VERSION ""

NS_ :

BS_:

BU_:

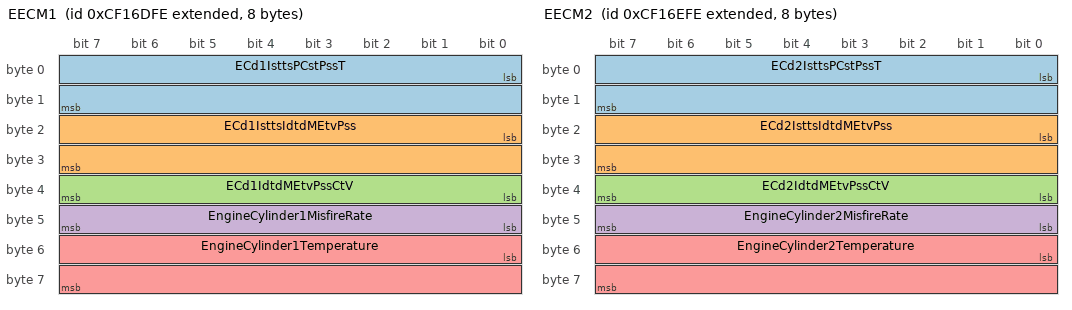
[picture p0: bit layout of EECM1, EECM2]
BO_ 2364632574 EECM1: 8 Vector__XXX
 SG_ ECd1IsttsPCstPssT : 0|16@1+ (0.00390625,-125) [-125|125] "deg" Vector__XXX
 SG_ ECd1IsttsIdtdMEtvPss : 16|16@1+ (0.0001220703125,-1) [-1|6.84362793] "MPa" Vector__XXX
 SG_ ECd1IdtdMEtvPssCtV : 32|8@1+ (0.04,0) [0|10] "%" Vector__XXX
 SG_ EngineCylinder1MisfireRate : 40|8@1+ (0.4,0) [0|100] "%" Vector__XXX
 SG_ EngineCylinder1Temperature : 48|16@1+ (0.03125,-273) [-273|1734.96875] "degC" Vector__XXX

BO_ 2364632830 EECM2: 8 Vector__XXX
 SG_ ECd2IsttsPCstPssT : 0|16@1+ (0.00390625,-125) [-125|125] "deg" Vector__XXX
 SG_ ECd2IsttsIdtdMEtvPss : 16|16@1+ (0.0001220703125,-1) [-1|6.84362793] "MPa" Vector__XXX
 SG_ ECd2IdtdMEtvPssCtV : 32|8@1+ (0.04,0) [0|10] "%" Vector__XXX
 SG_ EngineCylinder2MisfireRate : 40|8@1+ (0.4,0) [0|100] "%" Vector__XXX
 SG_ EngineCylinder2Temperature : 48|16@1+ (0.03125,-273) [-273|1734.96875] "degC" Vector__XXX

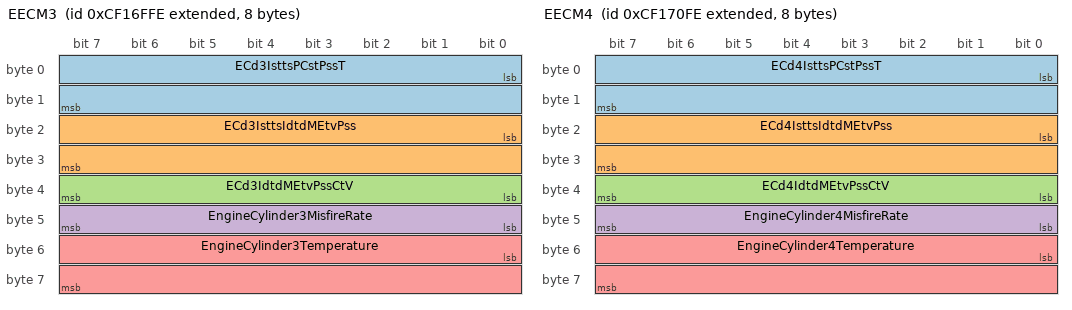
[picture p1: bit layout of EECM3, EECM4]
BO_ 2364633086 EECM3: 8 Vector__XXX
 SG_ ECd3IsttsPCstPssT : 0|16@1+ (0.00390625,-125) [-125|125] "deg" Vector__XXX
 SG_ ECd3IsttsIdtdMEtvPss : 16|16@1+ (0.0001220703125,-1) [-1|6.84362793] "MPa" Vector__XXX
 SG_ ECd3IdtdMEtvPssCtV : 32|8@1+ (0.04,0) [0|10] "%" Vector__XXX
 SG_ EngineCylinder3MisfireRate : 40|8@1+ (0.4,0) [0|100] "%" Vector__XXX
 SG_ EngineCylinder3Temperature : 48|16@1+ (0.03125,-273) [-273|1734.96875] "degC" Vector__XXX

BO_ 2364633342 EECM4: 8 Vector__XXX
 SG_ ECd4IsttsPCstPssT : 0|16@1+ (0.00390625,-125) [-125|125] "deg" Vector__XXX
 SG_ ECd4IsttsIdtdMEtvPss : 16|16@1+ (0.0001220703125,-1) [-1|6.84362793] "MPa" Vector__XXX
 SG_ ECd4IdtdMEtvPssCtV : 32|8@1+ (0.04,0) [0|10] "%" Vector__XXX
 SG_ EngineCylinder4MisfireRate : 40|8@1+ (0.4,0) [0|100] "%" Vector__XXX
 SG_ EngineCylinder4Temperature : 48|16@1+ (0.03125,-273) [-273|1734.96875] "degC" Vector__XXX

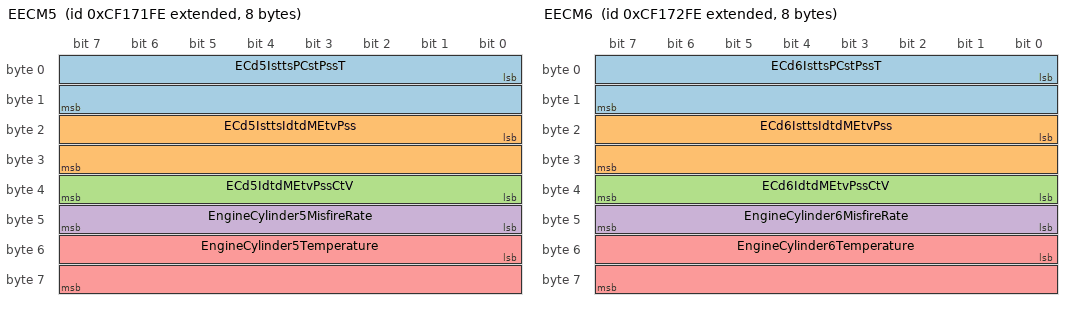
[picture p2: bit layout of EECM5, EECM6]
BO_ 2364633598 EECM5: 8 Vector__XXX
 SG_ ECd5IsttsPCstPssT : 0|16@1+ (0.00390625,-125) [-125|125] "deg" Vector__XXX
 SG_ ECd5IsttsIdtdMEtvPss : 16|16@1+ (0.0001220703125,-1) [-1|6.84362793] "MPa" Vector__XXX
 SG_ ECd5IdtdMEtvPssCtV : 32|8@1+ (0.04,0) [0|10] "%" Vector__XXX
 SG_ EngineCylinder5MisfireRate : 40|8@1+ (0.4,0) [0|100] "%" Vector__XXX
 SG_ EngineCylinder5Temperature : 48|16@1+ (0.03125,-273) [-273|1734.96875] "degC" Vector__XXX

BO_ 2364633854 EECM6: 8 Vector__XXX
 SG_ ECd6IsttsPCstPssT : 0|16@1+ (0.00390625,-125) [-125|125] "deg" Vector__XXX
 SG_ ECd6IsttsIdtdMEtvPss : 16|16@1+ (0.0001220703125,-1) [-1|6.84362793] "MPa" Vector__XXX
 SG_ ECd6IdtdMEtvPssCtV : 32|8@1+ (0.04,0) [0|10] "%" Vector__XXX
 SG_ EngineCylinder6MisfireRate : 40|8@1+ (0.4,0) [0|100] "%" Vector__XXX
 SG_ EngineCylinder6Temperature : 48|16@1+ (0.03125,-273) [-273|1734.96875] "degC" Vector__XXX

BO_ 2364634110 EECM7: 8 Vector__XXX
 SG_ ECd7IsttsPCstPssT : 0|16@1+ (0.00390625,-125) [-125|125] "deg" Vector__XXX
 SG_ ECd7IsttsIdtdMEtvPss : 16|16@1+ (0.0001220703125,-1) [-1|6.84362793] "MPa" Vector__XXX
 SG_ ECd7IdtdMEtvPssCtV : 32|8@1+ (0.04,0) [0|10] "%" Vector__XXX
 SG_ EngineCylinder7MisfireRate : 40|8@1+ (0.4,0) [0|100] "%" Vector__XXX
 SG_ EngineCylinder7Temperature : 48|16@1+ (0.03125,-273) [-273|1734.96875] "degC" Vector__XXX

BO_ 2364634366 EECM8: 8 Vector__XXX
 SG_ ECd8IsttsPCstPssT : 0|16@1+ (0.00390625,-125) [-125|125] "deg" Vector__XXX
 SG_ ECd8IsttsIdtdMEtvPss : 16|16@1+ (0.0001220703125,-1) [-1|6.84362793] "MPa" Vector__XXX
 SG_ ECd8IdtdMEtvPssCtV : 32|8@1+ (0.04,0) [0|10] "%" Vector__XXX
 SG_ EngineCylinder8MisfireRate : 40|8@1+ (0.4,0) [0|100] "%" Vector__XXX
 SG_ EngineCylinder8Temperature : 48|16@1+ (0.03125,-273) [-273|1734.96875] "degC" Vector__XXX

BO_ 2364634622 EECM9: 8 Vector__XXX
 SG_ ECd9IsttsPCstPssT : 0|16@1+ (0.00390625,-125) [-125|125] "deg" Vector__XXX
 SG_ ECd9IsttsIdtdMEtvPss : 16|16@1+ (0.0001220703125,-1) [-1|6.84362793] "MPa" Vector__XXX
 SG_ ECd9IdtdMEtvPssCtV : 32|8@1+ (0.04,0) [0|10] "%" Vector__XXX
 SG_ EngineCylinder9MisfireRate : 40|8@1+ (0.4,0) [0|100] "%" Vector__XXX
 SG_ EngineCylinder9Temperature : 48|16@1+ (0.03125,-273) [-273|1734.96875] "degC" Vector__XXX

BO_ 2364634878 EECM10: 8 Vector__XXX
 SG_ ECd10IsttsPCstPssT : 0|16@1+ (0.00390625,-125) [-125|125] "deg" Vector__XXX
 SG_ ECd10IsttsIdtdMEtvPss : 16|16@1+ (0.0001220703125,-1) [-1|6.84362793] "MPa" Vector__XXX
 SG_ ECd10IdtdMEtvPssCtV : 32|8@1+ (0.04,0) [0|10] "%" Vector__XXX
 SG_ EngineCylinder10MisfireRate : 40|8@1+ (0.4,0) [0|100] "%" Vector__XXX
 SG_ EngineCylinder10Temperature : 48|16@1+ (0.03125,-273) [-273|1734.96875] "degC" Vector__XXX

BO_ 2364635134 EECM11: 8 Vector__XXX
 SG_ ECd11IsttsPCstPssT : 0|16@1+ (0.00390625,-125) [-125|125] "deg" Vector__XXX
 SG_ ECd11IsttsIdtdMEtvPss : 16|16@1+ (0.0001220703125,-1) [-1|6.84362793] "MPa" Vector__XXX
 SG_ ECd11IdtdMEtvPssCtV : 32|8@1+ (0.04,0) [0|10] "%" Vector__XXX
 SG_ EngineCylinder11MisfireRate : 40|8@1+ (0.4,0) [0|100] "%" Vector__XXX
 SG_ EngineCylinder11Temperature : 48|16@1+ (0.03125,-273) [-273|1734.96875] "degC" Vector__XXX

BO_ 2364635390 EECM12: 8 Vector__XXX
 SG_ ECd12IsttsPCstPssT : 0|16@1+ (0.00390625,-125) [-125|125] "deg" Vector__XXX
 SG_ ECd12IsttsIdtdMEtvPss : 16|16@1+ (0.0001220703125,-1) [-1|6.84362793] "MPa" Vector__XXX
 SG_ ECd12IdtdMEtvPssCtV : 32|8@1+ (0.04,0) [0|10] "%" Vector__XXX
 SG_ EngineCylinder12MisfireRate : 40|8@1+ (0.4,0) [0|100] "%" Vector__XXX
 SG_ EngineCylinder12Temperature : 48|16@1+ (0.03125,-273) [-273|1734.96875] "degC" Vector__XXX

BO_ 2364635646 EECM13: 8 Vector__XXX
 SG_ ECd13IsttsPCstPssT : 0|16@1+ (0.00390625,-125) [-125|125] "deg" Vector__XXX
 SG_ ECd13IsttsIdtdMEtvPss : 16|16@1+ (0.0001220703125,-1) [-1|6.84362793] "MPa" Vector__XXX
 SG_ ECd13IdtdMEtvPssCtV : 32|8@1+ (0.04,0) [0|10] "%" Vector__XXX
 SG_ EngineCylinder13MisfireRate : 40|8@1+ (0.4,0) [0|100] "%" Vector__XXX
 SG_ EngineCylinder13Temperature : 48|16@1+ (0.03125,-273) [-273|1734.96875] "degC" Vector__XXX

BO_ 2364635902 EECM14: 8 Vector__XXX
 SG_ ECd14IsttsPCstPssT : 0|16@1+ (0.00390625,-125) [-125|125] "deg" Vector__XXX
 SG_ ECd14IsttsIdtdMEtvPss : 16|16@1+ (0.0001220703125,-1) [-1|6.84362793] "MPa" Vector__XXX
 SG_ ECd14IdtdMEtvPssCtV : 32|8@1+ (0.04,0) [0|10] "%" Vector__XXX
 SG_ EngineCylinder14MisfireRate : 40|8@1+ (0.4,0) [0|100] "%" Vector__XXX
 SG_ EngineCylinder14Temperature : 48|16@1+ (0.03125,-273) [-273|1734.96875] "degC" Vector__XXX

BO_ 2364636158 EECM15: 8 Vector__XXX
 SG_ ECd15IsttsPCstPssT : 0|16@1+ (0.00390625,-125) [-125|125] "deg" Vector__XXX
 SG_ ECd15IsttsIdtdMEtvPss : 16|16@1+ (0.0001220703125,-1) [-1|6.84362793] "MPa" Vector__XXX
 SG_ ECd15IdtdMEtvPssCtV : 32|8@1+ (0.04,0) [0|10] "%" Vector__XXX
 SG_ EngineCylinder15MisfireRate : 40|8@1+ (0.4,0) [0|100] "%" Vector__XXX
 SG_ EngineCylinder15Temperature : 48|16@1+ (0.03125,-273) [-273|1734.96875] "degC" Vector__XXX

BO_ 2364636414 EECM16: 8 Vector__XXX
 SG_ ECd16IsttsPCstPssT : 0|16@1+ (0.00390625,-125) [-125|125] "deg" Vector__XXX
 SG_ ECd16IsttsIdtdMEtvPss : 16|16@1+ (0.0001220703125,-1) [-1|6.84362793] "MPa" Vector__XXX
 SG_ ECd16IdtdMEtvPssCtV : 32|8@1+ (0.04,0) [0|10] "%" Vector__XXX
 SG_ EngineCylinder16MisfireRate : 40|8@1+ (0.4,0) [0|100] "%" Vector__XXX
 SG_ EngineCylinder16Temperature : 48|16@1+ (0.03125,-273) [-273|1734.96875] "degC" Vector__XXX

BO_ 2364636670 EECM17: 8 Vector__XXX
 SG_ ECd17IsttsPCstPssT : 0|16@1+ (0.00390625,-125) [-125|125] "deg" Vector__XXX
 SG_ ECd17IsttsIdtdMEtvPss : 16|16@1+ (0.0001220703125,-1) [-1|6.84362793] "MPa" Vector__XXX
 SG_ ECd17IdtdMEtvPssCtV : 32|8@1+ (0.04,0) [0|10] "%" Vector__XXX
 SG_ EngineCylinder17MisfireRate : 40|8@1+ (0.4,0) [0|100] "%" Vector__XXX
 SG_ EngineCylinder17Temperature : 48|16@1+ (0.03125,-273) [-273|1734.96875] "degC" Vector__XXX

BO_ 2364636926 EECM18: 8 Vector__XXX
 SG_ ECd18IsttsPCstPssT : 0|16@1+ (0.00390625,-125) [-125|125] "deg" Vector__XXX
 SG_ ECd18IsttsIdtdMEtvPss : 16|16@1+ (0.0001220703125,-1) [-1|6.84362793] "MPa" Vector__XXX
 SG_ ECd18IdtdMEtvPssCtV : 32|8@1+ (0.04,0) [0|10] "%" Vector__XXX
 SG_ EngineCylinder18MisfireRate : 40|8@1+ (0.4,0) [0|100] "%" Vector__XXX
 SG_ EngineCylinder18Temperature : 48|16@1+ (0.03125,-273) [-273|1734.96875] "degC" Vector__XXX

BO_ 2364637182 EECM19: 8 Vector__XXX
 SG_ ECd19IsttsPCstPssT : 0|16@1+ (0.00390625,-125) [-125|125] "deg" Vector__XXX
 SG_ ECd19IsttsIdtdMEtvPss : 16|16@1+ (0.0001220703125,-1) [-1|6.84362793] "MPa" Vector__XXX
 SG_ ECd19IdtdMEtvPssCtV : 32|8@1+ (0.04,0) [0|10] "%" Vector__XXX
 SG_ EngineCylinder19MisfireRate : 40|8@1+ (0.4,0) [0|100] "%" Vector__XXX
 SG_ EngineCylinder19Temperature : 48|16@1+ (0.03125,-273) [-273|1734.96875] "degC" Vector__XXX

BO_ 2364637438 EECM20: 8 Vector__XXX
 SG_ ECd20IsttsPCstPssT : 0|16@1+ (0.00390625,-125) [-125|125] "deg" Vector__XXX
 SG_ ECd20IsttsIdtdMEtvPss : 16|16@1+ (0.0001220703125,-1) [-1|6.84362793] "MPa" Vector__XXX
 SG_ ECd20IdtdMEtvPssCtV : 32|8@1+ (0.04,0) [0|10] "%" Vector__XXX
 SG_ EngineCylinder20MisfireRate : 40|8@1+ (0.4,0) [0|100] "%" Vector__XXX
 SG_ EngineCylinder20Temperature : 48|16@1+ (0.03125,-273) [-273|1734.96875] "degC" Vector__XXX

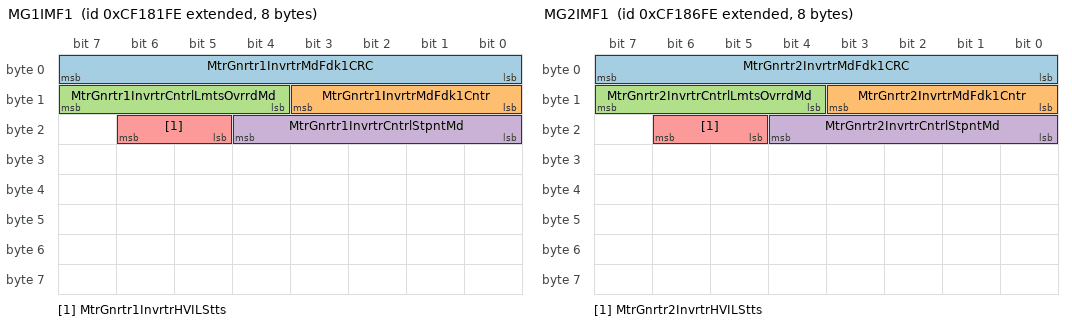
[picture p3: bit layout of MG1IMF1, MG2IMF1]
BO_ 2364637694 MG1IMF1: 8 Vector__XXX
 SG_ MtrGnrtr1InvrtrMdFdk1CRC : 0|8@1+ (1,0) [0|255] "count" Vector__XXX
 SG_ MtrGnrtr1InvrtrMdFdk1Cntr : 8|4@1+ (1,0) [0|15] "" Vector__XXX
 SG_ MtrGnrtr1InvrtrCntrlLmtsOvrrdMd : 12|4@1+ (1,0) [0|15] "" Vector__XXX
 SG_ MtrGnrtr1InvrtrCntrlStpntMd : 16|5@1+ (1,0) [0|31] "" Vector__XXX
 SG_ MtrGnrtr1InvrtrHVILStts : 21|2@1+ (1,0) [0|3] "" Vector__XXX

BO_ 2565964542 MG1ILAP: 8 Vector__XXX
 SG_ MtrGnrtr1InvrtrLmtsAtvPwrCRC : 0|8@1+ (1,0) [0|255] "count" Vector__XXX
 SG_ MtrGnrtr1InvrtrLmtsAtvPwrCntr : 8|4@1+ (1,0) [0|15] "" Vector__XXX

BO_ 2565964798 MG1ILAM: 8 Vector__XXX
 SG_ MtrGnrtr1InvrtrLmtsAtvMhnlCRC : 0|8@1+ (1,0) [0|255] "count" Vector__XXX
 SG_ MtrGnrtr1InvrtrLmtsAtvMhnlCntr : 8|4@1+ (1,0) [0|15] "" Vector__XXX

BO_ 2565965054 MG1ILADC: 8 Vector__XXX
 SG_ MtrGnrtr1InvrtrLmtsAtvDCSdCRC : 0|8@1+ (1,0) [0|255] "count" Vector__XXX
 SG_ MtrGnrtr1InvrtrLmtsAtvDCSdCntr : 8|4@1+ (1,0) [0|15] "" Vector__XXX

BO_ 2565965310 MG1ILV: 8 Vector__XXX
 SG_ MtrGnrtr1InvrtrSwthdIgntnVltg : 0|16@1+ (0.05,0) [0|3212.75] "V" Vector__XXX
 SG_ MtrGnrtr1InvrtrUnswthdSLIVltg : 16|16@1+ (0.05,0) [0|3212.75] "V" Vector__XXX

BO_ 2364638974 MG2IMF1: 8 Vector__XXX
 SG_ MtrGnrtr2InvrtrMdFdk1CRC : 0|8@1+ (1,0) [0|255] "count" Vector__XXX
 SG_ MtrGnrtr2InvrtrMdFdk1Cntr : 8|4@1+ (1,0) [0|15] "" Vector__XXX
 SG_ MtrGnrtr2InvrtrCntrlLmtsOvrrdMd : 12|4@1+ (1,0) [0|15] "" Vector__XXX
 SG_ MtrGnrtr2InvrtrCntrlStpntMd : 16|5@1+ (1,0) [0|31] "" Vector__XXX
 SG_ MtrGnrtr2InvrtrHVILStts : 21|2@1+ (1,0) [0|3] "" Vector__XXX

BO_ 2565965822 MG2ILAP: 8 Vector__XXX
 SG_ MtrGnrtr2InvrtrLmtsAtvPwrCRC : 0|8@1+ (1,0) [0|255] "count" Vector__XXX
 SG_ MtrGnrtr2InvrtrLmtsAtvPwrCntr : 8|4@1+ (1,0) [0|15] "" Vector__XXX

BO_ 2565966078 MG2ILAM: 8 Vector__XXX
 SG_ MtrGnrtr2InvrtrLmtsAtvMhnlCRC : 0|8@1+ (1,0) [0|255] "count" Vector__XXX
 SG_ MtrGnrtr2InvrtrLmtsAtvMhnlCntr : 8|4@1+ (1,0) [0|15] "" Vector__XXX

BO_ 2565966334 MG2ILADC: 8 Vector__XXX
 SG_ MtrGnrtr2InvrtrLmtsAtvDCSdCRC : 0|8@1+ (1,0) [0|255] "count" Vector__XXX
 SG_ MtrGnrtr2InvrtrLmtsAtvDCSdCntr : 8|4@1+ (1,0) [0|15] "" Vector__XXX

BO_ 2565966590 MG2ILV: 8 Vector__XXX
 SG_ MtrGnrtr2InvrtrSwthdIgntnVltg : 0|16@1+ (0.05,0) [0|3212.75] "V" Vector__XXX
 SG_ MtrGnrtr2InvrtrUnswthdSLIVltg : 16|16@1+ (0.05,0) [0|3212.75] "V" Vector__XXX

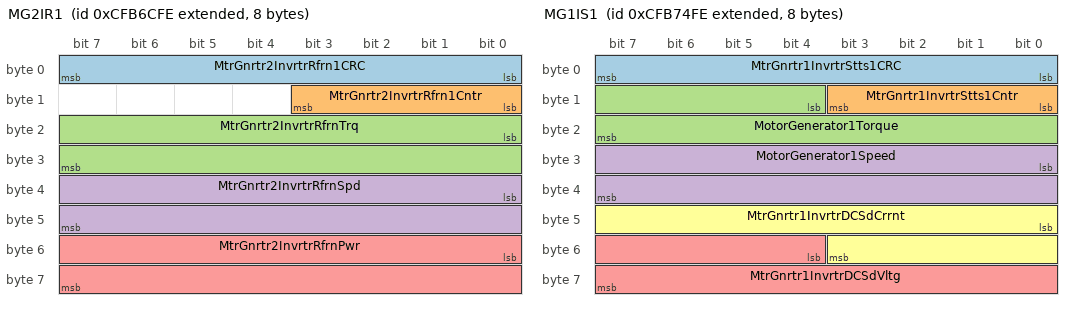
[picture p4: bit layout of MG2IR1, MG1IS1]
BO_ 2365287678 MG2IR1: 8 Vector__XXX
 SG_ MtrGnrtr2InvrtrRfrn1CRC : 0|8@1+ (1,0) [0|255] "count" Vector__XXX
 SG_ MtrGnrtr2InvrtrRfrn1Cntr : 8|4@1+ (1,0) [0|15] "" Vector__XXX
 SG_ MtrGnrtr2InvrtrRfrnTrq : 16|16@1+ (0.5,0) [0|32127.5] "Nm" Vector__XXX
 SG_ MtrGnrtr2InvrtrRfrnSpd : 32|16@1+ (4,0) [0|257020] "rpm" Vector__XXX
 SG_ MtrGnrtr2InvrtrRfrnPwr : 48|16@1+ (0.0625,0) [0|4015.9375] "kW" Vector__XXX

BO_ 2365287934 MG2IS1: 8 Vector__XXX
 SG_ MtrGnrtr2InvrtrStts1CRC : 0|8@1+ (1,0) [0|255] "count" Vector__XXX
 SG_ MtrGnrtr2InvrtrStts1Cntr : 8|4@1+ (1,0) [0|15] "" Vector__XXX
 SG_ MotorGenerator2Speed : 24|16@1+ (0.00390625,-125) [-125|125.99609375] "%" Vector__XXX

BO_ 2365288190 MG2IR2: 8 Vector__XXX
 SG_ MtrGnrtr2InvrtrRfrn2CRC : 0|8@1+ (1,0) [0|255] "count" Vector__XXX
 SG_ MtrGnrtr2InvrtrRfrn2Cntr : 8|4@1+ (1,0) [0|15] "" Vector__XXX
 SG_ MtrGnrtr2InvrtrRfrnCrrnt : 32|16@1+ (0.125,0) [0|8031.875] "A" Vector__XXX
 SG_ MtrGnrtr2InvrtrRfrnVltg : 48|16@1+ (0.125,0) [0|8031.875] "V" Vector__XXX

BO_ 2566615038 MG2IT: 8 Vector__XXX
 SG_ MtrGnrtr2InvrtrTmprtr1 : 0|8@1+ (1,-40) [-40|210] "degC" Vector__XXX
 SG_ MtrGnrtr2InvrtrTmprtr2 : 8|8@1+ (1,-40) [-40|210] "degC" Vector__XXX
 SG_ MtrGnrtr2InvrtrTmprtr3 : 16|8@1+ (1,-40) [-40|210] "degC" Vector__XXX
 SG_ MtrGnrtr2InvrtrTmprtr4 : 24|8@1+ (1,-40) [-40|210] "degC" Vector__XXX

BO_ 2566615294 MG2IMT: 8 Vector__XXX
 SG_ MotorGenerator2Temperature1 : 0|8@1+ (1,-40) [-40|210] "degC" Vector__XXX
 SG_ MotorGenerator2Temperature2 : 8|8@1+ (1,-40) [-40|210] "degC" Vector__XXX
 SG_ MotorGenerator2Temperature3 : 16|8@1+ (1,-40) [-40|210] "degC" Vector__XXX
 SG_ MotorGenerator2Temperature4 : 24|8@1+ (1,-40) [-40|210] "degC" Vector__XXX

BO_ 2566615550 MG1IMT: 8 Vector__XXX
 SG_ MotorGenerator1Temperature1 : 0|8@1+ (1,-40) [-40|210] "degC" Vector__XXX
 SG_ MotorGenerator1Temperature2 : 8|8@1+ (1,-40) [-40|210] "degC" Vector__XXX
 SG_ MotorGenerator1Temperature3 : 16|8@1+ (1,-40) [-40|210] "degC" Vector__XXX
 SG_ MotorGenerator1Temperature4 : 24|8@1+ (1,-40) [-40|210] "degC" Vector__XXX

BO_ 2566615806 MG1IT: 8 Vector__XXX
 SG_ MtrGnrtr1InvrtrTmprtr1 : 0|8@1+ (1,-40) [-40|210] "degC" Vector__XXX
 SG_ MtrGnrtr1InvrtrTmprtr2 : 8|8@1+ (1,-40) [-40|210] "degC" Vector__XXX
 SG_ MtrGnrtr1InvrtrTmprtr3 : 16|8@1+ (1,-40) [-40|210] "degC" Vector__XXX
 SG_ MtrGnrtr1InvrtrTmprtr4 : 24|8@1+ (1,-40) [-40|210] "degC" Vector__XXX

BO_ 2365289470 MG1IR2: 8 Vector__XXX
 SG_ MtrGnrtr1InvrtrRfrn2CRC : 0|8@1+ (1,0) [0|255] "count" Vector__XXX
 SG_ MtrGnrtr1InvrtrRfrn2Cntr : 8|4@1+ (1,0) [0|15] "" Vector__XXX
 SG_ MtrGnrtr1InvrtrRfrnCrrnt : 32|16@1+ (0.125,0) [0|8031.875] "A" Vector__XXX
 SG_ MtrGnrtr1InvrtrRfrnVltg : 48|16@1+ (0.125,0) [0|8031.875] "V" Vector__XXX

BO_ 2365289726 MG1IS1: 8 Vector__XXX
 SG_ MtrGnrtr1InvrtrStts1CRC : 0|8@1+ (1,0) [0|255] "count" Vector__XXX
 SG_ MtrGnrtr1InvrtrStts1Cntr : 8|4@1+ (1,0) [0|15] "" Vector__XXX
 SG_ MotorGenerator1Torque : 12|12@1+ (42370,-125) [-125|125.9375] "%" Vector__XXX
 SG_ MotorGenerator1Speed : 24|16@1+ (0.00390625,-125) [-125|125.99609375] "%" Vector__XXX
 SG_ MtrGnrtr1InvrtrDCSdVltg : 52|12@1+ (42370,-125) [-125|125.9375] "%" Vector__XXX
 SG_ MtrGnrtr1InvrtrDCSdCrrnt : 40|12@1+ (42370,-125) [-125|125.9375] "%" Vector__XXX

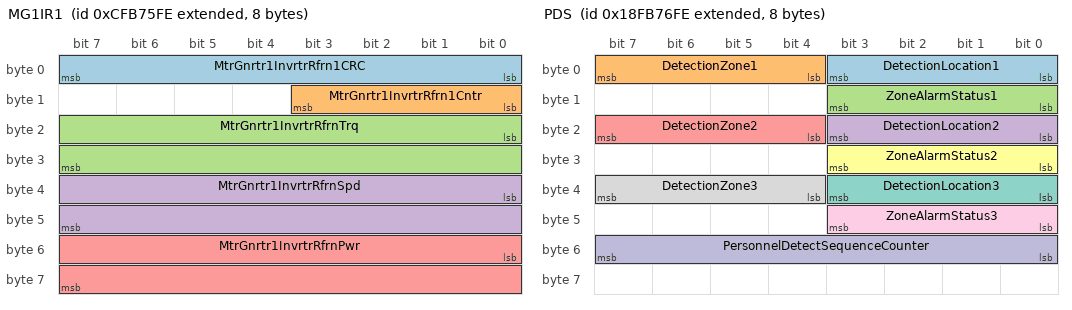
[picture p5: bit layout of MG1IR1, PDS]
BO_ 2365289982 MG1IR1: 8 Vector__XXX
 SG_ MtrGnrtr1InvrtrRfrn1CRC : 0|8@1+ (1,0) [0|255] "count" Vector__XXX
 SG_ MtrGnrtr1InvrtrRfrn1Cntr : 8|4@1+ (1,0) [0|15] "" Vector__XXX
 SG_ MtrGnrtr1InvrtrRfrnTrq : 16|16@1+ (0.5,0) [0|32127.5] "Nm" Vector__XXX
 SG_ MtrGnrtr1InvrtrRfrnSpd : 32|16@1+ (4,0) [0|257020] "rpm" Vector__XXX
 SG_ MtrGnrtr1InvrtrRfrnPwr : 48|16@1+ (0.0625,0) [0|4015.9375] "kW" Vector__XXX

BO_ 2566616830 PDS: 8 Vector__XXX
 SG_ DetectionLocation1 : 0|4@1+ (1,0) [0|13] "count" Vector__XXX
 SG_ DetectionZone1 : 4|4@1+ (1,0) [0|13] "count" Vector__XXX
 SG_ ZoneAlarmStatus1 : 8|4@1+ (1,0) [0|15] "" Vector__XXX
 SG_ DetectionLocation2 : 16|4@1+ (1,0) [0|13] "count" Vector__XXX
 SG_ DetectionZone2 : 20|4@1+ (1,0) [0|13] "count" Vector__XXX
 SG_ ZoneAlarmStatus2 : 24|4@1+ (1,0) [0|15] "" Vector__XXX
 SG_ DetectionLocation3 : 32|4@1+ (1,0) [0|13] "count" Vector__XXX
 SG_ DetectionZone3 : 36|4@1+ (1,0) [0|13] "count" Vector__XXX
 SG_ ZoneAlarmStatus3 : 40|4@1+ (1,0) [0|15] "" Vector__XXX
 SG_ PersonnelDetectSequenceCounter : 48|8@1+ (1,0) [0|255] "count" Vector__XXX

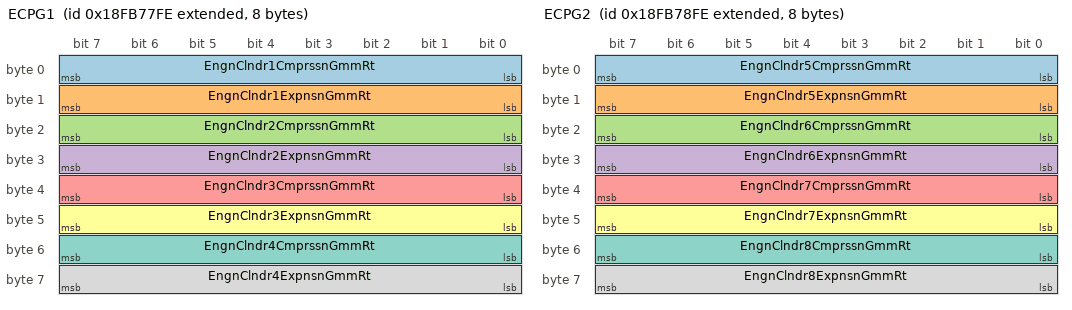
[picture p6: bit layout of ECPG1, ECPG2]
BO_ 2566617086 ECPG1: 8 Vector__XXX
 SG_ EngnClndr1CmprssnGmmRt : 0|8@1+ (0.004,1) [1|2] "Ratio" Vector__XXX
 SG_ EngnClndr1ExpnsnGmmRt : 8|8@1+ (0.004,1) [1|2] "Ratio" Vector__XXX
 SG_ EngnClndr2CmprssnGmmRt : 16|8@1+ (0.004,1) [1|2] "Ratio" Vector__XXX
 SG_ EngnClndr2ExpnsnGmmRt : 24|8@1+ (0.004,1) [1|2] "Ratio" Vector__XXX
 SG_ EngnClndr3CmprssnGmmRt : 32|8@1+ (0.004,1) [1|2] "Ratio" Vector__XXX
 SG_ EngnClndr3ExpnsnGmmRt : 40|8@1+ (0.004,1) [1|2] "Ratio" Vector__XXX
 SG_ EngnClndr4CmprssnGmmRt : 48|8@1+ (0.004,1) [1|2] "Ratio" Vector__XXX
 SG_ EngnClndr4ExpnsnGmmRt : 56|8@1+ (0.004,1) [1|2] "Ratio" Vector__XXX

BO_ 2566617342 ECPG2: 8 Vector__XXX
 SG_ EngnClndr5CmprssnGmmRt : 0|8@1+ (0.004,1) [1|2] "Ratio" Vector__XXX
 SG_ EngnClndr5ExpnsnGmmRt : 8|8@1+ (0.004,1) [1|2] "Ratio" Vector__XXX
 SG_ EngnClndr6CmprssnGmmRt : 16|8@1+ (0.004,1) [1|2] "Ratio" Vector__XXX
 SG_ EngnClndr6ExpnsnGmmRt : 24|8@1+ (0.004,1) [1|2] "Ratio" Vector__XXX
 SG_ EngnClndr7CmprssnGmmRt : 32|8@1+ (0.004,1) [1|2] "Ratio" Vector__XXX
 SG_ EngnClndr7ExpnsnGmmRt : 40|8@1+ (0.004,1) [1|2] "Ratio" Vector__XXX
 SG_ EngnClndr8CmprssnGmmRt : 48|8@1+ (0.004,1) [1|2] "Ratio" Vector__XXX
 SG_ EngnClndr8ExpnsnGmmRt : 56|8@1+ (0.004,1) [1|2] "Ratio" Vector__XXX

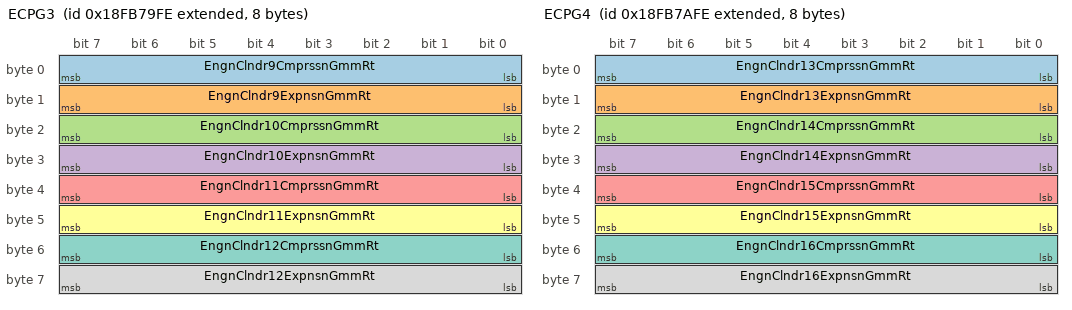
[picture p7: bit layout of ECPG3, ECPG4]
BO_ 2566617598 ECPG3: 8 Vector__XXX
 SG_ EngnClndr9CmprssnGmmRt : 0|8@1+ (0.004,1) [1|2] "Ratio" Vector__XXX
 SG_ EngnClndr9ExpnsnGmmRt : 8|8@1+ (0.004,1) [1|2] "Ratio" Vector__XXX
 SG_ EngnClndr10CmprssnGmmRt : 16|8@1+ (0.004,1) [1|2] "Ratio" Vector__XXX
 SG_ EngnClndr10ExpnsnGmmRt : 24|8@1+ (0.004,1) [1|2] "Ratio" Vector__XXX
 SG_ EngnClndr11CmprssnGmmRt : 32|8@1+ (0.004,1) [1|2] "Ratio" Vector__XXX
 SG_ EngnClndr11ExpnsnGmmRt : 40|8@1+ (0.004,1) [1|2] "Ratio" Vector__XXX
 SG_ EngnClndr12CmprssnGmmRt : 48|8@1+ (0.004,1) [1|2] "Ratio" Vector__XXX
 SG_ EngnClndr12ExpnsnGmmRt : 56|8@1+ (0.004,1) [1|2] "Ratio" Vector__XXX

BO_ 2566617854 ECPG4: 8 Vector__XXX
 SG_ EngnClndr13CmprssnGmmRt : 0|8@1+ (0.004,1) [1|2] "Ratio" Vector__XXX
 SG_ EngnClndr13ExpnsnGmmRt : 8|8@1+ (0.004,1) [1|2] "Ratio" Vector__XXX
 SG_ EngnClndr14CmprssnGmmRt : 16|8@1+ (0.004,1) [1|2] "Ratio" Vector__XXX
 SG_ EngnClndr14ExpnsnGmmRt : 24|8@1+ (0.004,1) [1|2] "Ratio" Vector__XXX
 SG_ EngnClndr15CmprssnGmmRt : 32|8@1+ (0.004,1) [1|2] "Ratio" Vector__XXX
 SG_ EngnClndr15ExpnsnGmmRt : 40|8@1+ (0.004,1) [1|2] "Ratio" Vector__XXX
 SG_ EngnClndr16CmprssnGmmRt : 48|8@1+ (0.004,1) [1|2] "Ratio" Vector__XXX
 SG_ EngnClndr16ExpnsnGmmRt : 56|8@1+ (0.004,1) [1|2] "Ratio" Vector__XXX

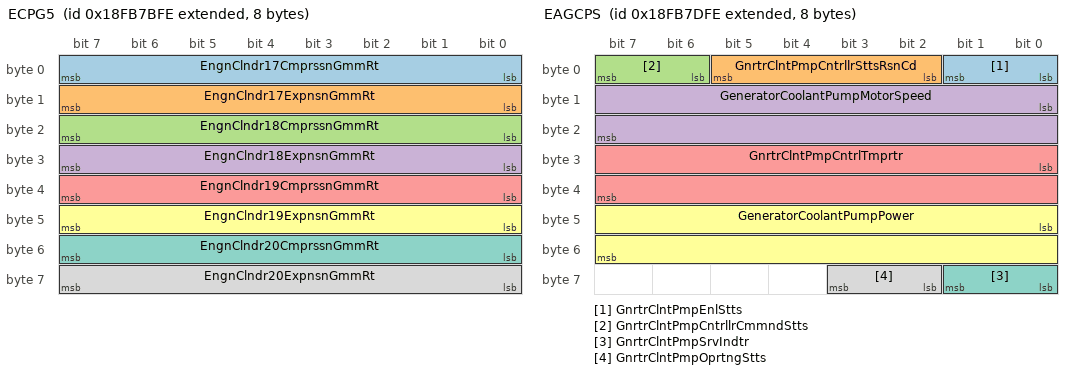
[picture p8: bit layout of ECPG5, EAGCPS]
BO_ 2566618110 ECPG5: 8 Vector__XXX
 SG_ EngnClndr17CmprssnGmmRt : 0|8@1+ (0.004,1) [1|2] "Ratio" Vector__XXX
 SG_ EngnClndr17ExpnsnGmmRt : 8|8@1+ (0.004,1) [1|2] "Ratio" Vector__XXX
 SG_ EngnClndr18CmprssnGmmRt : 16|8@1+ (0.004,1) [1|2] "Ratio" Vector__XXX
 SG_ EngnClndr18ExpnsnGmmRt : 24|8@1+ (0.004,1) [1|2] "Ratio" Vector__XXX
 SG_ EngnClndr19CmprssnGmmRt : 32|8@1+ (0.004,1) [1|2] "Ratio" Vector__XXX
 SG_ EngnClndr19ExpnsnGmmRt : 40|8@1+ (0.004,1) [1|2] "Ratio" Vector__XXX
 SG_ EngnClndr20CmprssnGmmRt : 48|8@1+ (0.004,1) [1|2] "Ratio" Vector__XXX
 SG_ EngnClndr20ExpnsnGmmRt : 56|8@1+ (0.004,1) [1|2] "Ratio" Vector__XXX

BO_ 2566618622 EAGCPS: 8 Vector__XXX
 SG_ GnrtrClntPmpEnlStts : 0|2@1+ (1,0) [0|3] "" Vector__XXX
 SG_ GnrtrClntPmpCntrllrSttsRsnCd : 2|4@1+ (1,0) [0|15] "" Vector__XXX
 SG_ GnrtrClntPmpCntrllrCmmndStts : 6|2@1+ (1,0) [0|3] "" Vector__XXX
 SG_ GeneratorCoolantPumpMotorSpeed : 8|16@1+ (0.5,0) [0|32127.5] "rpm" Vector__XXX
 SG_ GnrtrClntPmpCntrlTmprtr : 24|16@1+ (0.03125,-273) [-273|1734.96875] "degC" Vector__XXX
 SG_ GeneratorCoolantPumpPower : 40|16@1+ (0.5,0) [0|32127.5] "W" Vector__XXX
 SG_ GnrtrClntPmpSrvIndtr : 56|2@1+ (1,0) [0|3] "" Vector__XXX
 SG_ GnrtrClntPmpOprtngStts : 58|2@1+ (1,0) [0|3] "" Vector__XXX

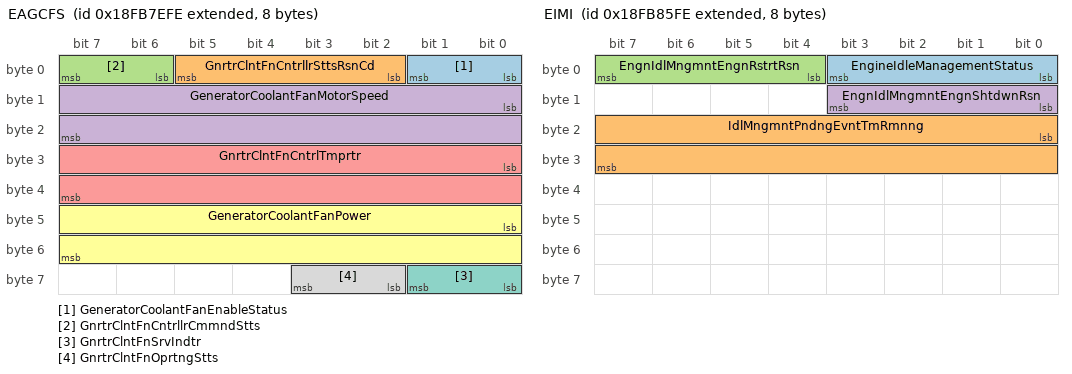
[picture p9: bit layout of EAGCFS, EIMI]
BO_ 2566618878 EAGCFS: 8 Vector__XXX
 SG_ GeneratorCoolantFanEnableStatus : 0|2@1+ (1,0) [0|3] "" Vector__XXX
 SG_ GnrtrClntFnCntrllrSttsRsnCd : 2|4@1+ (1,0) [0|15] "" Vector__XXX
 SG_ GnrtrClntFnCntrllrCmmndStts : 6|2@1+ (1,0) [0|3] "" Vector__XXX
 SG_ GeneratorCoolantFanMotorSpeed : 8|16@1+ (0.5,0) [0|32127.5] "rpm" Vector__XXX
 SG_ GnrtrClntFnCntrlTmprtr : 24|16@1+ (0.03125,-273) [-273|1734.96875] "degC" Vector__XXX
 SG_ GeneratorCoolantFanPower : 40|16@1+ (0.5,0) [0|32127.5] "W" Vector__XXX
 SG_ GnrtrClntFnSrvIndtr : 56|2@1+ (1,0) [0|3] "" Vector__XXX
 SG_ GnrtrClntFnOprtngStts : 58|2@1+ (1,0) [0|3] "" Vector__XXX

BO_ 2566619134 WSPF: 8 Vector__XXX
 SG_ WllStmltnPmpOlFltrDffrntlPrssr : 0|8@1+ (4,0) [0|1000] "kPa" Vector__XXX
 SG_ WllStmltnPmpOlFltrBpssSwthStts : 24|2@1+ (1,0) [0|3] "" Vector__XXX
 SG_ WllStmltnPmpGrBxOtltOlPrssr : 8|16@1+ (0.1,0) [0|6425.5] "kPa" Vector__XXX

BO_ 2566619390 PTOGC: 22 Vector__XXX
 SG_ PrprgrmmdPTOGvrnrStSpd1 : 0|16@1+ (0.125,0) [0|8031.875] "rpm" Vector__XXX
 SG_ PrprgrmmdPTOGvrnrStSpd2 : 16|16@1+ (0.125,0) [0|8031.875] "rpm" Vector__XXX
 SG_ PrprgrmmdPTOGvrnrStSpd3 : 32|16@1+ (0.125,0) [0|8031.875] "rpm" Vector__XXX
 SG_ PrprgrmmdPTOGvrnrStSpd4 : 48|16@1+ (0.125,0) [0|8031.875] "rpm" Vector__XXX
 SG_ PrprgrmmdPTOGvrnrStSpd5 : 64|16@1+ (0.125,0) [0|8031.875] "rpm" Vector__XXX
 SG_ PrprgrmmdPTOGvrnrStSpd6 : 80|16@1+ (0.125,0) [0|8031.875] "rpm" Vector__XXX
 SG_ PrprgrmmdPTOGvrnrStSpd7 : 96|16@1+ (0.125,0) [0|8031.875] "rpm" Vector__XXX
 SG_ PrprgrmmdPTOGvrnrStSpd8 : 112|16@1+ (0.125,0) [0|8031.875] "rpm" Vector__XXX
 SG_ MinimumPTOGovernorSetSpeed : 128|16@1+ (0.125,0) [0|8031.875] "rpm" Vector__XXX
 SG_ MaximumPTOGovernorSetSpeed : 144|16@1+ (0.125,0) [0|8031.875] "rpm" Vector__XXX
 SG_ PTOGvrnrAlrtrOvrrdMxmmSpd : 160|16@1+ (0.125,0) [0|8031.875] "rpm" Vector__XXX

BO_ 2566619646 OBP2: 8 Vector__XXX
 SG_ OnBrdPrgrmmngInttECUAddrss : 0|8@1+ (1,0) [0|255] "SA" Vector__XXX
 SG_ OnBrdPrgrmmngInttRqst : 8|2@1+ (1,0) [0|3] "" Vector__XXX
 SG_ OnBrdPrgrmmngInttInht : 10|2@1+ (1,0) [0|3] "" Vector__XXX

BO_ 2566620670 EIMI: 8 Vector__XXX
 SG_ EngineIdleManagementStatus : 0|4@1+ (1,0) [0|15] "" Vector__XXX
 SG_ IdlMngmntPndngEvntTmRmnng : 16|16@1+ (1,0) [0|64255] "s" Vector__XXX
 SG_ EngnIdlMngmntEngnRstrtRsn : 4|4@1+ (1,0) [0|15] "" Vector__XXX
 SG_ EngnIdlMngmntEngnShtdwnRsn : 8|4@1+ (1,0) [0|15] "" Vector__XXX

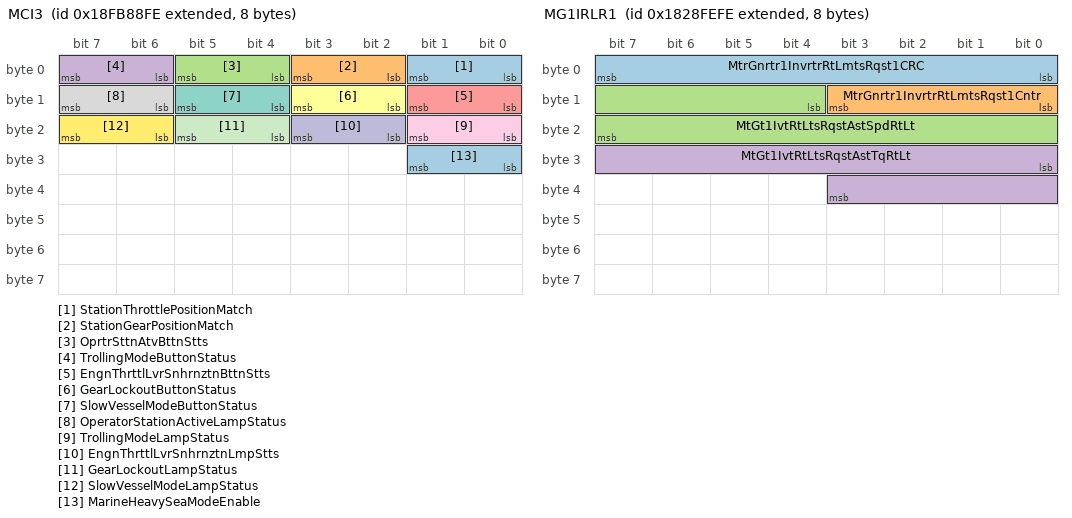
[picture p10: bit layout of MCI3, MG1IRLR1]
BO_ 2566621438 MCI3: 8 Vector__XXX
 SG_ StationThrottlePositionMatch : 0|2@1+ (1,0) [0|3] "" Vector__XXX
 SG_ StationGearPositionMatch : 2|2@1+ (1,0) [0|3] "" Vector__XXX
 SG_ OprtrSttnAtvBttnStts : 4|2@1+ (1,0) [0|3] "" Vector__XXX
 SG_ TrollingModeButtonStatus : 6|2@1+ (1,0) [0|3] "" Vector__XXX
 SG_ EngnThrttlLvrSnhrnztnBttnStts : 8|2@1+ (1,0) [0|3] "" Vector__XXX
 SG_ GearLockoutButtonStatus : 10|2@1+ (1,0) [0|3] "" Vector__XXX
 SG_ SlowVesselModeButtonStatus : 12|2@1+ (1,0) [0|3] "" Vector__XXX
 SG_ OperatorStationActiveLampStatus : 14|2@1+ (1,0) [0|3] "" Vector__XXX
 SG_ TrollingModeLampStatus : 16|2@1+ (1,0) [0|3] "" Vector__XXX
 SG_ EngnThrttlLvrSnhrnztnLmpStts : 18|2@1+ (1,0) [0|3] "" Vector__XXX
 SG_ GearLockoutLampStatus : 20|2@1+ (1,0) [0|3] "" Vector__XXX
 SG_ SlowVesselModeLampStatus : 22|2@1+ (1,0) [0|3] "" Vector__XXX
 SG_ MarineHeavySeaModeEnable : 24|2@1+ (1,0) [0|3] "" Vector__XXX

BO_ 2566621694 EFLP13: 8 Vector__XXX
 SG_ EngineOilPressure2 : 0|8@1+ (4,0) [0|1000] "kPa" Vector__XXX

BO_ 2365295358 HVESSD11: 8 Vector__XXX
 SG_ HVESSBsVltgNgtvtChsssGrndVltg : 0|16@1+ (0.05,0) [0|3212.75] "V" Vector__XXX
 SG_ HVESSVltgLvlNgtvtChsssGrndVltg : 16|16@1+ (0.05,0) [0|3212.75] "V" Vector__XXX

BO_ 2566622206 EMIH: 8 Vector__XXX
 SG_ EconomyModeTotalHoursInactive : 0|32@1+ (0.05,0) [0|210554060.75] "h" Vector__XXX
 SG_ EconomyModeTripHoursInactive : 32|32@1+ (0.05,0) [0|210554060.75] "h" Vector__XXX

BO_ 2566622462 EMEIFSR: 8 Vector__XXX
 SG_ EnmMdEstmtdInstntnsFlSvngsRt : 0|16@1+ (0.05,0) [0|3212.75] "l/h" Vector__XXX
 SG_ EMdEsttdIsttsFSvsRtPt : 16|16@1+ (0.0025,0) [0|160.6375] "%" Vector__XXX

BO_ 2566622718 EMAH: 8 Vector__XXX
 SG_ EconomyModeTotalHoursActive : 0|32@1+ (0.05,0) [0|210554060.75] "h" Vector__XXX
 SG_ EconomyModeTripHoursActive : 32|32@1+ (0.05,0) [0|210554060.75] "h" Vector__XXX

BO_ 2566622974 EMFU: 8 Vector__XXX
 SG_ EconomyModeTotalFuelUsed : 0|32@1+ (0.5,0) [0|2105540607.5] "l" Vector__XXX
 SG_ EconomyModeTripFuelUsed : 32|32@1+ (0.5,0) [0|2105540607.5] "l" Vector__XXX

BO_ 2566623230 EMEFS: 8 Vector__XXX
 SG_ EnmMdTtlEstmtdFlSvd : 0|32@1+ (0.5,0) [0|2105540607.5] "l" Vector__XXX
 SG_ EnmMdTrpEstmtdFlSvd : 32|32@1+ (0.5,0) [0|2105540607.5] "l" Vector__XXX

BO_ 2552823550 MG1IRLR1: 8 Vector__XXX
 SG_ MtrGnrtr1InvrtrRtLmtsRqst1CRC : 0|8@1+ (1,0) [0|255] "count" Vector__XXX
 SG_ MtrGnrtr1InvrtrRtLmtsRqst1Cntr : 8|4@1+ (1,0) [0|15] "" Vector__XXX
 SG_ MtGt1IvtRtLtsRqstAstSpdRtLt : 12|12@1+ (0.25,0) [0|1003.75] "%/s" Vector__XXX
 SG_ MtGt1IvtRtLtsRqstAstTqRtLt : 24|12@1+ (2,0) [0|8030] "%/s" Vector__XXX

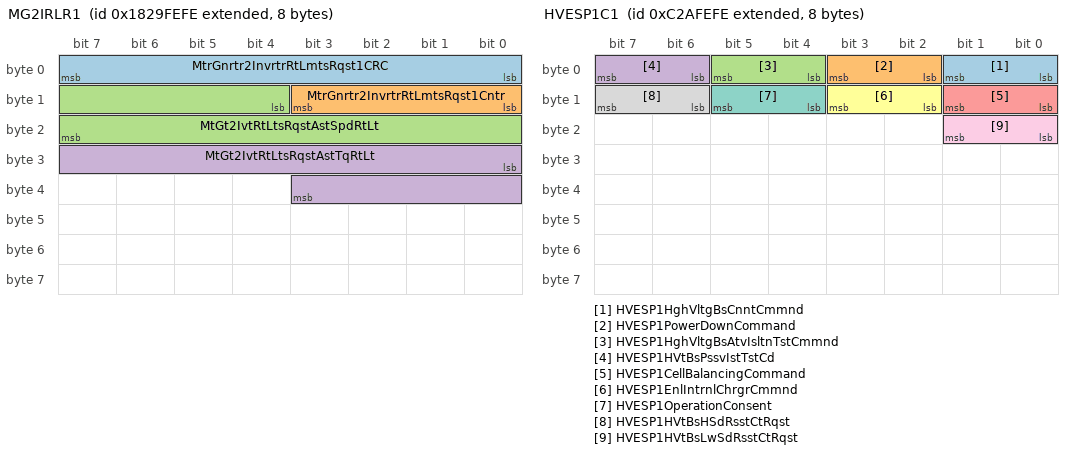
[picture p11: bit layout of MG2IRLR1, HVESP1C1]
BO_ 2552889086 MG2IRLR1: 8 Vector__XXX
 SG_ MtrGnrtr2InvrtrRtLmtsRqst1CRC : 0|8@1+ (1,0) [0|255] "count" Vector__XXX
 SG_ MtrGnrtr2InvrtrRtLmtsRqst1Cntr : 8|4@1+ (1,0) [0|15] "" Vector__XXX
 SG_ MtGt2IvtRtLtsRqstAstSpdRtLt : 12|12@1+ (0.25,0) [0|1003.75] "%/s" Vector__XXX
 SG_ MtGt2IvtRtLtsRqstAstTqRtLt : 24|12@1+ (2,0) [0|8030] "%/s" Vector__XXX

BO_ 2351628030 HVESP1C1: 8 Vector__XXX
 SG_ HVESP1HghVltgBsCnntCmmnd : 0|2@1+ (1,0) [0|3] "" Vector__XXX
 SG_ HVESP1PowerDownCommand : 2|2@1+ (1,0) [0|3] "" Vector__XXX
 SG_ HVESP1HghVltgBsAtvIsltnTstCmmnd : 4|2@1+ (1,0) [0|3] "" Vector__XXX
 SG_ HVESP1HVtBsPssvIstTstCd : 6|2@1+ (1,0) [0|3] "" Vector__XXX
 SG_ HVESP1CellBalancingCommand : 8|2@1+ (1,0) [0|3] "" Vector__XXX
 SG_ HVESP1EnlIntrnlChrgrCmmnd : 10|2@1+ (1,0) [0|3] "" Vector__XXX
 SG_ HVESP1OperationConsent : 12|2@1+ (1,0) [0|3] "" Vector__XXX
 SG_ HVESP1HVtBsHSdRsstCtRqst : 14|2@1+ (1,0) [0|3] "" Vector__XXX
 SG_ HVESP1HVtBsLwSdRsstCtRqst : 16|2@1+ (1,0) [0|3] "" Vector__XXX

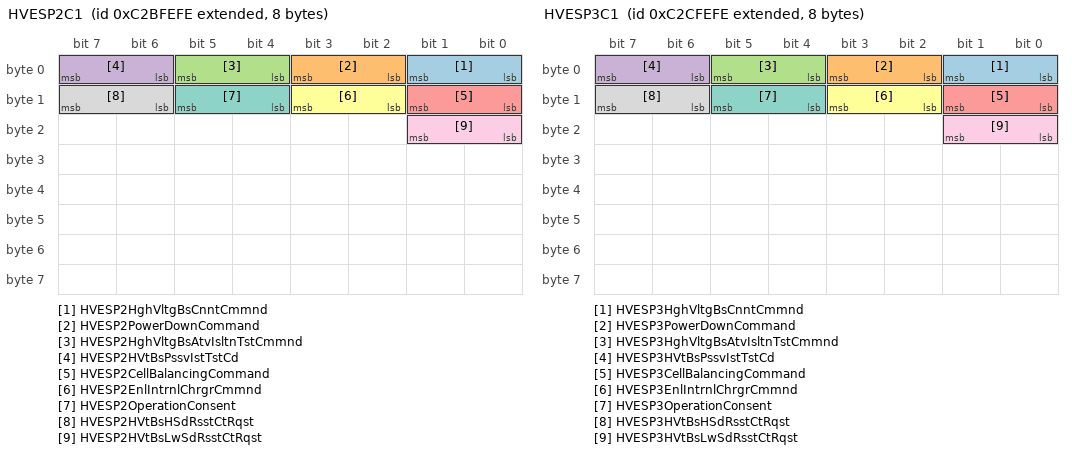
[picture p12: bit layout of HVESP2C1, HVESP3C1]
BO_ 2351693566 HVESP2C1: 8 Vector__XXX
 SG_ HVESP2HghVltgBsCnntCmmnd : 0|2@1+ (1,0) [0|3] "" Vector__XXX
 SG_ HVESP2PowerDownCommand : 2|2@1+ (1,0) [0|3] "" Vector__XXX
 SG_ HVESP2HghVltgBsAtvIsltnTstCmmnd : 4|2@1+ (1,0) [0|3] "" Vector__XXX
 SG_ HVESP2HVtBsPssvIstTstCd : 6|2@1+ (1,0) [0|3] "" Vector__XXX
 SG_ HVESP2CellBalancingCommand : 8|2@1+ (1,0) [0|3] "" Vector__XXX
 SG_ HVESP2EnlIntrnlChrgrCmmnd : 10|2@1+ (1,0) [0|3] "" Vector__XXX
 SG_ HVESP2OperationConsent : 12|2@1+ (1,0) [0|3] "" Vector__XXX
 SG_ HVESP2HVtBsHSdRsstCtRqst : 14|2@1+ (1,0) [0|3] "" Vector__XXX
 SG_ HVESP2HVtBsLwSdRsstCtRqst : 16|2@1+ (1,0) [0|3] "" Vector__XXX

BO_ 2351759102 HVESP3C1: 8 Vector__XXX
 SG_ HVESP3HghVltgBsCnntCmmnd : 0|2@1+ (1,0) [0|3] "" Vector__XXX
 SG_ HVESP3PowerDownCommand : 2|2@1+ (1,0) [0|3] "" Vector__XXX
 SG_ HVESP3HghVltgBsAtvIsltnTstCmmnd : 4|2@1+ (1,0) [0|3] "" Vector__XXX
 SG_ HVESP3HVtBsPssvIstTstCd : 6|2@1+ (1,0) [0|3] "" Vector__XXX
 SG_ HVESP3CellBalancingCommand : 8|2@1+ (1,0) [0|3] "" Vector__XXX
 SG_ HVESP3EnlIntrnlChrgrCmmnd : 10|2@1+ (1,0) [0|3] "" Vector__XXX
 SG_ HVESP3OperationConsent : 12|2@1+ (1,0) [0|3] "" Vector__XXX
 SG_ HVESP3HVtBsHSdRsstCtRqst : 14|2@1+ (1,0) [0|3] "" Vector__XXX
 SG_ HVESP3HVtBsLwSdRsstCtRqst : 16|2@1+ (1,0) [0|3] "" Vector__XXX

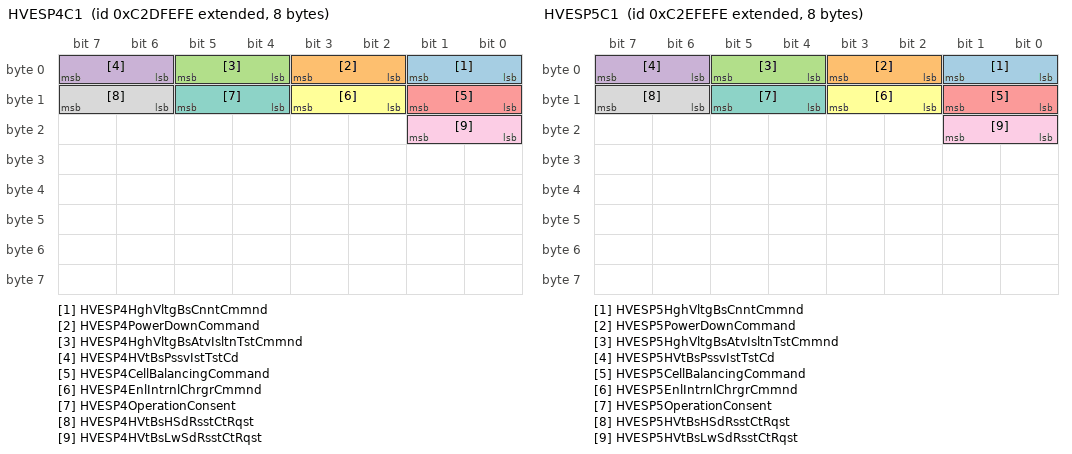
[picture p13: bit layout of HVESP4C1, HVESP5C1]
BO_ 2351824638 HVESP4C1: 8 Vector__XXX
 SG_ HVESP4HghVltgBsCnntCmmnd : 0|2@1+ (1,0) [0|3] "" Vector__XXX
 SG_ HVESP4PowerDownCommand : 2|2@1+ (1,0) [0|3] "" Vector__XXX
 SG_ HVESP4HghVltgBsAtvIsltnTstCmmnd : 4|2@1+ (1,0) [0|3] "" Vector__XXX
 SG_ HVESP4HVtBsPssvIstTstCd : 6|2@1+ (1,0) [0|3] "" Vector__XXX
 SG_ HVESP4CellBalancingCommand : 8|2@1+ (1,0) [0|3] "" Vector__XXX
 SG_ HVESP4EnlIntrnlChrgrCmmnd : 10|2@1+ (1,0) [0|3] "" Vector__XXX
 SG_ HVESP4OperationConsent : 12|2@1+ (1,0) [0|3] "" Vector__XXX
 SG_ HVESP4HVtBsHSdRsstCtRqst : 14|2@1+ (1,0) [0|3] "" Vector__XXX
 SG_ HVESP4HVtBsLwSdRsstCtRqst : 16|2@1+ (1,0) [0|3] "" Vector__XXX

BO_ 2351890174 HVESP5C1: 8 Vector__XXX
 SG_ HVESP5HghVltgBsCnntCmmnd : 0|2@1+ (1,0) [0|3] "" Vector__XXX
 SG_ HVESP5PowerDownCommand : 2|2@1+ (1,0) [0|3] "" Vector__XXX
 SG_ HVESP5HghVltgBsAtvIsltnTstCmmnd : 4|2@1+ (1,0) [0|3] "" Vector__XXX
 SG_ HVESP5HVtBsPssvIstTstCd : 6|2@1+ (1,0) [0|3] "" Vector__XXX
 SG_ HVESP5CellBalancingCommand : 8|2@1+ (1,0) [0|3] "" Vector__XXX
 SG_ HVESP5EnlIntrnlChrgrCmmnd : 10|2@1+ (1,0) [0|3] "" Vector__XXX
 SG_ HVESP5OperationConsent : 12|2@1+ (1,0) [0|3] "" Vector__XXX
 SG_ HVESP5HVtBsHSdRsstCtRqst : 14|2@1+ (1,0) [0|3] "" Vector__XXX
 SG_ HVESP5HVtBsLwSdRsstCtRqst : 16|2@1+ (1,0) [0|3] "" Vector__XXX

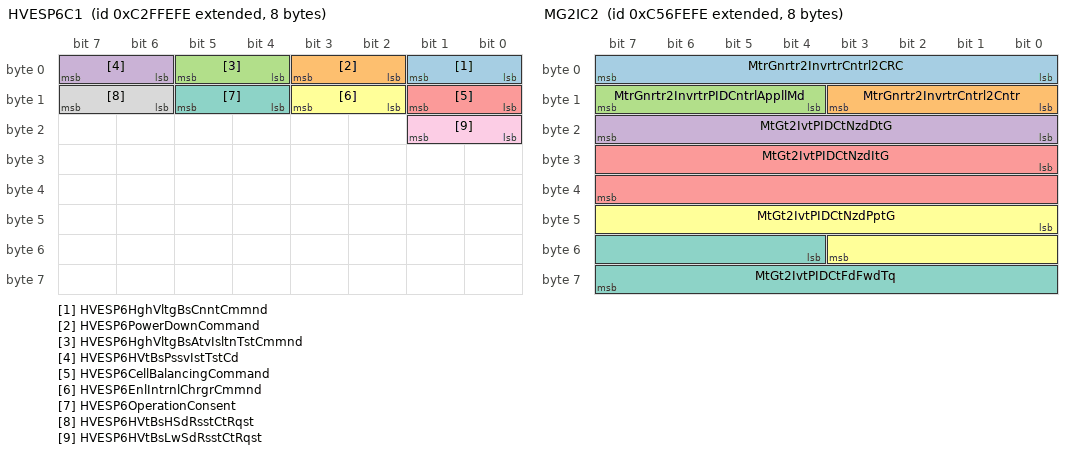
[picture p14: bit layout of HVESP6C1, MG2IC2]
BO_ 2351955710 HVESP6C1: 8 Vector__XXX
 SG_ HVESP6HghVltgBsCnntCmmnd : 0|2@1+ (1,0) [0|3] "" Vector__XXX
 SG_ HVESP6PowerDownCommand : 2|2@1+ (1,0) [0|3] "" Vector__XXX
 SG_ HVESP6HghVltgBsAtvIsltnTstCmmnd : 4|2@1+ (1,0) [0|3] "" Vector__XXX
 SG_ HVESP6HVtBsPssvIstTstCd : 6|2@1+ (1,0) [0|3] "" Vector__XXX
 SG_ HVESP6CellBalancingCommand : 8|2@1+ (1,0) [0|3] "" Vector__XXX
 SG_ HVESP6EnlIntrnlChrgrCmmnd : 10|2@1+ (1,0) [0|3] "" Vector__XXX
 SG_ HVESP6OperationConsent : 12|2@1+ (1,0) [0|3] "" Vector__XXX
 SG_ HVESP6HVtBsHSdRsstCtRqst : 14|2@1+ (1,0) [0|3] "" Vector__XXX
 SG_ HVESP6HVtBsLwSdRsstCtRqst : 16|2@1+ (1,0) [0|3] "" Vector__XXX

BO_ 2555641598 EVSE1C1: 8 Vector__XXX
 SG_ EVSE1ConnectorLockCommand : 0|4@1+ (1,0) [0|15] "" Vector__XXX

BO_ 2555707134 WINCH3: 8 Vector__XXX
 SG_ WinchPositionReset : 0|2@1+ (1,0) [0|3] "" Vector__XXX

BO_ 2354446078 ASC8: 8 Vector__XXX
 SG_ LiftAxle3PositionCommand : 0|2@1+ (1,0) [0|3] "" Vector__XXX

BO_ 2354511614 MG2IC2: 8 Vector__XXX
 SG_ MtrGnrtr2InvrtrCntrl2CRC : 0|8@1+ (1,0) [0|255] "count" Vector__XXX
 SG_ MtrGnrtr2InvrtrCntrl2Cntr : 8|4@1+ (1,0) [0|15] "" Vector__XXX
 SG_ MtrGnrtr2InvrtrPIDCntrlAppllMd : 12|4@1+ (1,0) [0|15] "" Vector__XXX
 SG_ MtGt2IvtPIDCtNzdDtG : 16|8@1+ (11689,0) [0|7.8125] "%/(%/s)" Vector__XXX
 SG_ MtGt2IvtPIDCtNzdItG : 24|16@1+ (23377,0) [0|1003.984375] "%/(%/s)" Vector__XXX
 SG_ MtGt2IvtPIDCtNzdPptG : 40|12@1+ (42370,0) [0|250.9375] "%/%" Vector__XXX
 SG_ MtGt2IvtPIDCtFdFwdTq : 52|12@1+ (42370,-125) [-125|125.9375] "%" Vector__XXX

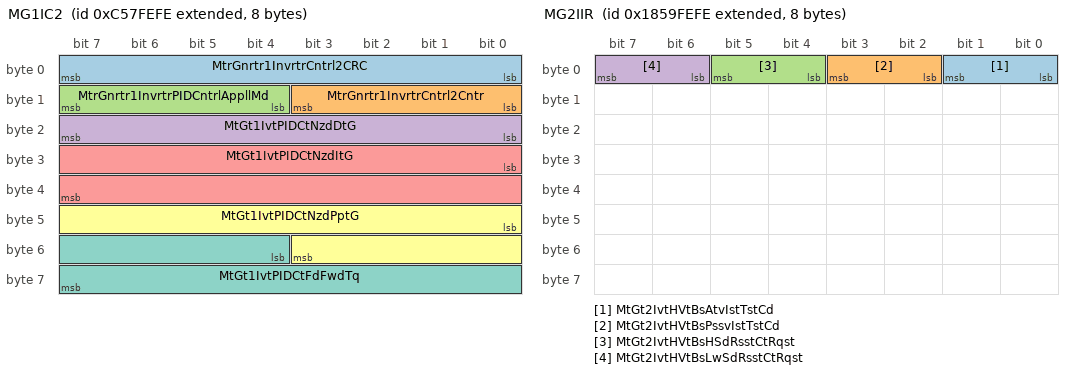
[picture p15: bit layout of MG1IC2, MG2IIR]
BO_ 2354577150 MG1IC2: 8 Vector__XXX
 SG_ MtrGnrtr1InvrtrCntrl2CRC : 0|8@1+ (1,0) [0|255] "count" Vector__XXX
 SG_ MtrGnrtr1InvrtrCntrl2Cntr : 8|4@1+ (1,0) [0|15] "" Vector__XXX
 SG_ MtrGnrtr1InvrtrPIDCntrlAppllMd : 12|4@1+ (1,0) [0|15] "" Vector__XXX
 SG_ MtGt1IvtPIDCtNzdDtG : 16|8@1+ (11689,0) [0|7.8125] "%/(%/s)" Vector__XXX
 SG_ MtGt1IvtPIDCtNzdItG : 24|16@1+ (23377,0) [0|1003.984375] "%/(%/s)" Vector__XXX
 SG_ MtGt1IvtPIDCtNzdPptG : 40|12@1+ (42370,0) [0|250.9375] "%/%" Vector__XXX
 SG_ MtGt1IvtPIDCtFdFwdTq : 52|12@1+ (42370,-125) [-125|125.9375] "%" Vector__XXX

BO_ 2488860414 HCI2: 8 Vector__XXX
 SG_ HoistCommand : 0|16@1+ (0.005,-150) [-150|171.275] "%" Vector__XXX
 SG_ HoistDetentStatus : 16|2@1+ (1,0) [0|3] "" Vector__XXX

BO_ 2556034814 MG2IIR: 8 Vector__XXX
 SG_ MtGt2IvtHVtBsAtvIstTstCd : 0|2@1+ (1,0) [0|3] "" Vector__XXX
 SG_ MtGt2IvtHVtBsPssvIstTstCd : 2|2@1+ (1,0) [0|3] "" Vector__XXX
 SG_ MtGt2IvtHVtBsHSdRsstCtRqst : 4|2@1+ (1,0) [0|3] "" Vector__XXX
 SG_ MtGt2IvtHVtBsLwSdRsstCtRqst : 6|2@1+ (1,0) [0|3] "" Vector__XXX

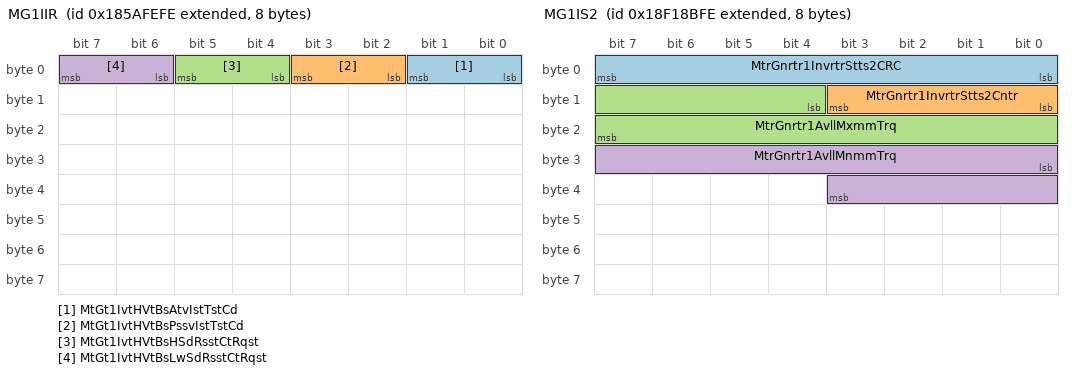
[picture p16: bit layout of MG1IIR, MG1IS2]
BO_ 2556100350 MG1IIR: 8 Vector__XXX
 SG_ MtGt1IvtHVtBsAtvIstTstCd : 0|2@1+ (1,0) [0|3] "" Vector__XXX
 SG_ MtGt1IvtHVtBsPssvIstTstCd : 2|2@1+ (1,0) [0|3] "" Vector__XXX
 SG_ MtGt1IvtHVtBsHSdRsstCtRqst : 4|2@1+ (1,0) [0|3] "" Vector__XXX
 SG_ MtGt1IvtHVtBsLwSdRsstCtRqst : 6|2@1+ (1,0) [0|3] "" Vector__XXX

BO_ 2565966846 MG1IS2: 8 Vector__XXX
 SG_ MtrGnrtr1InvrtrStts2CRC : 0|8@1+ (1,0) [0|255] "count" Vector__XXX
 SG_ MtrGnrtr1InvrtrStts2Cntr : 8|4@1+ (1,0) [0|15] "" Vector__XXX
 SG_ MtrGnrtr1AvllMxmmTrq : 12|12@1+ (42370,-125) [-125|125.9375] "%" Vector__XXX
 SG_ MtrGnrtr1AvllMnmmTrq : 24|12@1+ (42370,-125) [-125|125.9375] "%" Vector__XXX

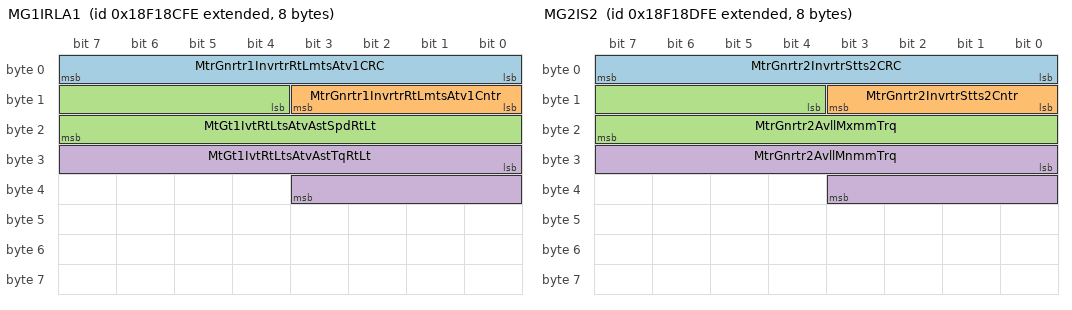
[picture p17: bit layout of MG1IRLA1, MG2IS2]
BO_ 2565967102 MG1IRLA1: 8 Vector__XXX
 SG_ MtrGnrtr1InvrtrRtLmtsAtv1CRC : 0|8@1+ (1,0) [0|255] "count" Vector__XXX
 SG_ MtrGnrtr1InvrtrRtLmtsAtv1Cntr : 8|4@1+ (1,0) [0|15] "" Vector__XXX
 SG_ MtGt1IvtRtLtsAtvAstSpdRtLt : 12|12@1+ (0.25,0) [0|1003.75] "%/s" Vector__XXX
 SG_ MtGt1IvtRtLtsAtvAstTqRtLt : 24|12@1+ (2,0) [0|8030] "%/s" Vector__XXX

BO_ 2565967358 MG2IS2: 8 Vector__XXX
 SG_ MtrGnrtr2InvrtrStts2CRC : 0|8@1+ (1,0) [0|255] "count" Vector__XXX
 SG_ MtrGnrtr2InvrtrStts2Cntr : 8|4@1+ (1,0) [0|15] "" Vector__XXX
 SG_ MtrGnrtr2AvllMxmmTrq : 12|12@1+ (42370,-125) [-125|125.9375] "%" Vector__XXX
 SG_ MtrGnrtr2AvllMnmmTrq : 24|12@1+ (42370,-125) [-125|125.9375] "%" Vector__XXX

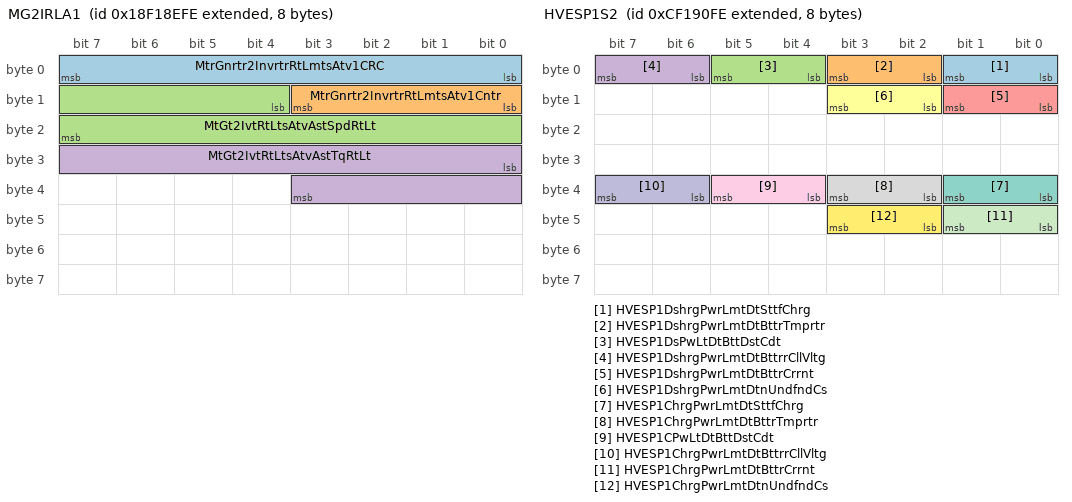
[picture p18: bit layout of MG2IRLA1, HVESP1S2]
BO_ 2565967614 MG2IRLA1: 8 Vector__XXX
 SG_ MtrGnrtr2InvrtrRtLmtsAtv1CRC : 0|8@1+ (1,0) [0|255] "count" Vector__XXX
 SG_ MtrGnrtr2InvrtrRtLmtsAtv1Cntr : 8|4@1+ (1,0) [0|15] "" Vector__XXX
 SG_ MtGt2IvtRtLtsAtvAstSpdRtLt : 12|12@1+ (0.25,0) [0|1003.75] "%/s" Vector__XXX
 SG_ MtGt2IvtRtLtsAtvAstTqRtLt : 24|12@1+ (2,0) [0|8030] "%/s" Vector__XXX

BO_ 2297532414 IPGA: 8 Vector__XXX
 SG_ ImpostorPGEventDetectionCounter : 0|8@1+ (1,0) [0|250] "count" Vector__XXX
 SG_ ImpostorPGSourceAddress : 8|8@1+ (1,0) [0|255] "SA" Vector__XXX
 SG_ ImpostorPGDestinationAddress : 16|8@1+ (1,0) [0|255] "SA" Vector__XXX
 SG_ ImpostorPGN : 24|24@1+ (1,0) [0|16777215] "binary" Vector__XXX
 SG_ TimeSinceLastImposterPGDetected : 48|8@1+ (1,0) [0|250] "min" Vector__XXX

BO_ 2364641534 HVESP1S2: 8 Vector__XXX
 SG_ HVESP1DshrgPwrLmtDtSttfChrg : 0|2@1+ (1,0) [0|3] "" Vector__XXX
 SG_ HVESP1DshrgPwrLmtDtBttrTmprtr : 2|2@1+ (1,0) [0|3] "" Vector__XXX
 SG_ HVESP1DsPwLtDtBttDstCdt : 4|2@1+ (1,0) [0|3] "" Vector__XXX
 SG_ HVESP1DshrgPwrLmtDtBttrrCllVltg : 6|2@1+ (1,0) [0|3] "" Vector__XXX
 SG_ HVESP1DshrgPwrLmtDtBttrCrrnt : 8|2@1+ (1,0) [0|3] "" Vector__XXX
 SG_ HVESP1DshrgPwrLmtDtnUndfndCs : 10|2@1+ (1,0) [0|3] "" Vector__XXX
 SG_ HVESP1ChrgPwrLmtDtSttfChrg : 32|2@1+ (1,0) [0|3] "" Vector__XXX
 SG_ HVESP1ChrgPwrLmtDtBttrTmprtr : 34|2@1+ (1,0) [0|3] "" Vector__XXX
 SG_ HVESP1CPwLtDtBttDstCdt : 36|2@1+ (1,0) [0|3] "" Vector__XXX
 SG_ HVESP1ChrgPwrLmtDtBttrrCllVltg : 38|2@1+ (1,0) [0|3] "" Vector__XXX
 SG_ HVESP1ChrgPwrLmtDtBttrCrrnt : 40|2@1+ (1,0) [0|3] "" Vector__XXX
 SG_ HVESP1ChrgPwrLmtDtnUndfndCs : 42|2@1+ (1,0) [0|3] "" Vector__XXX

BO_ 2364641790 HVESP1D1: 8 Vector__XXX
 SG_ HVESP1AvailableDischargePower : 0|16@1+ (0.05,0) [0|3212.75] "kW" Vector__XXX
 SG_ HVESP1AvailableChargePower : 16|16@1+ (0.05,0) [0|3212.75] "kW" Vector__XXX
 SG_ HVESP1VoltageLevel : 32|16@1+ (0.05,0) [0|3212.75] "V" Vector__XXX
 SG_ HVESP1Current : 48|16@1+ (0.05,-1600) [-1600|1612.75] "A" Vector__XXX

BO_ 2364642046 HVESP1D2: 8 Vector__XXX
 SG_ HVESP1FastUpdateStateofCharge : 0|16@1+ (0.0015625,0) [0|100.3984375] "%" Vector__XXX
 SG_ HVESP1HighestCellVoltage : 16|16@1+ (0.001,0) [0|64.255] "V" Vector__XXX
 SG_ HVESP1LowestCellVoltage : 32|16@1+ (0.001,0) [0|64.255] "V" Vector__XXX
 SG_ HVESP1CllVltgDffrntlStts : 48|4@1+ (1,0) [0|15] "" Vector__XXX

BO_ 2364642302 HVESP1D3: 8 Vector__XXX
 SG_ HVESP1HighestCellTemperature : 0|16@1+ (0.03125,-273) [-273|1734.96875] "degC" Vector__XXX
 SG_ HVESP1LowestCellTemperature : 16|16@1+ (0.03125,-273) [-273|1734.96875] "degC" Vector__XXX
 SG_ HVESP1AverageCellTemperature : 32|16@1+ (0.03125,-273) [-273|1734.96875] "degC" Vector__XXX
 SG_ HVESP1CllTmprtrDffrntlStts : 48|2@1+ (1,0) [0|3] "" Vector__XXX

BO_ 2364642558 HVESP1D4: 8 Vector__XXX
 SG_ HVESP1DischargeCapacity : 0|16@1+ (0.01,0) [0|642.55] "Ah" Vector__XXX
 SG_ HVESP1ChargeCapacity : 16|16@1+ (0.01,0) [0|642.55] "Ah" Vector__XXX
 SG_ HVESP1CellBalancingCount : 32|16@1+ (1,0) [0|64255] "count" Vector__XXX

BO_ 2364642814 HVESP1D5: 8 Vector__XXX
 SG_ HVESP1DischargeCurrentLimit : 0|16@1+ (0.05,-1600) [-1600|1612.75] "A" Vector__XXX
 SG_ HVESP1ChargeCurrentLimit : 16|16@1+ (0.05,-1600) [-1600|1612.75] "A" Vector__XXX
 SG_ HVESP1LowestCellStateofCharge : 32|16@1+ (0.0015625,0) [0|100.3984375] "%" Vector__XXX
 SG_ HVESP1HighestCellStateofCharge : 48|16@1+ (0.0015625,0) [0|100.3984375] "%" Vector__XXX

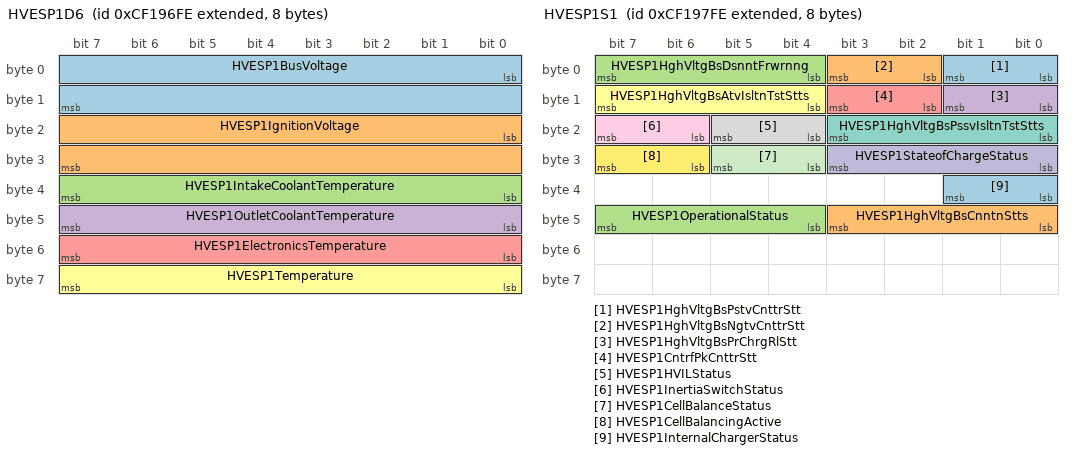
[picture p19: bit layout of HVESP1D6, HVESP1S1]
BO_ 2364643070 HVESP1D6: 8 Vector__XXX
 SG_ HVESP1BusVoltage : 0|16@1+ (0.05,0) [0|3212.75] "V" Vector__XXX
 SG_ HVESP1IgnitionVoltage : 16|16@1+ (0.01,0) [0|642.55] "V" Vector__XXX
 SG_ HVESP1IntakeCoolantTemperature : 32|8@1+ (1,-40) [-40|210] "degC" Vector__XXX
 SG_ HVESP1OutletCoolantTemperature : 40|8@1+ (1,-40) [-40|210] "degC" Vector__XXX
 SG_ HVESP1ElectronicsTemperature : 48|8@1+ (1,-40) [-40|210] "degC" Vector__XXX
 SG_ HVESP1Temperature : 56|8@1+ (1,-40) [-40|210] "degC" Vector__XXX

BO_ 2364643326 HVESP1S1: 8 Vector__XXX
 SG_ HVESP1HghVltgBsPstvCnttrStt : 0|2@1+ (1,0) [0|3] "" Vector__XXX
 SG_ HVESP1HghVltgBsNgtvCnttrStt : 2|2@1+ (1,0) [0|3] "" Vector__XXX
 SG_ HVESP1HghVltgBsDsnntFrwrnng : 4|4@1+ (1,0) [0|15] "" Vector__XXX
 SG_ HVESP1HghVltgBsPrChrgRlStt : 8|2@1+ (1,0) [0|3] "" Vector__XXX
 SG_ HVESP1CntrfPkCnttrStt : 10|2@1+ (1,0) [0|3] "" Vector__XXX
 SG_ HVESP1HghVltgBsAtvIsltnTstStts : 12|4@1+ (1,0) [0|15] "" Vector__XXX
 SG_ HVESP1HghVltgBsPssvIsltnTstStts : 16|4@1+ (1,0) [0|15] "" Vector__XXX
 SG_ HVESP1HVILStatus : 20|2@1+ (1,0) [0|3] "" Vector__XXX
 SG_ HVESP1InertiaSwitchStatus : 22|2@1+ (1,0) [0|3] "" Vector__XXX
 SG_ HVESP1StateofChargeStatus : 24|4@1+ (1,0) [0|15] "" Vector__XXX
 SG_ HVESP1CellBalanceStatus : 28|2@1+ (1,0) [0|3] "" Vector__XXX
 SG_ HVESP1CellBalancingActive : 30|2@1+ (1,0) [0|3] "" Vector__XXX
 SG_ HVESP1InternalChargerStatus : 32|2@1+ (1,0) [0|3] "" Vector__XXX
 SG_ HVESP1HghVltgBsCnntnStts : 40|4@1+ (1,0) [0|15] "" Vector__XXX
 SG_ HVESP1OperationalStatus : 44|4@1+ (1,0) [0|15] "" Vector__XXX

BO_ 2364643582 HVESP1D7: 8 Vector__XXX
 SG_ HVESP1DischargeEnergyCapacity : 0|24@1+ (0.001,0) [0|16449.535] "kWh" Vector__XXX
 SG_ HVESP1ChargeEnergyCapacity : 24|24@1+ (0.001,0) [0|16449.535] "kWh" Vector__XXX
 SG_ HVESP1MaximumChargeVoltageLimit : 48|16@1+ (0.05,0) [0|3212.75] "V" Vector__XXX

CM_ BO_ 2364632574 "Engine Cylinder 1 Combustion Metrics";
CM_ SG_ 2364632574 ECd1IsttsPCstPssT "Engine Cylinder 1 Instantaneous Peak Combustion Pressure Timing: The timing in crank angle degrees of the observed peak pressure during the current combustion cycle.  When the combustion happens after the TDC (Top Dead Center) of this cylinder, the t...";
CM_ SG_ 2364632574 ECd1IsttsIdtdMEtvPss "Engine Cylinder 1 Instantaneous Indicated Mean Effective Pressure: The indicated mean effective pressure (IMEP) is the work delivered to the piston over the entire cycle, per unit displaced volume.  This SP reports for the current engine cycle.  See ...";
CM_ SG_ 2364632574 ECd1IdtdMEtvPssCtV "Engine Cylinder 1 Indicated Mean Effective Pressure Coefficient of Variance : The indicated mean effective pressure coefficient of variance is the variability seen in IMEP over the number of engine cycles in SPN6394 represented as a percentage.";
CM_ SG_ 2364632574 EngineCylinder1MisfireRate "Engine Cylinder 1 Misfire Rate: The misfire rate of engine cylinder 1 over the number of engine cycles in SPN6394 represented as a percentage.";
CM_ SG_ 2364632574 EngineCylinder1Temperature "Engine Cylinder 1 Temperature: Gas temperature in cylinder measured at the cylinder head of cylinder 1.";
CM_ BO_ 2364632830 "Engine Cylinder 2 Combustion Metrics";
CM_ SG_ 2364632830 ECd2IsttsPCstPssT "Engine Cylinder 2 Instantaneous Peak Combustion Pressure Timing: The timing in crank angle degrees of the observed peak pressure during the current combustion cycle.  When the combustion happens after the TDC (Top Dead Center) of this cylinder, the t...";
CM_ SG_ 2364632830 ECd2IsttsIdtdMEtvPss "Engine Cylinder 2 Instantaneous Indicated Mean Effective Pressure: The indicated mean effective pressure (IMEP) is the work delivered to the piston over the entire cycle, per unit displaced volume.  This SP reports for the current engine cycle.  See ...";
CM_ SG_ 2364632830 ECd2IdtdMEtvPssCtV "Engine Cylinder 2 Indicated Mean Effective Pressure Coefficient of Variance : The indicated mean effective pressure coefficient of variance is the variability seen in IMEP over the number of engine cycles in SPN6394 represented as a percentage.";
CM_ SG_ 2364632830 EngineCylinder2MisfireRate "Engine Cylinder 2 Misfire Rate: The misfire rate of engine Cylinder 2 over the number of engine cycles in SPN6394 represented as a percentage.";
CM_ SG_ 2364632830 EngineCylinder2Temperature "Engine Cylinder 2 Temperature: Gas temperature in cylinder measured at the cylinder head of cylinder 2.";
CM_ BO_ 2364633086 "Engine Cylinder 3 Combustion Metrics";
CM_ SG_ 2364633086 ECd3IsttsPCstPssT "Engine Cylinder 3 Instantaneous Peak Combustion Pressure Timing: The timing in crank angle degrees of the observed peak pressure during the current combustion cycle.  When the combustion happens after the TDC (Top Dead Center) of this cylinder, the t...";
CM_ SG_ 2364633086 ECd3IsttsIdtdMEtvPss "Engine Cylinder 3 Instantaneous Indicated Mean Effective Pressure: The indicated mean effective pressure (IMEP) is the work delivered to the piston over the entire cycle, per unit displaced volume.  This SP reports for the current engine cycle.  See ...";
CM_ SG_ 2364633086 ECd3IdtdMEtvPssCtV "Engine Cylinder 3 Indicated Mean Effective Pressure Coefficient of Variance : The indicated mean effective pressure coefficient of variance is the variability seen in IMEP over the number of engine cycles in SPN6394 represented as a percentage.";
CM_ SG_ 2364633086 EngineCylinder3MisfireRate "Engine Cylinder 3 Misfire Rate: The misfire rate of engine Cylinder 3 over the number of engine cycles in SPN6394 represented as a percentage.";
CM_ SG_ 2364633086 EngineCylinder3Temperature "Engine Cylinder 3 Temperature: Gas temperature in cylinder measured at the cylinder head of cylinder 3.";
CM_ BO_ 2364633342 "Engine Cylinder 4 Combustion Metrics";
CM_ SG_ 2364633342 ECd4IsttsPCstPssT "Engine Cylinder 4 Instantaneous Peak Combustion Pressure Timing: The timing in crank angle degrees of the observed peak pressure during the current combustion cycle.  When the combustion happens after the TDC (Top Dead Center) of this cylinder, the t...";
CM_ SG_ 2364633342 ECd4IsttsIdtdMEtvPss "Engine Cylinder 4 Instantaneous Indicated Mean Effective Pressure: The indicated mean effective pressure (IMEP) is the work delivered to the piston over the entire cycle, per unit displaced volume.  This SP reports for the current engine cycle.  See ...";
CM_ SG_ 2364633342 ECd4IdtdMEtvPssCtV "Engine Cylinder 4 Indicated Mean Effective Pressure Coefficient of Variance : The indicated mean effective pressure coefficient of variance is the variability seen in IMEP over the number of engine cycles in SPN6394 represented as a percentage.";
CM_ SG_ 2364633342 EngineCylinder4MisfireRate "Engine Cylinder 4 Misfire Rate: The misfire rate of engine Cylinder 4 over the number of engine cycles in SPN6394 represented as a percentage.";
CM_ SG_ 2364633342 EngineCylinder4Temperature "Engine Cylinder 4 Temperature: Gas temperature in cylinder measured at the cylinder head of cylinder 4.";
CM_ BO_ 2364633598 "Engine Cylinder 5 Combustion Metrics";
CM_ SG_ 2364633598 ECd5IsttsPCstPssT "Engine Cylinder 5 Instantaneous Peak Combustion Pressure Timing: The timing in crank angle degrees of the observed peak pressure during the current combustion cycle.  When the combustion happens after the TDC (Top Dead Center) of this cylinder, the t...";
CM_ SG_ 2364633598 ECd5IsttsIdtdMEtvPss "Engine Cylinder 5 Instantaneous Indicated Mean Effective Pressure: The indicated mean effective pressure (IMEP) is the work delivered to the piston over the entire cycle, per unit displaced volume.  This SP reports for the current engine cycle.  See ...";
CM_ SG_ 2364633598 ECd5IdtdMEtvPssCtV "Engine Cylinder 5 Indicated Mean Effective Pressure Coefficient of Variance : The indicated mean effective pressure coefficient of variance is the variability seen in IMEP over the number of engine cycles in SPN6394 represented as a percentage.";
CM_ SG_ 2364633598 EngineCylinder5MisfireRate "Engine Cylinder 5 Misfire Rate: The misfire rate of engine Cylinder 5 over the number of engine cycles in SPN6394 represented as a percentage.";
CM_ SG_ 2364633598 EngineCylinder5Temperature "Engine Cylinder 5 Temperature: Gas temperature in cylinder measured at the cylinder head of cylinder 5.";
CM_ BO_ 2364633854 "Engine Cylinder 6 Combustion Metrics";
CM_ SG_ 2364633854 ECd6IsttsPCstPssT "Engine Cylinder 6 Instantaneous Peak Combustion Pressure Timing: The timing in crank angle degrees of the observed peak pressure during the current combustion cycle.  When the combustion happens after the TDC (Top Dead Center) of this cylinder, the t...";
CM_ SG_ 2364633854 ECd6IsttsIdtdMEtvPss "Engine Cylinder 6 Instantaneous Indicated Mean Effective Pressure: The indicated mean effective pressure (IMEP) is the work delivered to the piston over the entire cycle, per unit displaced volume.  This SP reports for the current engine cycle.  See ...";
CM_ SG_ 2364633854 ECd6IdtdMEtvPssCtV "Engine Cylinder 6 Indicated Mean Effective Pressure Coefficient of Variance : The indicated mean effective pressure coefficient of variance is the variability seen in IMEP over the number of engine cycles in SPN6394 represented as a percentage.";
CM_ SG_ 2364633854 EngineCylinder6MisfireRate "Engine Cylinder 6 Misfire Rate: The misfire rate of engine Cylinder 6 over the number of engine cycles in SPN6394 represented as a percentage.";
CM_ SG_ 2364633854 EngineCylinder6Temperature "Engine Cylinder 6 Temperature: Gas temperature in cylinder measured at the cylinder head of cylinder 6.";
CM_ BO_ 2364634110 "Engine Cylinder 7 Combustion Metrics";
CM_ SG_ 2364634110 ECd7IsttsPCstPssT "Engine Cylinder 7 Instantaneous Peak Combustion Pressure Timing: The timing in crank angle degrees of the observed peak pressure during the current combustion cycle.  When the combustion happens after the TDC (Top Dead Center) of this cylinder, the t...";
CM_ SG_ 2364634110 ECd7IsttsIdtdMEtvPss "Engine Cylinder 7 Instantaneous Indicated Mean Effective Pressure: The indicated mean effective pressure (IMEP) is the work delivered to the piston over the entire cycle, per unit displaced volume.  This SP reports for the current engine cycle.  See ...";
CM_ SG_ 2364634110 ECd7IdtdMEtvPssCtV "Engine Cylinder 7 Indicated Mean Effective Pressure Coefficient of Variance : The indicated mean effective pressure coefficient of variance is the variability seen in IMEP over the number of engine cycles in SPN6394 represented as a percentage.";
CM_ SG_ 2364634110 EngineCylinder7MisfireRate "Engine Cylinder 7 Misfire Rate: The misfire rate of engine Cylinder 7 over the number of engine cycles in SPN6394 represented as a percentage.";
CM_ SG_ 2364634110 EngineCylinder7Temperature "Engine Cylinder 7 Temperature: Gas temperature in cylinder measured at the cylinder head of cylinder 7.";
CM_ BO_ 2364634366 "Engine Cylinder 8 Combustion Metrics";
CM_ SG_ 2364634366 ECd8IsttsPCstPssT "Engine Cylinder 8 Instantaneous Peak Combustion Pressure Timing: The timing in crank angle degrees of the observed peak pressure during the current combustion cycle.  When the combustion happens after the TDC (Top Dead Center) of this cylinder, the t...";
CM_ SG_ 2364634366 ECd8IsttsIdtdMEtvPss "Engine Cylinder 8 Instantaneous Indicated Mean Effective Pressure: The indicated mean effective pressure (IMEP) is the work delivered to the piston over the entire cycle, per unit displaced volume.  This SP reports for the current engine cycle.  See ...";
CM_ SG_ 2364634366 ECd8IdtdMEtvPssCtV "Engine Cylinder 8 Indicated Mean Effective Pressure Coefficient of Variance : The indicated mean effective pressure coefficient of variance is the variability seen in IMEP over the number of engine cycles in SPN6394 represented as a percentage.";
CM_ SG_ 2364634366 EngineCylinder8MisfireRate "Engine Cylinder 8 Misfire Rate: The misfire rate of engine Cylinder 8 over the number of engine cycles in SPN6394 represented as a percentage.";
CM_ SG_ 2364634366 EngineCylinder8Temperature "Engine Cylinder 8 Temperature: Gas temperature in cylinder measured at the cylinder head of cylinder 8.";
CM_ BO_ 2364634622 "Engine Cylinder 9 Combustion Metrics";
CM_ SG_ 2364634622 ECd9IsttsPCstPssT "Engine Cylinder 9 Instantaneous Peak Combustion Pressure Timing: The timing in crank angle degrees of the observed peak pressure during the current combustion cycle.  When the combustion happens after the TDC (Top Dead Center) of this cylinder, the t...";
CM_ SG_ 2364634622 ECd9IsttsIdtdMEtvPss "Engine Cylinder 9 Instantaneous Indicated Mean Effective Pressure: The indicated mean effective pressure (IMEP) is the work delivered to the piston over the entire cycle, per unit displaced volume.  This SP reports for the current engine cycle.  See ...";
CM_ SG_ 2364634622 ECd9IdtdMEtvPssCtV "Engine Cylinder 9 Indicated Mean Effective Pressure Coefficient of Variance : The indicated mean effective pressure coefficient of variance is the variability seen in IMEP over the number of engine cycles in SPN6394 represented as a percentage.";
CM_ SG_ 2364634622 EngineCylinder9MisfireRate "Engine Cylinder 9 Misfire Rate: The misfire rate of engine Cylinder 9 over the number of engine cycles in SPN6394 represented as a percentage.";
CM_ SG_ 2364634622 EngineCylinder9Temperature "Engine Cylinder 9 Temperature: Gas temperature in cylinder measured at the cylinder head of cylinder 9.";
CM_ BO_ 2364634878 "Engine Cylinder 10 Combustion Metrics";
CM_ SG_ 2364634878 ECd10IsttsPCstPssT "Engine Cylinder 10 Instantaneous Peak Combustion Pressure Timing: The timing in crank angle degrees of the observed peak pressure during the current combustion cycle.  When the combustion happens after the TDC (Top Dead Center) of this cylinder, the ...";
CM_ SG_ 2364634878 ECd10IsttsIdtdMEtvPss "Engine Cylinder 10 Instantaneous Indicated Mean Effective Pressure: The indicated mean effective pressure (IMEP) is the work delivered to the piston over the entire cycle, per unit displaced volume.  This SP reports for the current engine cycle.  See...";
CM_ SG_ 2364634878 ECd10IdtdMEtvPssCtV "Engine Cylinder 10 Indicated Mean Effective Pressure Coefficient of Variance : The indicated mean effective pressure coefficient of variance is the variability seen in IMEP over the number of engine cycles in SPN6394 represented as a percentage.";
CM_ SG_ 2364634878 EngineCylinder10MisfireRate "Engine Cylinder 10 Misfire Rate: The misfire rate of engine Cylinder 10 over the number of engine cycles in SPN6394 represented as a percentage.";
CM_ SG_ 2364634878 EngineCylinder10Temperature "Engine Cylinder 10 Temperature: Gas temperature in cylinder measured at the cylinder head of cylinder 10.";
CM_ BO_ 2364635134 "Engine Cylinder 11 Combustion Metrics";
CM_ SG_ 2364635134 ECd11IsttsPCstPssT "Engine Cylinder 11 Instantaneous Peak Combustion Pressure Timing: The timing in crank angle degrees of the observed peak pressure during the current combustion cycle.  When the combustion happens after the TDC (Top Dead Center) of this cylinder, the ...";
CM_ SG_ 2364635134 ECd11IsttsIdtdMEtvPss "Engine Cylinder 11 Instantaneous Indicated Mean Effective Pressure: The indicated mean effective pressure (IMEP) is the work delivered to the piston over the entire cycle, per unit displaced volume.  This SP reports for the current engine cycle.  See...";
CM_ SG_ 2364635134 ECd11IdtdMEtvPssCtV "Engine Cylinder 11 Indicated Mean Effective Pressure Coefficient of Variance : The indicated mean effective pressure coefficient of variance is the variability seen in IMEP over the number of engine cycles in SPN6394 represented as a percentage.";
CM_ SG_ 2364635134 EngineCylinder11MisfireRate "Engine Cylinder 11 Misfire Rate: The misfire rate of engine Cylinder 11 over the number of engine cycles in SPN6394 represented as a percentage.";
CM_ SG_ 2364635134 EngineCylinder11Temperature "Engine Cylinder 11 Temperature: Gas temperature in cylinder measured at the cylinder head of cylinder 11.";
CM_ BO_ 2364635390 "Engine Cylinder 12 Combustion Metrics";
CM_ SG_ 2364635390 ECd12IsttsPCstPssT "Engine Cylinder 12 Instantaneous Peak Combustion Pressure Timing: The timing in crank angle degrees of the observed peak pressure during the current combustion cycle.  When the combustion happens after the TDC (Top Dead Center) of this cylinder, the ...";
CM_ SG_ 2364635390 ECd12IsttsIdtdMEtvPss "Engine Cylinder 12 Instantaneous Indicated Mean Effective Pressure: The indicated mean effective pressure (IMEP) is the work delivered to the piston over the entire cycle, per unit displaced volume.  This SP reports for the current engine cycle.  See...";
CM_ SG_ 2364635390 ECd12IdtdMEtvPssCtV "Engine Cylinder 12 Indicated Mean Effective Pressure Coefficient of Variance : The indicated mean effective pressure coefficient of variance is the variability seen in IMEP over the number of engine cycles in SPN6394 represented as a percentage.";
CM_ SG_ 2364635390 EngineCylinder12MisfireRate "Engine Cylinder 12 Misfire Rate: The misfire rate of engine Cylinder 12 over the number of engine cycles in SPN6394 represented as a percentage.";
CM_ SG_ 2364635390 EngineCylinder12Temperature "Engine Cylinder 12 Temperature: Gas temperature in cylinder measured at the cylinder head of cylinder 12.";
CM_ BO_ 2364635646 "Engine Cylinder 13 Combustion Metrics";
CM_ SG_ 2364635646 ECd13IsttsPCstPssT "Engine Cylinder 13 Instantaneous Peak Combustion Pressure Timing: The timing in crank angle degrees of the observed peak pressure during the current combustion cycle.  When the combustion happens after the TDC (Top Dead Center) of this cylinder, the ...";
CM_ SG_ 2364635646 ECd13IsttsIdtdMEtvPss "Engine Cylinder 13 Instantaneous Indicated Mean Effective Pressure: The indicated mean effective pressure (IMEP) is the work delivered to the piston over the entire cycle, per unit displaced volume.  This SP reports for the current engine cycle.  See...";
CM_ SG_ 2364635646 ECd13IdtdMEtvPssCtV "Engine Cylinder 13 Indicated Mean Effective Pressure Coefficient of Variance : The indicated mean effective pressure coefficient of variance is the variability seen in IMEP over the number of engine cycles in SPN6394 represented as a percentage.";
CM_ SG_ 2364635646 EngineCylinder13MisfireRate "Engine Cylinder 13 Misfire Rate: The misfire rate of engine Cylinder 13 over the number of engine cycles in SPN6394 represented as a percentage.";
CM_ SG_ 2364635646 EngineCylinder13Temperature "Engine Cylinder 13 Temperature: Gas temperature in cylinder measured at the cylinder head of cylinder 13.";
CM_ BO_ 2364635902 "Engine Cylinder 14 Combustion Metrics";
CM_ SG_ 2364635902 ECd14IsttsPCstPssT "Engine Cylinder 14 Instantaneous Peak Combustion Pressure Timing: The timing in crank angle degrees of the observed peak pressure during the current combustion cycle.  When the combustion happens after the TDC (Top Dead Center) of this cylinder, the ...";
CM_ SG_ 2364635902 ECd14IsttsIdtdMEtvPss "Engine Cylinder 14 Instantaneous Indicated Mean Effective Pressure: The indicated mean effective pressure (IMEP) is the work delivered to the piston over the entire cycle, per unit displaced volume.  This SP reports for the current engine cycle.  See...";
CM_ SG_ 2364635902 ECd14IdtdMEtvPssCtV "Engine Cylinder 14 Indicated Mean Effective Pressure Coefficient of Variance : The indicated mean effective pressure coefficient of variance is the variability seen in IMEP over the number of engine cycles in SPN6394 represented as a percentage.";
CM_ SG_ 2364635902 EngineCylinder14MisfireRate "Engine Cylinder 14 Misfire Rate: The misfire rate of engine Cylinder 14 over the number of engine cycles in SPN6394 represented as a percentage.";
CM_ SG_ 2364635902 EngineCylinder14Temperature "Engine Cylinder 14 Temperature: Gas temperature in cylinder measured at the cylinder head of cylinder 14.";
CM_ BO_ 2364636158 "Engine Cylinder 15 Combustion Metrics";
CM_ SG_ 2364636158 ECd15IsttsPCstPssT "Engine Cylinder 15 Instantaneous Peak Combustion Pressure Timing: The timing in crank angle degrees of the observed peak pressure during the current combustion cycle.  When the combustion happens after the TDC (Top Dead Center) of this cylinder, the ...";
CM_ SG_ 2364636158 ECd15IsttsIdtdMEtvPss "Engine Cylinder 15 Instantaneous Indicated Mean Effective Pressure: The indicated mean effective pressure (IMEP) is the work delivered to the piston over the entire cycle, per unit displaced volume.  This SP reports for the current engine cycle.  See...";
CM_ SG_ 2364636158 ECd15IdtdMEtvPssCtV "Engine Cylinder 15 Indicated Mean Effective Pressure Coefficient of Variance : The indicated mean effective pressure coefficient of variance is the variability seen in IMEP over the number of engine cycles in SPN6394 represented as a percentage.";
CM_ SG_ 2364636158 EngineCylinder15MisfireRate "Engine Cylinder 15 Misfire Rate: The misfire rate of engine Cylinder 15 over the number of engine cycles in SPN6394 represented as a percentage.";
CM_ SG_ 2364636158 EngineCylinder15Temperature "Engine Cylinder 15 Temperature: Gas temperature in cylinder measured at the cylinder head of cylinder 15.";
CM_ BO_ 2364636414 "Engine Cylinder 16 Combustion Metrics";
CM_ SG_ 2364636414 ECd16IsttsPCstPssT "Engine Cylinder 16 Instantaneous Peak Combustion Pressure Timing: The timing in crank angle degrees of the observed peak pressure during the current combustion cycle.  When the combustion happens after the TDC (Top Dead Center) of this cylinder, the ...";
CM_ SG_ 2364636414 ECd16IsttsIdtdMEtvPss "Engine Cylinder 16 Instantaneous Indicated Mean Effective Pressure: The indicated mean effective pressure (IMEP) is the work delivered to the piston over the entire cycle, per unit displaced volume.  This SP reports for the current engine cycle.  See...";
CM_ SG_ 2364636414 ECd16IdtdMEtvPssCtV "Engine Cylinder 16 Indicated Mean Effective Pressure Coefficient of Variance : The indicated mean effective pressure coefficient of variance is the variability seen in IMEP over the number of engine cycles in SPN6394 represented as a percentage.";
CM_ SG_ 2364636414 EngineCylinder16MisfireRate "Engine Cylinder 16 Misfire Rate: The misfire rate of engine Cylinder 16 over the number of engine cycles in SPN6394 represented as a percentage.";
CM_ SG_ 2364636414 EngineCylinder16Temperature "Engine Cylinder 16 Temperature: Gas temperature in cylinder measured at the cylinder head of cylinder 16.";
CM_ BO_ 2364636670 "Engine Cylinder 17 Combustion Metrics";
CM_ SG_ 2364636670 ECd17IsttsPCstPssT "Engine Cylinder 17 Instantaneous Peak Combustion Pressure Timing: The timing in crank angle degrees of the observed peak pressure during the current combustion cycle.  When the combustion happens after the TDC (Top Dead Center) of this cylinder, the ...";
CM_ SG_ 2364636670 ECd17IsttsIdtdMEtvPss "Engine Cylinder 17 Instantaneous Indicated Mean Effective Pressure: The indicated mean effective pressure (IMEP) is the work delivered to the piston over the entire cycle, per unit displaced volume.  This SP reports for the current engine cycle.  See...";
CM_ SG_ 2364636670 ECd17IdtdMEtvPssCtV "Engine Cylinder 17 Indicated Mean Effective Pressure Coefficient of Variance : The indicated mean effective pressure coefficient of variance is the variability seen in IMEP over the number of engine cycles in SPN6394 represented as a percentage.";
CM_ SG_ 2364636670 EngineCylinder17MisfireRate "Engine Cylinder 17 Misfire Rate: The misfire rate of engine Cylinder 17 over the number of engine cycles in SPN6394 represented as a percentage.";
CM_ SG_ 2364636670 EngineCylinder17Temperature "Engine Cylinder 17 Temperature: Gas temperature in cylinder measured at the cylinder head of cylinder 17.";
CM_ BO_ 2364636926 "Engine Cylinder 18 Combustion Metrics";
CM_ SG_ 2364636926 ECd18IsttsPCstPssT "Engine Cylinder 18 Instantaneous Peak Combustion Pressure Timing: The timing in crank angle degrees of the observed peak pressure during the current combustion cycle.  When the combustion happens after the TDC (Top Dead Center) of this cylinder, the ...";
CM_ SG_ 2364636926 ECd18IsttsIdtdMEtvPss "Engine Cylinder 18 Instantaneous Indicated Mean Effective Pressure: The indicated mean effective pressure (IMEP) is the work delivered to the piston over the entire cycle, per unit displaced volume.  This SP reports for the current engine cycle.  See...";
CM_ SG_ 2364636926 ECd18IdtdMEtvPssCtV "Engine Cylinder 18 Indicated Mean Effective Pressure Coefficient of Variance : The indicated mean effective pressure coefficient of variance is the variability seen in IMEP over the number of engine cycles in SPN6394 represented as a percentage.";
CM_ SG_ 2364636926 EngineCylinder18MisfireRate "Engine Cylinder 18 Misfire Rate: The misfire rate of engine Cylinder 18 over the number of engine cycles in SPN6394 represented as a percentage.";
CM_ SG_ 2364636926 EngineCylinder18Temperature "Engine Cylinder 18 Temperature: Gas temperature in cylinder measured at the cylinder head of cylinder 18.";
CM_ BO_ 2364637182 "Engine Cylinder 19 Combustion Metrics";
CM_ SG_ 2364637182 ECd19IsttsPCstPssT "Engine Cylinder 19 Instantaneous Peak Combustion Pressure Timing: The timing in crank angle degrees of the observed peak pressure during the current combustion cycle.  When the combustion happens after the TDC (Top Dead Center) of this cylinder, the ...";
CM_ SG_ 2364637182 ECd19IsttsIdtdMEtvPss "Engine Cylinder 19 Instantaneous Indicated Mean Effective Pressure: The indicated mean effective pressure (IMEP) is the work delivered to the piston over the entire cycle, per unit displaced volume.  This SP reports for the current engine cycle.  See...";
CM_ SG_ 2364637182 ECd19IdtdMEtvPssCtV "Engine Cylinder 19 Indicated Mean Effective Pressure Coefficient of Variance : The indicated mean effective pressure coefficient of variance is the variability seen in IMEP over the number of engine cycles in SPN6394 represented as a percentage.";
CM_ SG_ 2364637182 EngineCylinder19MisfireRate "Engine Cylinder 19 Misfire Rate: The misfire rate of engine Cylinder 19 over the number of engine cycles in SPN6394 represented as a percentage.";
CM_ SG_ 2364637182 EngineCylinder19Temperature "Engine Cylinder 19 Temperature: Gas temperature in cylinder measured at the cylinder head of cylinder 19.";
CM_ BO_ 2364637438 "Engine Cylinder 20 Combustion Metrics";
CM_ SG_ 2364637438 ECd20IsttsPCstPssT "Engine Cylinder 20 Instantaneous Peak Combustion Pressure Timing: The timing in crank angle degrees of the observed peak pressure during the current combustion cycle.  When the combustion happens after the TDC (Top Dead Center) of this cylinder, the ...";
CM_ SG_ 2364637438 ECd20IsttsIdtdMEtvPss "Engine Cylinder 20 Instantaneous Indicated Mean Effective Pressure: The indicated mean effective pressure (IMEP) is the work delivered to the piston over the entire cycle, per unit displaced volume.  This SP reports for the current engine cycle.  See...";
CM_ SG_ 2364637438 ECd20IdtdMEtvPssCtV "Engine Cylinder 20 Indicated Mean Effective Pressure Coefficient of Variance : The indicated mean effective pressure coefficient of variance is the variability seen in IMEP over the number of engine cycles in SPN6394 represented as a percentage.";
CM_ SG_ 2364637438 EngineCylinder20MisfireRate "Engine Cylinder 20 Misfire Rate: The misfire rate of engine Cylinder 20 over the number of engine cycles in SPN6394 represented as a percentage.";
CM_ SG_ 2364637438 EngineCylinder20Temperature "Engine Cylinder 20 Temperature: Gas temperature in cylinder measured at the cylinder head of cylinder 20.";
CM_ BO_ 2364637694 "Motor/Generator 1 Inverter Mode Feedback 1";
CM_ SG_ 2364637694 MtrGnrtr1InvrtrMdFdk1CRC "Motor/Generator 1 Inverter Mode Feedback 1 CRC: The CRC is defined as follows: • Length: 8 bits • Polynomial: x^8+x^5+x^3+x^2+x+1 • Initial Value: FFh • Input Data Reflection: Not reflected • Result Data Reflection: Not reflected • XOR value: FFhSAE ...";
CM_ SG_ 2364637694 MtrGnrtr1InvrtrMdFdk1Cntr "Motor/Generator 1 Inverter Mode Feedback 1 Counter: The message counter is used to detect situations where the transmitting ECU malfunction repeats the same frame all the time. The receiver of the information may use the counter parameter to detect t...";
CM_ SG_ 2364637694 MtrGnrtr1InvrtrCntrlLmtsOvrrdMd "Motor/Generator 1 Inverter Control Limits Override Mode: During normal operation this will have the same value as SPN 10159 [Control Limits Request Override Mode].  0 = Operating limits are not overridden.  If a limit was previously active, then it h...";
CM_ SG_ 2364637694 MtrGnrtr1InvrtrCntrlStpntMd "Motor/Generator 1 Inverter Control Setpoint Mode: Reports the inverter mode (See SPN 10162 [Control Setpoint Mode Request] for requested mode).Passive modes:  0 = Powered On - the inverter is commanded to be powered on and able to communicate, but th...";
CM_ SG_ 2364637694 MtrGnrtr1InvrtrHVILStts "Motor/Generator 1 Inverter HVIL Status: Reports the High Voltage Interlock Loop (HVIL) state.00b = HVIL Closed01b = HVIL Open10b = Error11b = Not Available";
CM_ BO_ 2565964542 "Motor/Generator 1 Inverter Limits Active Power";
CM_ SG_ 2565964542 MtrGnrtr1InvrtrLmtsAtvPwrCRC "Motor/Generator 1 Inverter Limits Active Power CRC: The CRC is defined as follows: • Length: 8 bits • Polynomial: x^8+x^5+x^3+x^2+x+1 • Initial Value: FFh • Input Data Reflection: Not reflected • Result Data Reflection: Not reflected • XOR value: FFh...";
CM_ SG_ 2565964542 MtrGnrtr1InvrtrLmtsAtvPwrCntr "Motor/Generator 1 Inverter Limits Active Power Counter: The message counter is used to detect situations where the transmitting ECU malfunction repeats the same frame all the time. The receiver of the information may use the counter parameter to dete...";
CM_ BO_ 2565964798 "Motor/Generator 1 Inverter Limits Active Mechanical";
CM_ SG_ 2565964798 MtrGnrtr1InvrtrLmtsAtvMhnlCRC "Motor/Generator 1 Inverter Limits Active Mechanical CRC: The CRC is defined as follows: • Length: 8 bits • Polynomial: x^8+x^5+x^3+x^2+x+1 • Initial Value: FFh • Input Data Reflection: Not reflected • Result Data Reflection: Not reflected • XOR value...";
CM_ SG_ 2565964798 MtrGnrtr1InvrtrLmtsAtvMhnlCntr "Motor/Generator 1 Inverter Limits Active Mechanical Counter: The message counter is used to detect situations where the transmitting ECU malfunction repeats the same frame all the time. The receiver of the information may use the counter parameter to...";
CM_ BO_ 2565965054 "Motor/Generator 1 Inverter Limits Active DC Side";
CM_ SG_ 2565965054 MtrGnrtr1InvrtrLmtsAtvDCSdCRC "Motor/Generator 1 Inverter Limits Active DC Side CRC: The CRC is defined as follows: • Length: 8 bits • Polynomial: x^8+x^5+x^3+x^2+x+1 • Initial Value: FFh • Input Data Reflection: Not reflected • Result Data Reflection: Not reflected • XOR value: F...";
CM_ SG_ 2565965054 MtrGnrtr1InvrtrLmtsAtvDCSdCntr "Motor/Generator 1 Inverter Limits Active DC Side Counter: The message counter is used to detect situations where the transmitting ECU malfunction repeats the same frame all the time. The receiver of the information may use the counter parameter to de...";
CM_ BO_ 2565965310 "Motor/Generator 1 Inverter Low Voltage";
CM_ SG_ 2565965310 MtrGnrtr1InvrtrSwthdIgntnVltg "Motor/Generator 1 Inverter Switched Ignition Voltage: Switched Ignition voltage supplied to this instance of the inverter controller.";
CM_ SG_ 2565965310 MtrGnrtr1InvrtrUnswthdSLIVltg "Motor/Generator 1 Inverter Unswitched SLI Voltage: Continuously supplied SLI power to this instance of the inverter controller.";
CM_ BO_ 2364638974 "Motor/Generator 2 Inverter Mode Feedback 1";
CM_ SG_ 2364638974 MtrGnrtr2InvrtrMdFdk1CRC "Motor/Generator 2 Inverter Mode Feedback 1 CRC: The CRC is defined as follows: • Length: 8 bits • Polynomial: x^8+x^5+x^3+x^2+x+1 • Initial Value: FFh • Input Data Reflection: Not reflected • Result Data Reflection: Not reflected • XOR value: FFhSAE ...";
CM_ SG_ 2364638974 MtrGnrtr2InvrtrMdFdk1Cntr "Motor/Generator 2 Inverter Mode Feedback 1 Counter: The message counter is used to detect situations where the transmitting ECU malfunction repeats the same frame all the time. The receiver of the information may use the counter parameter to detect t...";
CM_ SG_ 2364638974 MtrGnrtr2InvrtrCntrlLmtsOvrrdMd "Motor/Generator 2 Inverter Control Limits Override Mode: During normal operation this will have the same value as SPN 10225 [Control Limits Request Override Mode].0 = Operating limits are not overridden.  If a limit was previously active, then it has...";
CM_ SG_ 2364638974 MtrGnrtr2InvrtrCntrlStpntMd "Motor/Generator 2 Inverter Control Setpoint Mode: Reports the inverter mode (See SPN 10228 [Control Setpoint Mode Request] for requested mode).Passive modes:  0 = Powered On - the inverter is commanded to be powered on and able to communicate, but th...";
CM_ SG_ 2364638974 MtrGnrtr2InvrtrHVILStts "Motor/Generator 2 Inverter HVIL Status: Reports the High Voltage Interlock Loop (HVIL) state.00b = HVIL Closed01b = HVIL Open10b = Error11b = Not Available";
CM_ BO_ 2565965822 "Motor/Generator 2 Inverter Limits Active Power";
CM_ SG_ 2565965822 MtrGnrtr2InvrtrLmtsAtvPwrCRC "Motor/Generator 2 Inverter Limits Active Power CRC: The CRC is defined as follows: • Length: 8 bits • Polynomial: x^8+x^5+x^3+x^2+x+1 • Initial Value: FFh • Input Data Reflection: Not reflected • Result Data Reflection: Not reflected • XOR value: FFh...";
CM_ SG_ 2565965822 MtrGnrtr2InvrtrLmtsAtvPwrCntr "Motor/Generator 2 Inverter Limits Active Power Counter: The message counter is used to detect situations where the transmitting ECU malfunction repeats the same frame all the time. The receiver of the information may use the counter parameter to dete...";
CM_ BO_ 2565966078 "Motor/Generator 2 Inverter Limits Active Mechanical";
CM_ SG_ 2565966078 MtrGnrtr2InvrtrLmtsAtvMhnlCRC "Motor/Generator 2 Inverter Limits Active Mechanical CRC: The CRC is defined as follows: • Length: 8 bits • Polynomial: x^8+x^5+x^3+x^2+x+1 • Initial Value: FFh • Input Data Reflection: Not reflected • Result Data Reflection: Not reflected • XOR value...";
CM_ SG_ 2565966078 MtrGnrtr2InvrtrLmtsAtvMhnlCntr "Motor/Generator 2 Inverter Limits Active Mechanical Counter: The message counter is used to detect situations where the transmitting ECU malfunction repeats the same frame all the time. The receiver of the information may use the counter parameter to...";
CM_ BO_ 2565966334 "Motor/Generator 2 Inverter Limits Active DC Side";
CM_ SG_ 2565966334 MtrGnrtr2InvrtrLmtsAtvDCSdCRC "Motor/Generator 2 Inverter Limits Active DC Side CRC: The CRC is defined as follows: • Length: 8 bits • Polynomial: x^8+x^5+x^3+x^2+x+1 • Initial Value: FFh • Input Data Reflection: Not reflected • Result Data Reflection: Not reflected • XOR value: F...";
CM_ SG_ 2565966334 MtrGnrtr2InvrtrLmtsAtvDCSdCntr "Motor/Generator 2 Inverter Limits Active DC Side Counter: The message counter is used to detect situations where the transmitting ECU malfunction repeats the same frame all the time. The receiver of the information may use the counter parameter to de...";
CM_ BO_ 2565966590 "Motor/Generator 2 Inverter Low Voltage";
CM_ SG_ 2565966590 MtrGnrtr2InvrtrSwthdIgntnVltg "Motor/Generator 2 Inverter Switched Ignition Voltage: Switched Ignition voltage supplied to this instance of the inverter controller.";
CM_ SG_ 2565966590 MtrGnrtr2InvrtrUnswthdSLIVltg "Motor/Generator 2 Inverter Unswitched SLI Voltage: Continuously supplied SLI power to this instance of the inverter controller.";
CM_ BO_ 2365287678 "Motor/Generator 2 Inverter Reference 1";
CM_ SG_ 2365287678 MtrGnrtr2InvrtrRfrn1CRC "Motor/Generator 2 Inverter Reference 1 CRC: The CRC is defined as follows: • Length: 8 bits • Polynomial: x^8+x^5+x^3+x^2+x+1 • Initial Value: FFh • Input Data Reflection: Not reflected • Result Data Reflection: Not reflected • XOR value: FFhSAE make...";
CM_ SG_ 2365287678 MtrGnrtr2InvrtrRfrn1Cntr "Motor/Generator 2 Inverter Reference 1 Counter: The message counter is used to detect situations where the transmitting ECU malfunction repeats the same frame all the time. The receiver of the information may use the counter parameter to detect this ...";
CM_ SG_ 2365287678 MtrGnrtr2InvrtrRfrnTrq "Motor/Generator 2 Inverter Reference Torque: This value is used for converting torque in percent to units of Nm.Value in Nm = (Percent Value)/(100%) * (Reference Torque)For example, if this parameter has a value of 400 Nm and the percent value is equ...";
CM_ SG_ 2365287678 MtrGnrtr2InvrtrRfrnSpd "Motor/Generator 2 Inverter Reference Speed: This value is used for converting Speed in percent to units of rpm.Value in rpm = (Percent Value)/(100%) * (Reference Speed)For example, if this parameter has a value of 8192 rpm and the percent value is eq...";
CM_ SG_ 2365287678 MtrGnrtr2InvrtrRfrnPwr "Motor/Generator 2 Inverter Reference Power: This value is used for converting power in percent to units of kW.  It is applicable to both mechanical and electrical power.(Value in kW) = (Percent Value)/(100%) * (Reference Power)For example, if this pa...";
CM_ BO_ 2365287934 "Motor/Generator 2 Inverter Status 1";
CM_ SG_ 2365287934 MtrGnrtr2InvrtrStts1CRC "Motor/Generator 2 Inverter Status 1 CRC: The CRC is defined as follows: • Length: 8 bits • Polynomial: x^8+x^5+x^3+x^2+x+1 • Initial Value: FFh • Input Data Reflection: Not reflected • Result Data Reflection: Not reflected • XOR value: FFhSAE makes n...";
CM_ SG_ 2365287934 MtrGnrtr2InvrtrStts1Cntr "Motor/Generator 2 Inverter Status 1 Counter: The message counter is used to detect situations where the transmitting ECU malfunction repeats the same frame all the time. The receiver of the information may use the counter parameter to detect this sit...";
CM_ SG_ 2365287934 MotorGenerator2Speed "Motor/Generator 2 Speed: The measured or estimated motor speed.  This refers to the motor rotor output and excludes any gearbox that may be attached to the motor.   Refer to SPN 10237 [Reference Speed] to convert % to rpm.The motor is generating when...";
CM_ BO_ 2365288190 "Motor/Generator 2 Inverter Reference 2";
CM_ SG_ 2365288190 MtrGnrtr2InvrtrRfrn2CRC "Motor/Generator 2 Inverter Reference 2 CRC: The CRC is defined as follows: • Length: 8 bits • Polynomial: x^8+x^5+x^3+x^2+x+1 • Initial Value: FFh • Input Data Reflection: Not reflected • Result Data Reflection: Not reflected • XOR value: FFhSAE make...";
CM_ SG_ 2365288190 MtrGnrtr2InvrtrRfrn2Cntr "Motor/Generator 2 Inverter Reference 2 Counter: The message counter is used to detect situations where the transmitting ECU malfunction repeats the same frame all the time. The receiver of the information may use the counter parameter to detect this ...";
CM_ SG_ 2365288190 MtrGnrtr2InvrtrRfrnCrrnt "Motor/Generator 2 Inverter Reference Current: This value is used for converting inverter current in percent to units of Amps (RMS or DC).(Value in Amps) = (Percent Value)/(100%) * (Reference Current)For example, if this parameter has a value of 200 A...";
CM_ SG_ 2365288190 MtrGnrtr2InvrtrRfrnVltg "Motor/Generator 2 Inverter Reference Voltage: This value is used for converting inverter voltage in percent to units of Volts (RMS or DC).(Value in Volts) = (Percent Value)/(100%) * (Reference Voltage)For example, if this parameter has a value of 400...";
CM_ BO_ 2566615038 "Motor/Generator 2 Inverter Temperature";
CM_ SG_ 2566615038 MtrGnrtr2InvrtrTmprtr1 "Motor/Generator 2 Inverter Temperature 1: The exact location of this temperature can be defined by the manufacturer.  It is intended to be located somewhere on the inverter. ";
CM_ SG_ 2566615038 MtrGnrtr2InvrtrTmprtr2 "Motor/Generator 2 Inverter Temperature 2: The exact location of this temperature can be defined by the manufacturer.  It is intended to be located somewhere on the inverter. ";
CM_ SG_ 2566615038 MtrGnrtr2InvrtrTmprtr3 "Motor/Generator 2 Inverter Temperature 3: The exact location of this temperature can be defined by the manufacturer.  It is intended to be located somewhere on the inverter. ";
CM_ SG_ 2566615038 MtrGnrtr2InvrtrTmprtr4 "Motor/Generator 2 Inverter Temperature 4: The exact location of this temperature can be defined by the manufacturer.  It is intended to be located somewhere on the inverter. ";
CM_ BO_ 2566615294 "Motor/Generator 2 Inverter Motor Temperature";
CM_ SG_ 2566615294 MotorGenerator2Temperature1 "Motor/Generator 2 Temperature 1: The exact location of this temperature can be defined by the manufacturer.  It is intended to located somewhere on the motor.";
CM_ SG_ 2566615294 MotorGenerator2Temperature2 "Motor/Generator 2 Temperature 2: The exact location of this temperature can be defined by the manufacturer.  It is intended to located somewhere on the motor. ";
CM_ SG_ 2566615294 MotorGenerator2Temperature3 "Motor/Generator 2 Temperature 3: The exact location of this temperature can be defined by the manufacturer.  It is intended to located somewhere on the motor. ";
CM_ SG_ 2566615294 MotorGenerator2Temperature4 "Motor/Generator 2 Temperature 4: The exact location of this temperature can be defined by the manufacturer.  It is intended to located somewhere on the motor. ";
CM_ BO_ 2566615550 "Motor/Generator 1 Inverter Motor Temperature";
CM_ SG_ 2566615550 MotorGenerator1Temperature1 "Motor/Generator 1 Temperature 1: The exact location of this temperature can be defined by the manufacturer.  It is intended to located somewhere on the motor.";
CM_ SG_ 2566615550 MotorGenerator1Temperature2 "Motor/Generator 1 Temperature 2: The exact location of this temperature can be defined by the manufacturer.  It is intended to located somewhere on the motor. ";
CM_ SG_ 2566615550 MotorGenerator1Temperature3 "Motor/Generator 1 Temperature 3: The exact location of this temperature can be defined by the manufacturer.  It is intended to located somewhere on the motor. ";
CM_ SG_ 2566615550 MotorGenerator1Temperature4 "Motor/Generator 1 Temperature 4: The exact location of this temperature can be defined by the manufacturer.  It is intended to located somewhere on the motor. ";
CM_ BO_ 2566615806 "Motor/Generator 1 Inverter Temperature";
CM_ SG_ 2566615806 MtrGnrtr1InvrtrTmprtr1 "Motor/Generator 1 Inverter Temperature 1: The exact location of this temperature can be defined by the manufacturer.  It is intended to be located somewhere on the inverter. ";
CM_ SG_ 2566615806 MtrGnrtr1InvrtrTmprtr2 "Motor/Generator 1 Inverter Temperature 2: The exact location of this temperature can be defined by the manufacturer.  It is intended to be located somewhere on the inverter. ";
CM_ SG_ 2566615806 MtrGnrtr1InvrtrTmprtr3 "Motor/Generator 1 Inverter Temperature 3: The exact location of this temperature can be defined by the manufacturer.  It is intended to be located somewhere on the inverter. ";
CM_ SG_ 2566615806 MtrGnrtr1InvrtrTmprtr4 "Motor/Generator 1 Inverter Temperature 4: The exact location of this temperature can be defined by the manufacturer.  It is intended to be located somewhere on the inverter. ";
CM_ BO_ 2365289470 "Motor/Generator 1 Inverter Reference 2";
CM_ SG_ 2365289470 MtrGnrtr1InvrtrRfrn2CRC "Motor/Generator 1 Inverter Reference 2 CRC: The CRC is defined as follows: • Length: 8 bits • Polynomial: x^8+x^5+x^3+x^2+x+1 • Initial Value: FFh • Input Data Reflection: Not reflected • Result Data Reflection: Not reflected • XOR value: FFhSAE make...";
CM_ SG_ 2365289470 MtrGnrtr1InvrtrRfrn2Cntr "Motor/Generator 1 Inverter Reference 2 Counter: The message counter is used to detect situations where the transmitting ECU malfunction repeats the same frame all the time. The receiver of the information may use the counter parameter to detect this ...";
CM_ SG_ 2365289470 MtrGnrtr1InvrtrRfrnCrrnt "Motor/Generator 1 Inverter Reference Current: This value is used for converting inverter current in percent to units of Amps (RMS or DC).(Value in Amps) = (Percent Value)/(100%) * (Reference Current)For example, if this parameter has a value of 200 A...";
CM_ SG_ 2365289470 MtrGnrtr1InvrtrRfrnVltg "Motor/Generator 1 Inverter Reference Voltage: This value is used for converting inverter voltage in percent to units of Volts (RMS or DC).(Value in Volts) = (Percent Value)/(100%) * (Reference Voltage)For example, if this parameter has a value of 400...";
CM_ BO_ 2365289726 "Motor/Generator 1 Inverter Status 1";
CM_ SG_ 2365289726 MtrGnrtr1InvrtrStts1CRC "Motor/Generator 1 Inverter Status 1 CRC: The CRC is defined as follows: • Length: 8 bits • Polynomial: x^8+x^5+x^3+x^2+x+1 • Initial Value: FFh • Input Data Reflection: Not reflected • Result Data Reflection: Not reflected • XOR value: FFhSAE makes n...";
CM_ SG_ 2365289726 MtrGnrtr1InvrtrStts1Cntr "Motor/Generator 1 Inverter Status 1 Counter: The message counter is used to detect situations where the transmitting ECU malfunction repeats the same frame all the time. The receiver of the information may use the counter parameter to detect this sit...";
CM_ SG_ 2365289726 MotorGenerator1Torque "Motor/Generator 1 Torque: The measured or estimated motor torque.  This refers to the motor rotor output and excludes any gearbox that may be attached to the motor.Refer to SPN 10170 [Reference Torque] to convert % to Nm.The motor is generating when ...";
CM_ SG_ 2365289726 MotorGenerator1Speed "Motor/Generator 1 Speed: The measured or estimated motor speed.  This refers to the motor rotor output and excludes any gearbox that may be attached to the motor.   Refer to SPN 10171 [Reference Speed] to convert % to rpm.";
CM_ SG_ 2365289726 MtrGnrtr1InvrtrDCSdVltg "Motor/Generator 1 Inverter DC Side Voltage: The measured or estimated DC side voltage.  Refer to SPN 10203 [Reference Voltage] to convert % to Volts.";
CM_ SG_ 2365289726 MtrGnrtr1InvrtrDCSdCrrnt "Motor/Generator 1 Inverter DC Side Current: This is the DC side current of the inverter.Refer to SPN 10202 [Reference Current] to convert % to Amps.While motoring, the current is defined as positive.  For example, in a hybrid propulsion system, posit...";
CM_ BO_ 2365289982 "Motor/Generator 1 Inverter Reference 1";
CM_ SG_ 2365289982 MtrGnrtr1InvrtrRfrn1CRC "Motor/Generator 1 Inverter Reference 1 CRC: The CRC is defined as follows: • Length: 8 bits • Polynomial: x^8+x^5+x^3+x^2+x+1 • Initial Value: FFh • Input Data Reflection: Not reflected • Result Data Reflection: Not reflected • XOR value: FFhSAE make...";
CM_ SG_ 2365289982 MtrGnrtr1InvrtrRfrn1Cntr "Motor/Generator 1 Inverter Reference 1 Counter: The message counter is used to detect situations where the transmitting ECU malfunction repeats the same frame all the time. The receiver of the information may use the counter parameter to detect this ...";
CM_ SG_ 2365289982 MtrGnrtr1InvrtrRfrnTrq "Motor/Generator 1 Inverter Reference Torque: This value is used for converting torque in percent to units of Nm.Value in Nm = (Percent Value)/(100%) * (Reference Torque)For example, if this parameter has a value of 400 Nm and the percent value is equ...";
CM_ SG_ 2365289982 MtrGnrtr1InvrtrRfrnSpd "Motor/Generator 1 Inverter Reference Speed: This value is used for converting Speed in percent to units of rpm.Value in rpm = (Percent Value)/(100%) * (Reference Speed)For example, if this parameter has a value of 8192 rpm and the percent value is eq...";
CM_ SG_ 2365289982 MtrGnrtr1InvrtrRfrnPwr "Motor/Generator 1 Inverter Reference Power: This value is used for converting power in percent to units of kW.  It is applicable to both mechanical and electrical power.(Value in kW) = (Percent Value)/(100%) * (Reference Power)For example, if this pa...";
CM_ BO_ 2566616830 "Personnel Detect Status";
CM_ SG_ 2566616830 DetectionLocation1 "Detection Location 1: Identifies the location of the detection area associated with Zone Alarm Status 1 (SPN 10134) reported in the message. The detection location identifies a directional area of detection from the vehicle. When the PG contains Zone...";
CM_ SG_ 2566616830 DetectionZone1 "Detection Zone 1: Identifies the detection zone associated with Zone Alarm Status 1 (SPN 10134) reported in the message. A detection zone identifies spatial area within the detection location specified by Detection Location 1 (SPN 13133). When the PG...";
CM_ SG_ 2566616830 ZoneAlarmStatus1 "Zone Alarm Status 1: Indicates the alarm status for detection of personnel within the detection zone identified by Detection Zone 1 (SPN 10132) and Detection Location 1 (SPN 10133).0000b = No Alarm Active0001b = Alarm Active0010b = Reserved for SAE a...";
CM_ SG_ 2566616830 DetectionLocation2 "Detection Location 2: Identifies the location of the detection area associated with Zone Alarm Status 2 (SPN 10137) reported in the message. The detection location identifies a directional area of detection from the vehicle. When the PG contains Zone...";
CM_ SG_ 2566616830 DetectionZone2 "Detection Zone 2: Identifies the detection zone associated with Zone Alarm Status 2 (SPN 10137) reported in the message. A detection zone identifies spatial area within the detection location specified by Detection Location 2 (SPN 10136). When the PG...";
CM_ SG_ 2566616830 ZoneAlarmStatus2 "Zone Alarm Status 2: Indicates the alarm status for detection of personnel within the detection zone identified by Detection Zone 2 (SPN 10135) and Detection Location 2 (SPN 10136).0000b = No Alarm Active0001b = Alarm Active0010b = Reserved for SAE a...";
CM_ SG_ 2566616830 DetectionLocation3 "Detection Location 3: Identifies the location of the detection area associated with Zone Alarm Status 3 (SPN 10140) reported in the message. The detection location identifies a directional area of detection from the vehicle. When the PG contains Zone...";
CM_ SG_ 2566616830 DetectionZone3 "Detection Zone 3: Identifies the detection zone associated with Zone Alarm Status 3 (SPN 10140) reported in the message. A detection zone identifies spatial area within the detection location specified by Detection Location 3 (SPN 10139). When the PG...";
CM_ SG_ 2566616830 ZoneAlarmStatus3 "Zone Alarm Status 3: Indicates the alarm status for detection of personnel within the detection zone identified by Detection Zone 3 (SPN 10138) and Detection Location 3 (SPN 10139).0000b = No Alarm Active0001b = Alarm Active0010b = Reserved for SAE a...";
CM_ SG_ 2566616830 PersonnelDetectSequenceCounter "Personnel Detect Sequence Counter: A counter value which increments per each transmission of data. If Personnel Detect Status consists of multiple messages then each message in the group shall share the same Sequence Counter value.NOTE - The counter ...";
CM_ BO_ 2566617086 "Engine Cylinder Pressure Gamma 1";
CM_ SG_ 2566617086 EngnClndr1CmprssnGmmRt "Engine Cylinder 1 Compression Gamma Ratio: The compression gamma ratio is defined as Log(pressure)/Log(volume) of the cylinder pressure curve during the compression stroke of the current engine cycle for engine cylinder 1.  The SP will report FB00h (...";
CM_ SG_ 2566617086 EngnClndr1ExpnsnGmmRt "Engine Cylinder 1 Expansion Gamma Ratio: The expansion gamma ratio is defined as Log(pressure)/Log(volume) of the cylinder pressure curve during the expansion stroke of the current engine cycle for engine cylinder 1.  The SP will report FB00h (64256)...";
CM_ SG_ 2566617086 EngnClndr2CmprssnGmmRt "Engine Cylinder 2 Compression Gamma Ratio: The compression gamma ratio is defined as Log(pressure)/Log(volume) of the cylinder pressure curve during the compression stroke of the current engine cycle for engine cylinder 2.  The SP will report FB00h (...";
CM_ SG_ 2566617086 EngnClndr2ExpnsnGmmRt "Engine Cylinder 2 Expansion Gamma Ratio: The expansion gamma ratio is defined as Log(pressure)/Log(volume) of the cylinder pressure curve during the expansion stroke of the current engine cycle for engine cylinder 2.  The SP will report FB00h (64256)...";
CM_ SG_ 2566617086 EngnClndr3CmprssnGmmRt "Engine Cylinder 3 Compression Gamma Ratio: The compression gamma ratio is defined as Log(pressure)/Log(volume) of the cylinder pressure curve during the compression stroke of the current engine cycle for engine cylinder 3.  The SP will report FB00h (...";
CM_ SG_ 2566617086 EngnClndr3ExpnsnGmmRt "Engine Cylinder 3 Expansion Gamma Ratio: The expansion gamma ratio is defined as Log(pressure)/Log(volume) of the cylinder pressure curve during the expansion stroke of the current engine cycle for engine cylinder 3.  The SP will report FB00h (64256)...";
CM_ SG_ 2566617086 EngnClndr4CmprssnGmmRt "Engine Cylinder 4 Compression Gamma Ratio: The compression gamma ratio is defined as Log(pressure)/Log(volume) of the cylinder pressure curve during the compression stroke of the current engine cycle for engine cylinder 4.  The SP will report FB00h (...";
CM_ SG_ 2566617086 EngnClndr4ExpnsnGmmRt "Engine Cylinder 4 Expansion Gamma Ratio: The expansion gamma ratio is defined as Log(pressure)/Log(volume) of the cylinder pressure curve during the expansion stroke of the current engine cycle for engine cylinder 4.  The SP will report FB00h (64256)...";
CM_ BO_ 2566617342 "Engine Cylinder Pressure Gamma 2";
CM_ SG_ 2566617342 EngnClndr5CmprssnGmmRt "Engine Cylinder 5 Compression Gamma Ratio: The compression gamma ratio is defined as Log(pressure)/Log(volume) of the cylinder pressure curve during the compression stroke of the current engine cycle for engine Cylinder 5.  The SP will report FB00h (...";
CM_ SG_ 2566617342 EngnClndr5ExpnsnGmmRt "Engine Cylinder 5 Expansion Gamma Ratio: The expansion gamma ratio is defined as Log(pressure)/Log(volume) of the cylinder pressure curve during the expansion stroke of the current engine cycle for engine Cylinder 5.  The SP will report FB00h (64256)...";
CM_ SG_ 2566617342 EngnClndr6CmprssnGmmRt "Engine Cylinder 6 Compression Gamma Ratio: The compression gamma ratio is defined as Log(pressure)/Log(volume) of the cylinder pressure curve during the compression stroke of the current engine cycle for engine Cylinder 6.  The SP will report FB00h (...";
CM_ SG_ 2566617342 EngnClndr6ExpnsnGmmRt "Engine Cylinder 6 Expansion Gamma Ratio: The expansion gamma ratio is defined as Log(pressure)/Log(volume) of the cylinder pressure curve during the expansion stroke of the current engine cycle for engine Cylinder 6.  The SP will report FB00h (64256)...";
CM_ SG_ 2566617342 EngnClndr7CmprssnGmmRt "Engine Cylinder 7 Compression Gamma Ratio: The compression gamma ratio is defined as Log(pressure)/Log(volume) of the cylinder pressure curve during the compression stroke of the current engine cycle for engine Cylinder 7.  The SP will report FB00h (...";
CM_ SG_ 2566617342 EngnClndr7ExpnsnGmmRt "Engine Cylinder 7 Expansion Gamma Ratio: The expansion gamma ratio is defined as Log(pressure)/Log(volume) of the cylinder pressure curve during the expansion stroke of the current engine cycle for engine Cylinder 7.  The SP will report FB00h (64256)...";
CM_ SG_ 2566617342 EngnClndr8CmprssnGmmRt "Engine Cylinder 8 Compression Gamma Ratio: The compression gamma ratio is defined as Log(pressure)/Log(volume) of the cylinder pressure curve during the compression stroke of the current engine cycle for engine Cylinder 8.  The SP will report FB00h (...";
CM_ SG_ 2566617342 EngnClndr8ExpnsnGmmRt "Engine Cylinder 8 Expansion Gamma Ratio: The expansion gamma ratio is defined as Log(pressure)/Log(volume) of the cylinder pressure curve during the expansion stroke of the current engine cycle for engine Cylinder 8.  The SP will report FB00h (64256)...";
CM_ BO_ 2566617598 "Engine Cylinder Pressure Gamma 3";
CM_ SG_ 2566617598 EngnClndr9CmprssnGmmRt "Engine Cylinder 9 Compression Gamma Ratio: The compression gamma ratio is defined as Log(pressure)/Log(volume) of the cylinder pressure curve during the compression stroke of the current engine cycle for engine Cylinder 9.  The SP will report FB00h (...";
CM_ SG_ 2566617598 EngnClndr9ExpnsnGmmRt "Engine Cylinder 9 Expansion Gamma Ratio: The expansion gamma ratio is defined as Log(pressure)/Log(volume) of the cylinder pressure curve during the expansion stroke of the current engine cycle for engine Cylinder 9.  The SP will report FB00h (64256)...";
CM_ SG_ 2566617598 EngnClndr10CmprssnGmmRt "Engine Cylinder 10 Compression Gamma Ratio: The compression gamma ratio is defined as Log(pressure)/Log(volume) of the cylinder pressure curve during the compression stroke of the current engine cycle for engine Cylinder 10.  The SP will report FB00h...";
CM_ SG_ 2566617598 EngnClndr10ExpnsnGmmRt "Engine Cylinder 10 Expansion Gamma Ratio: The expansion gamma ratio is defined as Log(pressure)/Log(volume) of the cylinder pressure curve during the expansion stroke of the current engine cycle for engine Cylinder 10.  The SP will report FB00h (6425...";
CM_ SG_ 2566617598 EngnClndr11CmprssnGmmRt "Engine Cylinder 11 Compression Gamma Ratio: The compression gamma ratio is defined as Log(pressure)/Log(volume) of the cylinder pressure curve during the compression stroke of the current engine cycle for engine Cylinder 11.  The SP will report FB00h...";
CM_ SG_ 2566617598 EngnClndr11ExpnsnGmmRt "Engine Cylinder 11 Expansion Gamma Ratio: The expansion gamma ratio is defined as Log(pressure)/Log(volume) of the cylinder pressure curve during the expansion stroke of the current engine cycle for engine Cylinder 11.  The SP will report FB00h (6425...";
CM_ SG_ 2566617598 EngnClndr12CmprssnGmmRt "Engine Cylinder 12 Compression Gamma Ratio: The compression gamma ratio is defined as Log(pressure)/Log(volume) of the cylinder pressure curve during the compression stroke of the current engine cycle for engine Cylinder 12.  The SP will report FB00h...";
CM_ SG_ 2566617598 EngnClndr12ExpnsnGmmRt "Engine Cylinder 12 Expansion Gamma Ratio: The expansion gamma ratio is defined as Log(pressure)/Log(volume) of the cylinder pressure curve during the expansion stroke of the current engine cycle for engine Cylinder 12.  The SP will report FB00h (6425...";
CM_ BO_ 2566617854 "Engine Cylinder Pressure Gamma 4";
CM_ SG_ 2566617854 EngnClndr13CmprssnGmmRt "Engine Cylinder 13 Compression Gamma Ratio: The compression gamma ratio is defined as Log(pressure)/Log(volume) of the cylinder pressure curve during the compression stroke of the current engine cycle for engine Cylinder 13.  The SP will report FB00h...";
CM_ SG_ 2566617854 EngnClndr13ExpnsnGmmRt "Engine Cylinder 13 Expansion Gamma Ratio: The expansion gamma ratio is defined as Log(pressure)/Log(volume) of the cylinder pressure curve during the expansion stroke of the current engine cycle for engine Cylinder 13.  The SP will report FB00h (6425...";
CM_ SG_ 2566617854 EngnClndr14CmprssnGmmRt "Engine Cylinder 14 Compression Gamma Ratio: The compression gamma ratio is defined as Log(pressure)/Log(volume) of the cylinder pressure curve during the compression stroke of the current engine cycle for engine Cylinder 14.  The SP will report FB00h...";
CM_ SG_ 2566617854 EngnClndr14ExpnsnGmmRt "Engine Cylinder 14 Expansion Gamma Ratio: The expansion gamma ratio is defined as Log(pressure)/Log(volume) of the cylinder pressure curve during the expansion stroke of the current engine cycle for engine Cylinder 14.  The SP will report FB00h (6425...";
CM_ SG_ 2566617854 EngnClndr15CmprssnGmmRt "Engine Cylinder 15 Compression Gamma Ratio: The compression gamma ratio is defined as Log(pressure)/Log(volume) of the cylinder pressure curve during the compression stroke of the current engine cycle for engine Cylinder 15.  The SP will report FB00h...";
CM_ SG_ 2566617854 EngnClndr15ExpnsnGmmRt "Engine Cylinder 15 Expansion Gamma Ratio: The expansion gamma ratio is defined as Log(pressure)/Log(volume) of the cylinder pressure curve during the expansion stroke of the current engine cycle for engine Cylinder 15.  The SP will report FB00h (6425...";
CM_ SG_ 2566617854 EngnClndr16CmprssnGmmRt "Engine Cylinder 16 Compression Gamma Ratio: The compression gamma ratio is defined as Log(pressure)/Log(volume) of the cylinder pressure curve during the compression stroke of the current engine cycle for engine Cylinder 16.  The SP will report FB00h...";
CM_ SG_ 2566617854 EngnClndr16ExpnsnGmmRt "Engine Cylinder 16 Expansion Gamma Ratio: The expansion gamma ratio is defined as Log(pressure)/Log(volume) of the cylinder pressure curve during the expansion stroke of the current engine cycle for engine Cylinder 16.  The SP will report FB00h (6425...";
CM_ BO_ 2566618110 "Engine Cylinder Pressure Gamma 5";
CM_ SG_ 2566618110 EngnClndr17CmprssnGmmRt "Engine Cylinder 17 Compression Gamma Ratio: The compression gamma ratio is defined as Log(pressure)/Log(volume) of the cylinder pressure curve during the compression stroke of the current engine cycle for engine Cylinder 17.  The SP will report FB00h...";
CM_ SG_ 2566618110 EngnClndr17ExpnsnGmmRt "Engine Cylinder 17 Expansion Gamma Ratio: The expansion gamma ratio is defined as Log(pressure)/Log(volume) of the cylinder pressure curve during the expansion stroke of the current engine cycle for engine Cylinder 17.  The SP will report FB00h (6425...";
CM_ SG_ 2566618110 EngnClndr18CmprssnGmmRt "Engine Cylinder 18 Compression Gamma Ratio: The compression gamma ratio is defined as Log(pressure)/Log(volume) of the cylinder pressure curve during the compression stroke of the current engine cycle for engine Cylinder 18.  The SP will report FB00h...";
CM_ SG_ 2566618110 EngnClndr18ExpnsnGmmRt "Engine Cylinder 18 Expansion Gamma Ratio: The expansion gamma ratio is defined as Log(pressure)/Log(volume) of the cylinder pressure curve during the expansion stroke of the current engine cycle for engine Cylinder 18.  The SP will report FB00h (6425...";
CM_ SG_ 2566618110 EngnClndr19CmprssnGmmRt "Engine Cylinder 19 Compression Gamma Ratio: The compression gamma ratio is defined as Log(pressure)/Log(volume) of the cylinder pressure curve during the compression stroke of the current engine cycle for engine Cylinder 19.  The SP will report FB00h...";
CM_ SG_ 2566618110 EngnClndr19ExpnsnGmmRt "Engine Cylinder 19 Expansion Gamma Ratio: The expansion gamma ratio is defined as Log(pressure)/Log(volume) of the cylinder pressure curve during the expansion stroke of the current engine cycle for engine Cylinder 19.  The SP will report FB00h (6425...";
CM_ SG_ 2566618110 EngnClndr20CmprssnGmmRt "Engine Cylinder 20 Compression Gamma Ratio: The compression gamma ratio is defined as Log(pressure)/Log(volume) of the cylinder pressure curve during the compression stroke of the current engine cycle for engine Cylinder 20.  The SP will report FB00h...";
CM_ SG_ 2566618110 EngnClndr20ExpnsnGmmRt "Engine Cylinder 20 Expansion Gamma Ratio: The expansion gamma ratio is defined as Log(pressure)/Log(volume) of the cylinder pressure curve during the expansion stroke of the current engine cycle for engine Cylinder 20.  The SP will report FB00h (6425...";
CM_ BO_ 2566618622 "Electrified Accessory Generator Coolant Pump Status";
CM_ SG_ 2566618622 GnrtrClntPmpEnlStts "Generator Coolant Pump Enable Status: Enable and direction status of the Generator Coolant Pump system or component.00b = Accessory Motor Off01b = Accessory Motor On - Normal, Forward, or Default Direction10b = Accessory Motor On - Reverse Direction1...";
CM_ SG_ 2566618622 GnrtrClntPmpCntrllrSttsRsnCd "Generator Coolant Pump Controller Status Reason Code: Provides the reason code describing the unique failure of the Generator Coolant Pump system or component.If a detailed reason code is not used by the supporting application, or this reason code is...";
CM_ SG_ 2566618622 GnrtrClntPmpCntrllrCmmndStts "Generator Coolant Pump Controller Command Status: Indicates the source of the speed command to the Generator Coolant Pump system or component.00b is communicated when the controller is self-controlled (e.g. based on a temperature sensor).01b is commu...";
CM_ SG_ 2566618622 GeneratorCoolantPumpMotorSpeed "Generator Coolant Pump Motor Speed: Motor Speed of the Generator Coolant Pump.";
CM_ SG_ 2566618622 GnrtrClntPmpCntrlTmprtr "Generator Coolant Pump Control Temperature: A temperature measured and reported by the device.  It may be used for direct or remote (e.g. by another controller) control of the pump.  For example, this may be the temperature of the fluid flowing throu...";
CM_ SG_ 2566618622 GeneratorCoolantPumpPower "Generator Coolant Pump Power: Calculated electrical power consumed by the Generator Coolant Pump.";
CM_ SG_ 2566618622 GnrtrClntPmpSrvIndtr "Generator Coolant Pump Service Indicator: Indicates that service is required for the Generator Coolant Pump system or component.  An active indication may convey a need for component replacement or periodic service.  The Generator Coolant Pump Contro...";
CM_ SG_ 2566618622 GnrtrClntPmpOprtngStts "Generator Coolant Pump Operating Status: Indicates the operating status of the Generator Coolant Pump system or component.  This parameter is used to inform other devices that this system or component is no longer performing to its operational capaci...";
CM_ BO_ 2566618878 "Electrified Accessory Generator Coolant Fan Status";
CM_ SG_ 2566618878 GeneratorCoolantFanEnableStatus "Generator Coolant Fan Enable Status: Enable and direction status of this Generator Coolant Fan Motor system or component.00b = Accessory Motor Off01b = Accessory Motor On - Normal, Forward, or Default Direction10b = Accessory Motor On - Reverse Direc...";
CM_ SG_ 2566618878 GnrtrClntFnCntrllrSttsRsnCd "Generator Coolant Fan Controller Status Reason Code: Provides the reason code describing the unique failure of this Generator Coolant Fan Motor system or component.If a detailed reason code is not used by the supporting application, or this reason co...";
CM_ SG_ 2566618878 GnrtrClntFnCntrllrCmmndStts "Generator Coolant Fan Controller Command Status: Indicates the source of the speed command to this Generator Coolant Fan system or component.00b is communicated when the controller is self-controlled (e.g. based on a temperature sensor).01b is commun...";
CM_ SG_ 2566618878 GeneratorCoolantFanMotorSpeed "Generator Coolant Fan Motor Speed: Motor Speed of the Generator Coolant Fan.";
CM_ SG_ 2566618878 GnrtrClntFnCntrlTmprtr "Generator Coolant Fan Control Temperature: A temperature measured and reported by the device.  It may be used for direct or remote (e.g. by another controller) control of the pump.  For example, this may be the temperature of the fluid flowing throug...";
CM_ SG_ 2566618878 GeneratorCoolantFanPower "Generator Coolant Fan Power: Calculated electrical power consumed by the Generator Coolant Fan.";
CM_ SG_ 2566618878 GnrtrClntFnSrvIndtr "Generator Coolant Fan Service Indicator: Indicates that service is required for the Generator Coolant Fan system or component.  An active indication may convey a need for component replacement or periodic service.  The Generator Coolant Fan Motor Con...";
CM_ SG_ 2566618878 GnrtrClntFnOprtngStts "Generator Coolant Fan Operating Status: Indicates the operating status of the Generator Coolant Fan system or component.  This parameter is used to inform other devices that this system or component is no longer performing to its operational capacity...";
CM_ BO_ 2566619134 "Well Stimulation Pump System Filter Information";
CM_ SG_ 2566619134 WllStmltnPmpOlFltrDffrntlPrssr "Well Stimulation Pump Oil Filter Differential Pressure: Change in pump gear box oil pressure, measured across the filter, due to the filter and any accumulation of solid or semisolid material on or in the filter. The differential pressure is measured...";
CM_ SG_ 2566619134 WllStmltnPmpOlFltrBpssSwthStts "Well Stimulation Pump Oil Filter Bypass Switch Status: Displays Pump Oil Filter Switch Status00b = Not bypassing01b = Bypassing10b = Error11b = Not available";
CM_ SG_ 2566619134 WllStmltnPmpGrBxOtltOlPrssr "Well Stimulation Pump Gear Box Outlet Oil Pressure: Pump Oil pressure (gage) measured just downstream of oil filter.";
CM_ BO_ 2566619390 "PTO Governor Configuration";
CM_ SG_ 2566619390 PrprgrmmdPTOGvrnrStSpd1 "Preprogrammed PTO Governor Set Speed 1: This speed corresponds to the PTO governed speed when PTO Governor State (SPN 976) is equal to Preprogrammed PTO Governor Set Speed 1 (01010b).";
CM_ SG_ 2566619390 PrprgrmmdPTOGvrnrStSpd2 "Preprogrammed PTO Governor Set Speed 2: This speed corresponds to the PTO governed speed when PTO Governor State (SPN 976) is equal to Preprogrammed PTO Governor Set Speed 2 (01011b).";
CM_ SG_ 2566619390 PrprgrmmdPTOGvrnrStSpd3 "Preprogrammed PTO Governor Set Speed 3: This speed corresponds to the PTO governed speed when PTO Governor State (SPN 976) is equal to Preprogrammed PTO Governor Set Speed 3 (01100b).";
CM_ SG_ 2566619390 PrprgrmmdPTOGvrnrStSpd4 "Preprogrammed PTO Governor Set Speed 4: This speed corresponds to the PTO governed speed when PTO Governor State (SPN 976) is equal to Preprogrammed PTO Governor Set Speed 4 (01101b).";
CM_ SG_ 2566619390 PrprgrmmdPTOGvrnrStSpd5 "Preprogrammed PTO Governor Set Speed 5: This speed corresponds to the PTO governed speed when PTO Governor State (SPN 976) is equal to Preprogrammed PTO Governor Set Speed 5 (01110b).";
CM_ SG_ 2566619390 PrprgrmmdPTOGvrnrStSpd6 "Preprogrammed PTO Governor Set Speed 6: This speed corresponds to the PTO governed speed when PTO Governor State (SPN 976) is equal to Preprogrammed PTO Governor Set Speed 6 (01111b).";
CM_ SG_ 2566619390 PrprgrmmdPTOGvrnrStSpd7 "Preprogrammed PTO Governor Set Speed 7: This speed corresponds to the PTO governed speed when PTO Governor State (SPN 976) is equal to Preprogrammed PTO Governor Set Speed 7 (10000b).";
CM_ SG_ 2566619390 PrprgrmmdPTOGvrnrStSpd8 "Preprogrammed PTO Governor Set Speed 8: This speed corresponds to the PTO governed speed when PTO Governor State (SPN 976) is equal to Preprogrammed PTO Governor Set Speed 8 (10001b).";
CM_ SG_ 2566619390 MinimumPTOGovernorSetSpeed "Minimum PTO Governor Set Speed: The minimum allowed engine speed (user programmable) in which preprogrammed PTO governor set speeds 1-8 can be set.";
CM_ SG_ 2566619390 MaximumPTOGovernorSetSpeed "Maximum PTO Governor Set Speed: The maximum allowed engine speed (user programmable) in which preprogrammed PTO governor set speeds 1-8 can be set.";
CM_ SG_ 2566619390 PTOGvrnrAlrtrOvrrdMxmmSpd "PTO Governor Accelerator Override Maximum Speed: The maximum engine speed allowed while accelerator pedal is overriding the PTO governor.";
CM_ BO_ 2566619646 "On Board Programming 2";
CM_ SG_ 2566619646 OnBrdPrgrmmngInttECUAddrss "On Board Programming Initiate ECU Address: Source address of target device for which on board programming is to be initiated. Source addresses 254 and 255 are not valid.";
CM_ SG_ 2566619646 OnBrdPrgrmmngInttRqst "On Board Programming Initiate Request: Signal indicating that programming should be initiated. Could come from operator controls or target device. Actual initiation may be subject to, or delayed by, operating conditions or interlocks.00b = On board p...";
CM_ SG_ 2566619646 OnBrdPrgrmmngInttInht "On Board Programming Initiate Inhibit: Indicates that programming is inhibited. Signal should be used by the target to prevent being programmed, or by the operator to decline/cancel programming.00b = Programming is not inhibited01b = Programming is i...";
CM_ BO_ 2566620670 "Engine Idle Management Information";
CM_ SG_ 2566620670 EngineIdleManagementStatus "Engine Idle Management Status: Indicates the current state or mode of operation by the engine idle manangement system.0000b = Off0001b = Locked0010b = Disabled0011b = Activation conditions not met (Not able to begin or continue due to current engine ...";
CM_ SG_ 2566620670 IdlMngmntPndngEvntTmRmnng "Idle Management Pending Event Time Remaining: Used to indicate the time remaining before the engine will start-up or shutdown as determined by the idle management controller. The time remaining can be used to trigger additional alarms, lamps & displa...";
CM_ SG_ 2566620670 EngnIdlMngmntEngnRstrtRsn "Engine Idle Management Engine Restart Reason: Used to indicate the condition requesting the engine to restart when the idle management system is active.0000b = Operator input request0001b = Low engine coolant temperature0010b = Low SLI battery voltag...";
CM_ SG_ 2566620670 EngnIdlMngmntEngnShtdwnRsn "Engine Idle Management Engine Shutdown Reason: Used to indicate the condition requesting the engine to shutdown when the idle management system is active.When multiple reasons are applicable, it is suggested that precedence be given to states which a...";
CM_ BO_ 2566621438 "Marine Control Information 3";
CM_ SG_ 2566621438 StationThrottlePositionMatch "Station Throttle Position Match: Indicates whether the throttle position at the currently selected station and the throttle lever position at the station where the transfer is occuring is within the correct range to allow the transfer to occur.00b = ...";
CM_ SG_ 2566621438 StationGearPositionMatch "Station Gear Position Match: Indicates whether the gear position at the currently selected station is in neutral and the gear lever position at the station where the transfer is occuring is in neutral in order to allow the transfer to occur.00b = Neu...";
CM_ SG_ 2566621438 OprtrSttnAtvBttnStts "Operator Station Active Button Status: The button used to request a station to become the active station when another station is currently in control.00b = Button not pressed01b = Button pressed10b = Error11b = Not Available";
CM_ SG_ 2566621438 TrollingModeButtonStatus "Trolling Mode Button Status: The button used to change the current type of trolling mode that is selected.00b = Button not pressed01b = Button pressed10b = Error11b = Not Available";
CM_ SG_ 2566621438 EngnThrttlLvrSnhrnztnBttnStts "Engine Throttle Lever Synchronization Button Status: The button that is used to enable or disable syncronization of the engine throttles. When synchronization mode is activated, an operator uses one throttle lever to control the speed of multiple eng...";
CM_ SG_ 2566621438 GearLockoutButtonStatus "Gear Lockout Button Status: This button is used to prevent the transmissions from being shifted into gear. When the button is pressed, the transmissions will be locked in neutral.00b = Button not pressed01b = Button pressed10b = Error11b = Not Availa...";
CM_ SG_ 2566621438 SlowVesselModeButtonStatus "Slow Vessel Mode Button Status: Reports when the slow vessel mode button has been pressed.00b = Button not pressed01b = Button pressed10b = Error11b = Not Available";
CM_ SG_ 2566621438 OperatorStationActiveLampStatus "Operator Station Active Lamp Status: Reports when the operator station active lamp is illuminated.00b = Off01b = On10b = Error11b = Not Available";
CM_ SG_ 2566621438 TrollingModeLampStatus "Trolling Mode Lamp Status: Reports when the trolling mode lamp is illuminated.00b = Off01b = On10b = Error11b = Not Available";
CM_ SG_ 2566621438 EngnThrttlLvrSnhrnztnLmpStts "Engine Throttle Lever Synchronization Lamp Status: Reports when the throttle lever synchronization lamp is illuminated. When synchronization mode is activated, an operator uses one throttle lever to control the speed of multiple engines.00b = Off01b ...";
CM_ SG_ 2566621438 GearLockoutLampStatus "Gear Lockout Lamp Status: Reports when the gear lockout lamp is illuminated.00b = Off01b = On10b = Error11b = Not Available";
CM_ SG_ 2566621438 SlowVesselModeLampStatus "Slow Vessel Mode Lamp Status: Reports when the slow vessel mode lamp is illuminated.00b = Off01b = On10b = Error11b = Not Available";
CM_ SG_ 2566621438 MarineHeavySeaModeEnable "Marine Heavy Sea Mode Enable: Command signal used to indicate that the Marine heavy sea mode is disabled or enabled. Heavy sea mode puts the engine in a control mode to manage heavy sea/ rough water load fluctuations.00b = Marine heavy sea mode is di...";
CM_ BO_ 2566621694 "Engine Fluid Level/Pressure 13";
CM_ SG_ 2566621694 EngineOilPressure2 "Engine Oil Pressure 2: Gage pressure of oil in engine lubrication system as provided by oil pump - second instance.";
CM_ BO_ 2365295358 "High Voltage Energy Storage System Data 11";
CM_ SG_ 2365295358 HVESSBsVltgNgtvtChsssGrndVltg "HVESS Bus Voltage Negative to Chassis Ground Voltage: Voltage difference between the most negative terminal of the HVES battery and chassis measured on the hybrid system bus side (not the battery side) of any HVES contained output contactor.  This vo...";
CM_ SG_ 2365295358 HVESSVltgLvlNgtvtChsssGrndVltg "HVESS Voltage Level Negative to Chassis Ground Voltage: Voltage difference between the most negative terminal of the HVES battery and chassis measured at the battery side of any HVES contained output contactor.  This voltage may be used for system le...";
CM_ BO_ 2566622206 "Economy Mode Inactive Hours";
CM_ SG_ 2566622206 EconomyModeTotalHoursInactive "Economy Mode Total Hours Inactive: Total accumulated operating time while economy mode is installed but not in use.";
CM_ SG_ 2566622206 EconomyModeTripHoursInactive "Economy Mode Trip Hours Inactive: Trip operating time accumulated while economy mode is installed but not in use, since last trip reset.";
CM_ BO_ 2566622462 "Economy Mode Estimated Instantaneous Fuel Savings Rate";
CM_ SG_ 2566622462 EnmMdEstmtdInstntnsFlSvngsRt "Economy Mode Estimated Instantaneous Fuel Savings Rate: Estimated instantaneous fuel savings rate while operating in economy mode.  This is in comparison to operating in a non-economy mode.";
CM_ SG_ 2566622462 EMdEsttdIsttsFSvsRtPt "Economy Mode Estimated Instantaneous Fuel Savings Rate Percent: Estimated instantaneous fuel savings rate percentage while operating in economy mode. This value is calculated by dividing Economy Mode Estimated Instantaneous Fuel Savings Percent (SPN ...";
CM_ BO_ 2566622718 "Economy Mode Active Hours";
CM_ SG_ 2566622718 EconomyModeTotalHoursActive "Economy Mode Total Hours Active: Total accumulated operating time in economy mode over the lifetime of the application.";
CM_ SG_ 2566622718 EconomyModeTripHoursActive "Economy Mode Trip Hours Active: Total accumulated operating time in economy mode since the last trip reset.";
CM_ BO_ 2566622974 "Economy Mode Fuel Used";
CM_ SG_ 2566622974 EconomyModeTotalFuelUsed "Economy Mode Total Fuel Used: Total volume of fuel used during economy mode operation over the lifetime of the application.";
CM_ SG_ 2566622974 EconomyModeTripFuelUsed "Economy Mode Trip Fuel Used: Total volume of fuel used during all or part of a journey while operating in economy mode, since the last trip reset.";
CM_ BO_ 2566623230 "Economy Mode Estimated Fuel Savings";
CM_ SG_ 2566623230 EnmMdTtlEstmtdFlSvd "Economy Mode Total Estimated Fuel Saved: Total volume of estimated fuel saved during economy mode of operation over the lifetime of the application. This is in comparison to operating in a non-economy mode.";
CM_ SG_ 2566623230 EnmMdTrpEstmtdFlSvd "Economy Mode Trip Estimated Fuel Saved: Total volume of estimated fuel saved during all or part of a journey while operating in economy mode, since the last trip reset. This is in comparison to operating in a non-economy mode.";
CM_ BO_ 2552823550 "Motor/Generator 1 Inverter Rate Limits Request 1";
CM_ SG_ 2552823550 MtrGnrtr1InvrtrRtLmtsRqst1CRC "Motor/Generator 1 Inverter Rate Limits Request 1 CRC: The CRC is defined as follows: • Length: 8 bits • Polynomial: x^8+x^5+x^3+x^2+x+1 • Initial Value: FFh • Input Data Reflection: Not reflected • Result Data Reflection: Not reflected • XOR value: F...";
CM_ SG_ 2552823550 MtrGnrtr1InvrtrRtLmtsRqst1Cntr "Motor/Generator 1 Inverter Rate Limits Request 1 Counter: The message counter is used to detect situations where the transmitting ECU malfunction repeats the same frame all the time. The receiver of the information may use the counter parameter to de...";
CM_ SG_ 2552823550 MtGt1IvtRtLtsRqstAstSpdRtLt "Motor/Generator 1 Inverter Rate Limits Request Absolute Speed Rate Limit: The maximum rate of change for the absolute motor speed  (i.e. |d(speed)|/dt) in all control modes. Refer to SPN 10171 [Reference Speed] to convert %/sec to RPM/sec. Request a ...";
CM_ SG_ 2552823550 MtGt1IvtRtLtsRqstAstTqRtLt "Motor/Generator 1 Inverter Rate Limits Request Absolute Torque Rate Limit: The maximum rate of change for the absolute motor torque (i.e. |d(torque)|/dt) in all control modes. Refer to SPN 10170 [Reference Torque] to convert %/sec to Nm/sec. Request ...";
CM_ BO_ 2552889086 "Motor/Generator 2 Inverter Rate Limits Request 1";
CM_ SG_ 2552889086 MtrGnrtr2InvrtrRtLmtsRqst1CRC "Motor/Generator 2 Inverter Rate Limits Request 1 CRC: The CRC is defined as follows: • Length: 8 bits • Polynomial: x^8+x^5+x^3+x^2+x+1 • Initial Value: FFh • Input Data Reflection: Not reflected • Result Data Reflection: Not reflected • XOR value: F...";
CM_ SG_ 2552889086 MtrGnrtr2InvrtrRtLmtsRqst1Cntr "Motor/Generator 2 Inverter Rate Limits Request 1 Counter: The message counter is used to detect situations where the transmitting ECU malfunction repeats the same frame all the time. The receiver of the information may use the counter parameter to de...";
CM_ SG_ 2552889086 MtGt2IvtRtLtsRqstAstSpdRtLt "Motor/Generator 2 Inverter Rate Limits Request Absolute Speed Rate Limit: The maximum rate of change for the absolute motor speed (i.e. |d(speed)|/dt) in all control modes. Refer to SPN 10237 [Reference Speed] to convert %/sec to RPM/sec. Request a v...";
CM_ SG_ 2552889086 MtGt2IvtRtLtsRqstAstTqRtLt "Motor/Generator 2 Inverter Rate Limits Request Absolute Torque Rate Limit: The maximum rate of change for the absolute motor torque (i.e. |d(torque)|/dt) in all control modes. Refer to SPN 10236 [Reference Torque] to convert %/sec to Nm/sec. Request ...";
CM_ BO_ 2351628030 "High Voltage Energy Storage Pack 1 Control 1";
CM_ SG_ 2351628030 HVESP1HghVltgBsCnntCmmnd "HVESP1 High-Voltage Bus Connect Command: Command to connect this High Voltage Energy Storage Pack instance to the high-voltage bus.  The emergency contactor closure request may be used in situations where one or more faults in the hybrid powertrain p...";
CM_ SG_ 2351628030 HVESP1PowerDownCommand "HVESP1 Power-Down Command: Command to shut down this High Voltage Energy Storage Pack instance.  A normal power-down may involve steps that take some period of time (tests, writing of data, etc.).  However, an emergency power-down should shut down th...";
CM_ SG_ 2351628030 HVESP1HghVltgBsAtvIsltnTstCmmnd "HVESP1 High-Voltage Bus Active Isolation Test Command: Command for this High Voltage Energy Storage Pack instance to perform an active electrical isolation test on the high voltage bus.An active isolation test might use a generated signal (e.g. an in...";
CM_ SG_ 2351628030 HVESP1HVtBsPssvIstTstCd "HVESP1 High-Voltage Bus Passive Isolation Test Command: Command for this High Voltage Energy Storage Pack instance to perform a passive electrical isolation test on the high voltage bus.A passive isolation test uses additional circuitry (e.g. a high ...";
CM_ SG_ 2351628030 HVESP1CellBalancingCommand "HVESP1 Cell Balancing Command: Command for this High Voltage Energy Storage Pack instance to perform cell balancing.This parameter is for one of multiple packs in an HVESS.  If there is only one pack in the system, the HVESS parameters should be used...";
CM_ SG_ 2351628030 HVESP1EnlIntrnlChrgrCmmnd "HVESP1 Enable Internal Charger Command: When the HVES has an internal charger this parameter will enable it.   External chargers may use the External Energy Source Connection Demand (SPN 7890) and related SPs.This parameter is for one of multiple pac...";
CM_ SG_ 2351628030 HVESP1OperationConsent "HVESP1 Operation Consent: This parameter provides an indication to this High Voltage Energy Storage Pack instance that an external device is ready for this HVES instance to proceed with normal operation.  In applications which support this parameter,...";
CM_ SG_ 2351628030 HVESP1HVtBsHSdRsstCtRqst "HVESP1 High-Voltage Bus High Side Resistor Connect Request: This parameter is used to request connection of this HVES instance High-Voltage bus high side resistor in order to perform an isolation test.  See also SPN 11037 (HVESP1 High-Voltage Bus Low...";
CM_ SG_ 2351628030 HVESP1HVtBsLwSdRsstCtRqst "HVESP1 High-Voltage Bus Low Side Resistor Connect Request: This parameter is used to request connection of this HVES instance High-Voltage bus low side resistor in order to perform an isolation test.  See also SPN 11036  (HVESP1 High-Voltage Bus High...";
CM_ BO_ 2351693566 "High Voltage Energy Storage Pack 2 Control 1";
CM_ SG_ 2351693566 HVESP2HghVltgBsCnntCmmnd "HVESP2 High-Voltage Bus Connect Command: Command to connect this High Voltage Energy Storage Pack instance to the high-voltage bus.  The emergency contactor closure request may be used in situations where one or more faults in the hybrid powertrain p...";
CM_ SG_ 2351693566 HVESP2PowerDownCommand "HVESP2 Power-Down Command: Command to shut down this High Voltage Energy Storage Pack instance.  A normal power-down may involve steps that take some period of time (tests, writing of data, etc.).  However, an emergency power-down should shut down th...";
CM_ SG_ 2351693566 HVESP2HghVltgBsAtvIsltnTstCmmnd "HVESP2 High-Voltage Bus Active Isolation Test Command: Command for this High Voltage Energy Storage Pack instance to perform an active electrical isolation test on the high voltage bus.An active isolation test might use a generated signal (e.g. an in...";
CM_ SG_ 2351693566 HVESP2HVtBsPssvIstTstCd "HVESP2 High-Voltage Bus Passive Isolation Test Command: Command for this High Voltage Energy Storage Pack instance to perform a passive electrical isolation test on the high voltage bus.A passive isolation test uses additional circuitry (e.g. a high ...";
CM_ SG_ 2351693566 HVESP2CellBalancingCommand "HVESP2 Cell Balancing Command: Command for this High Voltage Energy Storage Pack instance to perform cell balancing.This parameter is for one of multiple packs in an HVESS.  If there is only one pack in the system, the HVESS parameters should be used...";
CM_ SG_ 2351693566 HVESP2EnlIntrnlChrgrCmmnd "HVESP2 Enable Internal Charger Command: When the HVES has an internal charger this parameter will enable it.   External chargers may use the External Energy Source Connection Demand (SPN 7890) and related SPs.This parameter is for one of multiple pac...";
CM_ SG_ 2351693566 HVESP2OperationConsent "HVESP2 Operation Consent: This parameter provides an indication to this High Voltage Energy Storage Pack instance that an external device is ready for this HVES instance to proceed with normal operation.  In applications which support this parameter,...";
CM_ SG_ 2351693566 HVESP2HVtBsHSdRsstCtRqst "HVESP2 High-Voltage Bus High Side Resistor Connect Request: This parameter is used to request connection of this HVES instance High-Voltage bus high side resistor in order to perform an isolation test.  See also SPN 11153  (HVESP2 High-Voltage Bus Lo...";
CM_ SG_ 2351693566 HVESP2HVtBsLwSdRsstCtRqst "HVESP2 High-Voltage Bus Low Side Resistor Connect Request: This parameter is used to request connection of this HVES instance High-Voltage bus low side resistor in order to perform an isolation test.  See also SPN 11152  (HVESP2 High-Voltage Bus High...";
CM_ BO_ 2351759102 "High Voltage Energy Storage Pack 3 Control 1";
CM_ SG_ 2351759102 HVESP3HghVltgBsCnntCmmnd "HVESP3 High-Voltage Bus Connect Command: Command to connect this High Voltage Energy Storage Pack instance to the high-voltage bus.  The emergency contactor closure request may be used in situations where one or more faults in the hybrid powertrain p...";
CM_ SG_ 2351759102 HVESP3PowerDownCommand "HVESP3 Power-Down Command: Command to shut down this High Voltage Energy Storage Pack instance.  A normal power-down may involve steps that take some period of time (tests, writing of data, etc.).  However, an emergency power-down should shut down th...";
CM_ SG_ 2351759102 HVESP3HghVltgBsAtvIsltnTstCmmnd "HVESP3 High-Voltage Bus Active Isolation Test Command: Command for this High Voltage Energy Storage Pack instance to perform an active electrical isolation test on the high voltage bus.An active isolation test might use a generated signal (e.g. an in...";
CM_ SG_ 2351759102 HVESP3HVtBsPssvIstTstCd "HVESP3 High-Voltage Bus Passive Isolation Test Command: Command for this High Voltage Energy Storage Pack instance to perform a passive electrical isolation test on the high voltage bus.A passive isolation test uses additional circuitry (e.g. a high ...";
CM_ SG_ 2351759102 HVESP3CellBalancingCommand "HVESP3 Cell Balancing Command: Command for this High Voltage Energy Storage Pack instance to perform cell balancing.This parameter is for one of multiple packs in an HVESS.  If there is only one pack in the system, the HVESS parameters should be used...";
CM_ SG_ 2351759102 HVESP3EnlIntrnlChrgrCmmnd "HVESP3 Enable Internal Charger Command: When the HVES has an internal charger this parameter will enable it.   External chargers may use the External Energy Source Connection Demand (SPN 7890) and related SPs.This parameter is for one of multiple pac...";
CM_ SG_ 2351759102 HVESP3OperationConsent "HVESP3 Operation Consent: This parameter provides an indication to this High Voltage Energy Storage Pack instance that an external device is ready for this HVES instance to proceed with normal operation.  In applications which support this parameter,...";
CM_ SG_ 2351759102 HVESP3HVtBsHSdRsstCtRqst "HVESP3 High-Voltage Bus High Side Resistor Connect Request: This parameter is used to request connection of this HVES instance High-Voltage bus high side resistor in order to perform an isolation test.  See also SPN 11269  (HVESP3 High-Voltage Bus Lo...";
CM_ SG_ 2351759102 HVESP3HVtBsLwSdRsstCtRqst "HVESP3 High-Voltage Bus Low Side Resistor Connect Request: This parameter is used to request connection of this HVES instance High-Voltage bus low side resistor in order to perform an isolation test.  See also SPN 11268  (HVESP3 High-Voltage Bus High...";
CM_ BO_ 2351824638 "High Voltage Energy Storage Pack 4 Control 1";
CM_ SG_ 2351824638 HVESP4HghVltgBsCnntCmmnd "HVESP4 High-Voltage Bus Connect Command: Command to connect this High Voltage Energy Storage Pack instance to the high-voltage bus.  The emergency contactor closure request may be used in situations where one or more faults in the hybrid powertrain p...";
CM_ SG_ 2351824638 HVESP4PowerDownCommand "HVESP4 Power-Down Command: Command to shut down this High Voltage Energy Storage Pack instance.  A normal power-down may involve steps that take some period of time (tests, writing of data, etc.).  However, an emergency power-down should shut down th...";
CM_ SG_ 2351824638 HVESP4HghVltgBsAtvIsltnTstCmmnd "HVESP4 High-Voltage Bus Active Isolation Test Command: Command for this High Voltage Energy Storage Pack instance to perform an active electrical isolation test on the high voltage bus.An active isolation test might use a generated signal (e.g. an in...";
CM_ SG_ 2351824638 HVESP4HVtBsPssvIstTstCd "HVESP4 High-Voltage Bus Passive Isolation Test Command: Command for this High Voltage Energy Storage Pack instance to perform a passive electrical isolation test on the high voltage bus.A passive isolation test uses additional circuitry (e.g. a high ...";
CM_ SG_ 2351824638 HVESP4CellBalancingCommand "HVESP4 Cell Balancing Command: Command for this High Voltage Energy Storage Pack instance to perform cell balancing.This parameter is for one of multiple packs in an HVESS.  If there is only one pack in the system, the HVESS parameters should be used...";
CM_ SG_ 2351824638 HVESP4EnlIntrnlChrgrCmmnd "HVESP4 Enable Internal Charger Command: When the HVES has an internal charger this parameter will enable it.   External chargers may use the External Energy Source Connection Demand (SPN 7890) and related SPs.This parameter is for one of multiple pac...";
CM_ SG_ 2351824638 HVESP4OperationConsent "HVESP4 Operation Consent: This parameter provides an indication to this High Voltage Energy Storage Pack instance that an external device is ready for this HVES instance to proceed with normal operation.  In applications which support this parameter,...";
CM_ SG_ 2351824638 HVESP4HVtBsHSdRsstCtRqst "HVESP4 High-Voltage Bus High Side Resistor Connect Request: This parameter is used to request connection of this HVES instance High-Voltage bus high side resistor in order to perform an isolation test.  See also SPN 11385  (HVESP4 High-Voltage Bus Lo...";
CM_ SG_ 2351824638 HVESP4HVtBsLwSdRsstCtRqst "HVESP4 High-Voltage Bus Low Side Resistor Connect Request: This parameter is used to request connection of this HVES instance High-Voltage bus low side resistor in order to perform an isolation test.  See also SPN 11384  (HVESP4 High-Voltage Bus High...";
CM_ BO_ 2351890174 "High Voltage Energy Storage Pack 5 Control 1";
CM_ SG_ 2351890174 HVESP5HghVltgBsCnntCmmnd "HVESP5 High-Voltage Bus Connect Command: Command to connect this High Voltage Energy Storage Pack instance to the high-voltage bus.  The emergency contactor closure request may be used in situations where one or more faults in the hybrid powertrain p...";
CM_ SG_ 2351890174 HVESP5PowerDownCommand "HVESP5 Power-Down Command: Command to shut down this High Voltage Energy Storage Pack instance.  A normal power-down may involve steps that take some period of time (tests, writing of data, etc.).  However, an emergency power-down should shut down th...";
CM_ SG_ 2351890174 HVESP5HghVltgBsAtvIsltnTstCmmnd "HVESP5 High-Voltage Bus Active Isolation Test Command: Command for this High Voltage Energy Storage Pack instance to perform an active electrical isolation test on the high voltage bus.An active isolation test might use a generated signal (e.g. an in...";
CM_ SG_ 2351890174 HVESP5HVtBsPssvIstTstCd "HVESP5 High-Voltage Bus Passive Isolation Test Command: Command for this High Voltage Energy Storage Pack instance to perform a passive electrical isolation test on the high voltage bus.A passive isolation test uses additional circuitry (e.g. a high ...";
CM_ SG_ 2351890174 HVESP5CellBalancingCommand "HVESP5 Cell Balancing Command: Command for this High Voltage Energy Storage Pack instance to perform cell balancing.This parameter is for one of multiple packs in an HVESS.  If there is only one pack in the system, the HVESS parameters should be used...";
CM_ SG_ 2351890174 HVESP5EnlIntrnlChrgrCmmnd "HVESP5 Enable Internal Charger Command: When the HVES has an internal charger this parameter will enable it.   External chargers may use the External Energy Source Connection Demand (SPN 7890) and related SPs.This parameter is for one of multiple pac...";
CM_ SG_ 2351890174 HVESP5OperationConsent "HVESP5 Operation Consent: This parameter provides an indication to this High Voltage Energy Storage Pack instance that an external device is ready for this HVES instance to proceed with normal operation.  In applications which support this parameter,...";
CM_ SG_ 2351890174 HVESP5HVtBsHSdRsstCtRqst "HVESP5 High-Voltage Bus High Side Resistor Connect Request: This parameter is used to request connection of this HVES instance High-Voltage bus high side resistor in order to perform an isolation test.  See also SPN 11501  (HVESP5 High-Voltage Bus Lo...";
CM_ SG_ 2351890174 HVESP5HVtBsLwSdRsstCtRqst "HVESP5 High-Voltage Bus Low Side Resistor Connect Request: This parameter is used to request connection of this HVES instance High-Voltage bus low side resistor in order to perform an isolation test.  See also SPN 11500  (HVESP5 High-Voltage Bus High...";
CM_ BO_ 2351955710 "High Voltage Energy Storage Pack 6 Control 1";
CM_ SG_ 2351955710 HVESP6HghVltgBsCnntCmmnd "HVESP6 High-Voltage Bus Connect Command: Command to connect this High Voltage Energy Storage Pack instance to the high-voltage bus.  The emergency contactor closure request may be used in situations where one or more faults in the hybrid powertrain p...";
CM_ SG_ 2351955710 HVESP6PowerDownCommand "HVESP6 Power-Down Command: Command to shut down this High Voltage Energy Storage Pack instance.  A normal power-down may involve steps that take some period of time (tests, writing of data, etc.).  However, an emergency power-down should shut down th...";
CM_ SG_ 2351955710 HVESP6HghVltgBsAtvIsltnTstCmmnd "HVESP6 High-Voltage Bus Active Isolation Test Command: Command for this High Voltage Energy Storage Pack instance to perform an active electrical isolation test on the high voltage bus.An active isolation test might use a generated signal (e.g. an in...";
CM_ SG_ 2351955710 HVESP6HVtBsPssvIstTstCd "HVESP6 High-Voltage Bus Passive Isolation Test Command: Command for this High Voltage Energy Storage Pack instance to perform a passive electrical isolation test on the high voltage bus.A passive isolation test uses additional circuitry (e.g. a high ...";
CM_ SG_ 2351955710 HVESP6CellBalancingCommand "HVESP6 Cell Balancing Command: Command for this High Voltage Energy Storage Pack instance to perform cell balancing.This parameter is for one of multiple packs in an HVESS.  If there is only one pack in the system, the HVESS parameters should be used...";
CM_ SG_ 2351955710 HVESP6EnlIntrnlChrgrCmmnd "HVESP6 Enable Internal Charger Command: When the HVES has an internal charger this parameter will enable it.   External chargers may use the External Energy Source Connection Demand (SPN 7890) and related SPs.This parameter is for one of multiple pac...";
CM_ SG_ 2351955710 HVESP6OperationConsent "HVESP6 Operation Consent: This parameter provides an indication to this High Voltage Energy Storage Pack instance that an external device is ready for this HVES instance to proceed with normal operation.  In applications which support this parameter,...";
CM_ SG_ 2351955710 HVESP6HVtBsHSdRsstCtRqst "HVESP6 High-Voltage Bus High Side Resistor Connect Request: This parameter is used to request connection of this HVES instance High-Voltage bus high side resistor in order to perform an isolation test.  See also SPN 11617  (HVESP6 High-Voltage Bus Lo...";
CM_ SG_ 2351955710 HVESP6HVtBsLwSdRsstCtRqst "HVESP6 High-Voltage Bus Low Side Resistor Connect Request: This parameter is used to request connection of this HVES instance High-Voltage bus low side resistor in order to perform an isolation test.  See also SPN 11616  (HVESP6 High-Voltage Bus High...";
CM_ BO_ 2555641598 "EVSE 1 Control 1";
CM_ SG_ 2555641598 EVSE1ConnectorLockCommand "EVSE1 Connector Lock Command: Command to engage or disengage the locking mechanism fitted to this EVSE connector to the vehicle.The actual Lock state will be reported via SPN 12863 (EVSE1 Connector Lock State).0000b = Unlock Request0001b = Lock Reque...";
CM_ BO_ 2555707134 "Winch Information 3";
CM_ SG_ 2555707134 WinchPositionReset "Winch Position Reset: Command to reset or zero the Winch Motor Encoder Position (SPN 12309) and Winch Revolution Counter (SPN 12310). The Winch Lifetime Revolution Counter (SPN 12311) is not reset.00b = Reset not requested01b = Reset requested10b = R...";
CM_ BO_ 2354446078 "Air Suspension Control 8";
CM_ SG_ 2354446078 LiftAxle3PositionCommand "Lift Axle 3 Position Command: Signal to command the position/load condition of lift/tag axle 3. Numbering of lift/tag axles starts at front axle.00b = Lift axle position down / tag axle laden01b = Lift axle position up / tag axle unladen10b = Reserve...";
CM_ BO_ 2354511614 "Motor/Generator 2 Inverter Control 2";
CM_ SG_ 2354511614 MtrGnrtr2InvrtrCntrl2CRC "Motor/Generator 2 Inverter Control 2 CRC: The CRC is defined as follows:• Length: 8 bits• Polynomial: x^8+x^5+x^3+x^2+x+1• Initial Value: FFh• Input Data Reflection: Not reflected• Result Data Reflection: Not reflected• XOR value: FFhSAE makes no cla...";
CM_ SG_ 2354511614 MtrGnrtr2InvrtrCntrl2Cntr "Motor/Generator 2 Inverter Control 2 Counter: The message counter is used to detect situations where the transmitting ECU malfunction repeats the same frame all the time. The receiver of the information may use the counter parameter to detect this si...";
CM_ SG_ 2354511614 MtrGnrtr2InvrtrPIDCntrlAppllMd "Motor/Generator 2 Inverter PID Control Applicable Mode : Defines the Mode that the PID Gain parameters apply for this instance of the inverter.  See SPN 10233 [Control Setpoint Mode] for a definition of modes for control purposes.Applicable modes:000...";
CM_ SG_ 2354511614 MtGt2IvtPIDCtNzdDtG "Motor/Generator 2 Inverter PID Control Normalized Differential Gain: A PID controller can be parametrized by factors Kp, Ki and Kd. This parameter defines the normalized differential gain (Kdn) for control applications in this inverter instance. The ...";
CM_ SG_ 2354511614 MtGt2IvtPIDCtNzdItG "Motor/Generator 2 Inverter PID Control Normalized Integral Gain: A PID controller can be parametrized by factors Kp, Ki and Kd. This parameter defines the normalized integral gain (Kin) for control applications in this inverter instance. The normaliz...";
CM_ SG_ 2354511614 MtGt2IvtPIDCtNzdPptG "Motor/Generator 2 Inverter PID Control Normalized Proportional Gain: A PID controller can be parametrized by factors Kp, Ki and Kd. This parameter defines the normalized proportional gain (Kpn) for control applications in this inverter instance. The ...";
CM_ SG_ 2354511614 MtGt2IvtPIDCtFdFwdTq "Motor/Generator 2 Inverter PID Control Feed-Forward Torque: A PID controller can have a Feed-Forward Torque added to its output. This parameter defines the Feed-Forward Torque Setpoint for control applications in this inverter instance. The Setpoint ...";
CM_ BO_ 2354577150 "Motor/Generator 1 Inverter Control 2";
CM_ SG_ 2354577150 MtrGnrtr1InvrtrCntrl2CRC "Motor/Generator 1 Inverter Control 2 CRC: The CRC is defined as follows:• Length: 8 bits• Polynomial: x^8+x^5+x^3+x^2+x+1• Initial Value: FFh• Input Data Reflection: Not reflected• Result Data Reflection: Not reflected• XOR value: FFhSAE makes no cla...";
CM_ SG_ 2354577150 MtrGnrtr1InvrtrCntrl2Cntr "Motor/Generator 1 Inverter Control 2 Counter: The message counter is used to detect situations where the transmitting ECU malfunction repeats the same frame all the time. The receiver of the information may use the counter parameter to detect this si...";
CM_ SG_ 2354577150 MtrGnrtr1InvrtrPIDCntrlAppllMd "Motor/Generator 1 Inverter PID Control Applicable Mode : Defines the Mode that the PID Gain parameters apply for this instance of the inverter.  See SPN 10167 [Control Setpoint Mode] for a definition of modes for control purposes.Applicable modes:000...";
CM_ SG_ 2354577150 MtGt1IvtPIDCtNzdDtG "Motor/Generator 1 Inverter PID Control Normalized Differential Gain: A PID controller can be parametrized by factors Kp, Ki and Kd. This parameter defines the normalized differential gain (Kdn) for control applications in this inverter instance. The ...";
CM_ SG_ 2354577150 MtGt1IvtPIDCtNzdItG "Motor/Generator 1 Inverter PID Control Normalized Integral Gain: A PID controller can be parametrized by factors Kp, Ki and Kd. This parameter defines the normalized integral gain (Kin) for control applications in this inverter instance. The normaliz...";
CM_ SG_ 2354577150 MtGt1IvtPIDCtNzdPptG "Motor/Generator 1 Inverter PID Control Normalized Proportional Gain: A PID controller can be parametrized by factors Kp, Ki and Kd. This parameter defines the normalized proportional gain (Kpn) for control applications in this inverter instance. The ...";
CM_ SG_ 2354577150 MtGt1IvtPIDCtFdFwdTq "Motor/Generator 1 Inverter PID Control Feed-Forward Torque: A PID controller can have a Feed-Forward Torque added to its output. This parameter defines the Feed-Forward Torque Setpoint for control applications in this inverter instance. The Setpoint ...";
CM_ BO_ 2488860414 "Hoist Command Information";
CM_ SG_ 2488860414 HoistCommand "Hoist Command: Hoist operation being requested to the control that directly controls the hoist used for a dump body.  The sign of the value indicates mode of operation (raise or lower) and the magnitude of the value indicates the speed as a percentag...";
CM_ SG_ 2488860414 HoistDetentStatus "Hoist Detent Status: Indicates the detent status for the hoist command used for a dump body.00b = Not in the Detent01b = In the Detent10b = Error Indicator11b = Not Available";
CM_ BO_ 2556034814 "Motor/Generator 2 Inverter Isolation Integrity Request";
CM_ SG_ 2556034814 MtGt2IvtHVtBsAtvIstTstCd "Motor/Generator 2 Inverter High-Voltage Bus Active Isolation Test Command: Command for the inverter to perform an active electrical isolation test on the high voltage bus.An active isolation test might use a generated signal (e.g. an injected AC sign...";
CM_ SG_ 2556034814 MtGt2IvtHVtBsPssvIstTstCd "Motor/Generator 2 Inverter High-Voltage Bus Passive Isolation Test Command: Command for the inverter to perform a passive electrical isolation test on the high voltage bus.A passive isolation test uses additional circuitry (e.g. a high impedance netw...";
CM_ SG_ 2556034814 MtGt2IvtHVtBsHSdRsstCtRqst "Motor/Generator 2 Inverter High-Voltage Bus High Side Resistor Connect Request: This parameter is used to request connection of the inverter High-Voltage bus high side resistor in order to perform an isolation test.00b = Connection not Requested01b =...";
CM_ SG_ 2556034814 MtGt2IvtHVtBsLwSdRsstCtRqst "Motor/Generator 2 Inverter High-Voltage Bus Low Side Resistor Connect Request: This parameter is used to request connection of the inverter High-Voltage bus low side resistor in order to perform an isolation test.00b = Connection not Requested01b = C...";
CM_ BO_ 2556100350 "Motor/Generator 1 Inverter Isolation Integrity Request";
CM_ SG_ 2556100350 MtGt1IvtHVtBsAtvIstTstCd "Motor/Generator 1 Inverter High-Voltage Bus Active Isolation Test Command: Command for the inverter to perform an active electrical isolation test on the high voltage bus.An active isolation test might use a generated signal (e.g. an injected AC sign...";
CM_ SG_ 2556100350 MtGt1IvtHVtBsPssvIstTstCd "Motor/Generator 1 Inverter High-Voltage Bus Passive Isolation Test Command: Command for the inverter to perform a passive electrical isolation test on the high voltage bus.A passive isolation test uses additional circuitry (e.g. a high impedance netw...";
CM_ SG_ 2556100350 MtGt1IvtHVtBsHSdRsstCtRqst "Motor/Generator 1 Inverter High-Voltage Bus High Side Resistor Connect Request: This parameter is used to request connection of the inverter High-Voltage bus high side resistor in order to perform an isolation test. 00b = Connection not Requested01b ...";
CM_ SG_ 2556100350 MtGt1IvtHVtBsLwSdRsstCtRqst "Motor/Generator 1 Inverter High-Voltage Bus Low Side Resistor Connect Request: This parameter is used to request connection of the inverter High-Voltage bus low side resistor in order to perform an isolation test.  00b = Connection not Requested01b =...";
CM_ BO_ 2565966846 "Motor/Generator 1 Inverter Status 2";
CM_ SG_ 2565966846 MtrGnrtr1InvrtrStts2CRC "Motor/Generator 1 Inverter Status 2 CRC: The CRC is defined as follows: • Length: 8 bits • Polynomial: x^8+x^5+x^3+x^2+x+1 • Initial Value: FFh • Input Data Reflection: Not reflected • Result Data Reflection: Not reflected • XOR value: FFhSAE makes n...";
CM_ SG_ 2565966846 MtrGnrtr1InvrtrStts2Cntr "Motor/Generator 1 Inverter Status 2 Counter: The message counter is used to detect situations where the transmitting ECU malfunction repeats the same frame all the time. The receiver of the information may use the counter parameter to detect this sit...";
CM_ SG_ 2565966846 MtrGnrtr1AvllMxmmTrq "Motor/Generator 1 Available Maximum Torque: This is an estimate of the maximum available motor torque including active deratings at the present motor speed.  This refers to the motor rotor output and excludes any gearbox that may be attached to the m...";
CM_ SG_ 2565966846 MtrGnrtr1AvllMnmmTrq "Motor/Generator 1 Available Minimum Torque: This is an estimate of the minimum available motor torque including active deratings at the present motor speed.  This refers to the motor rotor output and excludes any gearbox that may be attached to the m...";
CM_ BO_ 2565967102 "Motor/Generator 1 Inverter Rate Limits Active 1";
CM_ SG_ 2565967102 MtrGnrtr1InvrtrRtLmtsAtv1CRC "Motor/Generator 1 Inverter Rate Limits Active 1 CRC: The CRC is defined as follows: • Length: 8 bits • Polynomial: x^8+x^5+x^3+x^2+x+1 • Initial Value: FFh • Input Data Reflection: Not reflected • Result Data Reflection: Not reflected • XOR value: FF...";
CM_ SG_ 2565967102 MtrGnrtr1InvrtrRtLmtsAtv1Cntr "Motor/Generator 1 Inverter Rate Limits Active 1 Counter: The message counter is used to detect situations where the transmitting ECU malfunction repeats the same frame all the time. The receiver of the information may use the counter parameter to det...";
CM_ SG_ 2565967102 MtGt1IvtRtLtsAtvAstSpdRtLt "Motor/Generator 1 Inverter Rate Limits Active Absolute Speed Rate Limit: The active maximum rate of change for the absolute motor speed  (i.e. |d(speed)|/dt) in all control modes of this motor/generator inverter instance. Refer to SPN 10171 [Referenc...";
CM_ SG_ 2565967102 MtGt1IvtRtLtsAtvAstTqRtLt "Motor/Generator 1 Inverter Rate Limits Active Absolute Torque Rate Limit: The active maximum rate of change for the absolute motor torque (i.e. |d(torque)|/dt) in all control modes of this motor/generator inverter instance. Refer to SPN 10170 [Refere...";
CM_ BO_ 2565967358 "Motor/Generator 2 Inverter Status 2";
CM_ SG_ 2565967358 MtrGnrtr2InvrtrStts2CRC "Motor/Generator 2 Inverter Status 2 CRC: The CRC is defined as follows: • Length: 8 bits • Polynomial: x^8+x^5+x^3+x^2+x+1 • Initial Value: FFh • Input Data Reflection: Not reflected • Result Data Reflection: Not reflected • XOR value: FFhSAE makes n...";
CM_ SG_ 2565967358 MtrGnrtr2InvrtrStts2Cntr "Motor/Generator 2 Inverter Status 2 Counter: The message counter is used to detect situations where the transmitting ECU malfunction repeats the same frame all the time. The receiver of the information may use the counter parameter to detect this sit...";
CM_ SG_ 2565967358 MtrGnrtr2AvllMxmmTrq "Motor/Generator 2 Available Maximum Torque: This is an estimate of the maximum available motor torque including active deratings at the present motor speed.  This refers to the motor rotor output and excludes any gearbox that may be attached to the m...";
CM_ SG_ 2565967358 MtrGnrtr2AvllMnmmTrq "Motor/Generator 2 Available Minimum Torque: This is an estimate of the minimum available motor torque including active deratings at the present motor speed.  This refers to the motor rotor output and excludes any gearbox that may be attached to the m...";
CM_ BO_ 2565967614 "Motor/Generator 2 Inverter Rate Limits Active 1";
CM_ SG_ 2565967614 MtrGnrtr2InvrtrRtLmtsAtv1CRC "Motor/Generator 2 Inverter Rate Limits Active 1 CRC: The CRC is defined as follows: • Length: 8 bits • Polynomial: x^8+x^5+x^3+x^2+x+1 • Initial Value: FFh • Input Data Reflection: Not reflected • Result Data Reflection: Not reflected • XOR value: FF...";
CM_ SG_ 2565967614 MtrGnrtr2InvrtrRtLmtsAtv1Cntr "Motor/Generator 2 Inverter Rate Limits Active 1 Counter: The message counter is used to detect situations where the transmitting ECU malfunction repeats the same frame all the time. The receiver of the information may use the counter parameter to det...";
CM_ SG_ 2565967614 MtGt2IvtRtLtsAtvAstSpdRtLt "Motor/Generator 2 Inverter Rate Limits Active Absolute Speed Rate Limit: The Inverter reports its active maximum rate of change for the absolute motor speed  (i.e. |d(speed)|/dt) in all control modes. Refer to SPN 10237 [Reference Speed] to convert %...";
CM_ SG_ 2565967614 MtGt2IvtRtLtsAtvAstTqRtLt "Motor/Generator 2 Inverter Rate Limits Active Absolute Torque Rate Limit: The inverter reports its active maximum rate of change for the absolute motor torque (i.e. |d(torque)|/dt) in all control modes. Refer to SPN 10236 [Reference Torque] to conver...";
CM_ BO_ 2297532414 "Impostor PG Alert";
CM_ SG_ 2297532414 ImpostorPGEventDetectionCounter "Impostor PG Event Detection Counter: For a given detected impostor PG being reported on, this parameter indicates the number of impostor message sequences that have been detected by the legitimate sender since the counter was last reset.The counter i...";
CM_ SG_ 2297532414 ImpostorPGSourceAddress "Impostor PG Source Address: Indicates the source address from which an impostor is broadcasting the detected PG. If no impostor PG(s) have been detected, this parameter shall be set to a value of 254.";
CM_ SG_ 2297532414 ImpostorPGDestinationAddress "Impostor PG Destination Address: Indicates the destination address to which the impostor is broadcasting the detected PG. If no impostor PG(s) have been detected, this parameter shall be set to a value of 254.";
CM_ SG_ 2297532414 ImpostorPGN "Impostor PGN: This parameter identifies an unexpected duplicate PG (message) being broadcast from a source address that is already rightfully claimed. If no impostor PG(s) have been detected, each byte of this parameter shall be set to a value of 255...";
CM_ SG_ 2297532414 TimeSinceLastImposterPGDetected "Time Since Last Imposter PG Detected: For the given impostor PG being reported on, this parameter indicates how much time has elapsed since the impostor PG instance was last detected during the current ECU power cycle, i.e. when the last attack ended...";
CM_ BO_ 2364641534 "High Voltage Energy Storage Pack 1 Status 2";
CM_ SG_ 2364641534 HVESP1DshrgPwrLmtDtSttfChrg "HVESP1 Discharge Power Limit Due to State of Charge: Indicates whether or not discharge power of this HVES instance is being limited due to state of charge.This parameter is for one of multiple packs in an HVESS.  If there is only one pack in the sys...";
CM_ SG_ 2364641534 HVESP1DshrgPwrLmtDtBttrTmprtr "HVESP1 Discharge Power Limit Due to Battery Temperature: Indicates whether or not discharge power of this HVES instance is being limited due to battery temperature.This parameter is for one of multiple packs in an HVESS.  If there is only one pack in...";
CM_ SG_ 2364641534 HVESP1DsPwLtDtBttDstCdt "HVESP1 Discharge Power Limit Due to Battery Diagnostic Condition: Indicates whether or not discharge power of this HVES instance is being limited due to a battery diagnostic condition.This parameter is for one of multiple packs in an HVESS.  If there...";
CM_ SG_ 2364641534 HVESP1DshrgPwrLmtDtBttrrCllVltg "HVESP1 Discharge Power Limit Due to Battery or Cell Voltage: Indicates whether or not discharge power of this HVES instance is being limited due to a battery or cell voltage level.This parameter is for one of multiple packs in an HVESS.  If there is ...";
CM_ SG_ 2364641534 HVESP1DshrgPwrLmtDtBttrCrrnt "HVESP1 Discharge Power Limit Due to Battery Current: Indicates whether or not discharge power of this HVES instance is being limited due to battery current.This parameter is for one of multiple packs in an HVESS.  If there is only one pack in the sys...";
CM_ SG_ 2364641534 HVESP1DshrgPwrLmtDtnUndfndCs "HVESP1 Discharge Power Limit Due to an Undefined Cause: Indicates whether or not discharge power of this HVES instance is being limited due to an undefined cause.This parameter is for one of multiple packs in an HVESS.  If there is only one pack in t...";
CM_ SG_ 2364641534 HVESP1ChrgPwrLmtDtSttfChrg "HVESP1 Charge Power Limit Due to State of Charge: Indicates whether or not charge power of this HVES instance is being limited due to state of charge.This parameter is for one of multiple packs in an HVESS.  If there is only one pack in the system, t...";
CM_ SG_ 2364641534 HVESP1ChrgPwrLmtDtBttrTmprtr "HVESP1 Charge Power Limit Due to Battery Temperature: Indicates whether or not charge power of this HVES instance is being limited due to battery temperature.This parameter is for one of multiple packs in an HVESS.  If there is only one pack in the s...";
CM_ SG_ 2364641534 HVESP1CPwLtDtBttDstCdt "HVESP1 Charge Power Limit Due to Battery Diagnostic Condition: Indicates whether or not charge power of this HVES instance is being limited due to a battery diagnostic condition.This parameter is for one of multiple packs in an HVESS.  If there is on...";
CM_ SG_ 2364641534 HVESP1ChrgPwrLmtDtBttrrCllVltg "HVESP1 Charge Power Limit Due to Battery or Cell Voltage: Indicates whether or not charge power of this HVES instance is being limited due to a battery or cell voltage level.This parameter is for one of multiple packs in an HVESS.  If there is only o...";
CM_ SG_ 2364641534 HVESP1ChrgPwrLmtDtBttrCrrnt "HVESP1 Charge Power Limit Due to Battery Current: Indicates whether or not charge power of this HVES instance is being limited due to battery current.This parameter is for one of multiple packs in an HVESS.  If there is only one pack in the system, t...";
CM_ SG_ 2364641534 HVESP1ChrgPwrLmtDtnUndfndCs "HVESP1 Charge Power Limit Due to an Undefined Cause: Indicates whether or not charge power of this HVES instance is being limited due to an undefined cause.This parameter is for one of multiple packs in an HVESS.  If there is only one pack in the sys...";
CM_ BO_ 2364641790 "High Voltage Energy Storage Pack 1 Data 1";
CM_ SG_ 2364641790 HVESP1AvailableDischargePower "HVESP1 Available Discharge Power: The rate at which this High Voltage Energy Storage Pack instance can currently provide energy for propulsion or other uses.This parameter is for one of multiple packs in an HVESS.  If there is only one pack in the sy...";
CM_ SG_ 2364641790 HVESP1AvailableChargePower "HVESP1 Available Charge Power: The rate at which this High Voltage Energy Storage Pack instance can currently receive energy from a regenerative or recharging system.This parameter is for one of multiple packs in an HVESS.  If there is only one pack ...";
CM_ SG_ 2364641790 HVESP1VoltageLevel "HVESP1 Voltage Level: The voltage level of this High Voltage Energy Storage Pack instance. This parameter should be synchronized with SPN 11053 (HVESP1 Current) such that a realized power value can be calculated.  If the HVES component physically con...";
CM_ SG_ 2364641790 HVESP1Current "HVESP1 Current: The current in or out of this High Voltage Energy Storage Pack instance. This parameter should be synchronized with SPN 11052 (HVESP1 Voltage Level) such that a realized power value can be calculated.  This parameter is defined from t...";
CM_ BO_ 2364642046 "High Voltage Energy Storage Pack 1 Data 2";
CM_ SG_ 2364642046 HVESP1FastUpdateStateofCharge "HVESP1 Fast Update State of Charge: Indicates this High Voltage Energy Storage Pack instance state of charge.  0% means no charge remaining, 100% means the system is fully charged in terms of physical limits of this energy storage pack instance.  Acc...";
CM_ SG_ 2364642046 HVESP1HighestCellVoltage "HVESP1 Highest Cell Voltage: The highest voltage level reported by any cell in this High Voltage Energy Storage Pack instance. If a single voltage sensor covers more than one cell, the value in this parameter is for the smallest group of cells measur...";
CM_ SG_ 2364642046 HVESP1LowestCellVoltage "HVESP1 Lowest Cell Voltage: The lowest voltage level reported by any cell in this High Voltage Energy Storage Pack instance. If a single voltage sensor covers more than one cell, the value in this parameter is for the smallest group of cells measured...";
CM_ SG_ 2364642046 HVESP1CllVltgDffrntlStts "HVESP1 Cell Voltage Differential Status: Indicates whether or not the differential between the highest and lowest cell voltages are within acceptable limits, according to this High Voltage Energy Storage Pack instance. The actual voltage differential...";
CM_ BO_ 2364642302 "High Voltage Energy Storage Pack 1 Data 3";
CM_ SG_ 2364642302 HVESP1HighestCellTemperature "HVESP1 Highest Cell Temperature: The highest temperature level reported by any cell in this High Voltage Energy Storage Pack instance.  If a single temperature sensor covers more than one cell, the value in this parameter is for the smallest group of...";
CM_ SG_ 2364642302 HVESP1LowestCellTemperature "HVESP1 Lowest Cell Temperature: The lowest temperature level reported by any cell in this High Voltage Energy Storage Pack instance.  If a single temperature sensor covers more than one cell, the value in this parameter is for the smallest group of c...";
CM_ SG_ 2364642302 HVESP1AverageCellTemperature "HVESP1 Average Cell Temperature: The average temperature level of all cells in this High Voltage Energy Storage Pack instance.This parameter is for one of multiple packs in an HVESS.  If there is only one pack in the system, the HVESS parameters shou...";
CM_ SG_ 2364642302 HVESP1CllTmprtrDffrntlStts "HVESP1 Cell Temperature Differential Status: Indicates whether or not the differential between the highest and lowest cell temperatures are within acceptable limits per this High Voltage Energy Storage Pack instance.  The actual temperature different...";
CM_ BO_ 2364642558 "High Voltage Energy Storage Pack 1 Data 4";
CM_ SG_ 2364642558 HVESP1DischargeCapacity "HVESP1 Discharge Capacity: The amount of stored electrical charge in this High Voltage Energy Storage Pack instance that is available for use by the hybrid system, i.e. “how full is the tank”.  See SPN 11090 (HVESP1 Discharge Energy Capacity) for kil...";
CM_ SG_ 2364642558 HVESP1ChargeCapacity "HVESP1 Charge Capacity: The amount of unused electrical charge storage in this High Voltage Energy Storage Pack instance that is available to be filled by charging, i.e. “how much empty space is remaining in the tank”.  See SPN 11091 (HVESP1 Charge E...";
CM_ SG_ 2364642558 HVESP1CellBalancingCount "HVESP1 Cell Balancing Count: The number of cells that are currently being balanced in this High Voltage Energy Storage Pack instance.This parameter is for one of multiple packs in an HVESS.  If there is only one pack in the system, the HVESS paramete...";
CM_ BO_ 2364642814 "High Voltage Energy Storage Pack 1 Data 5";
CM_ SG_ 2364642814 HVESP1DischargeCurrentLimit "HVESP1 Discharge Current Limit: The maximum permissible current flow out of this High Voltage Energy Storage Pack instance. This parameter is defined from the high voltage energy storage pack's point of view.A negative value represents current flowin...";
CM_ SG_ 2364642814 HVESP1ChargeCurrentLimit "HVESP1 Charge Current Limit: The maximum permissible current flow into this High Voltage Energy Storage Pack instance. This parameter is defined from the high voltage energy storage pack's point of view.A positive value represents current flowing int...";
CM_ SG_ 2364642814 HVESP1LowestCellStateofCharge "HVESP1 Lowest Cell State of Charge: Indicates the state of charge of the lowest-charged cell in this High Voltage Energy Storage Pack instance.  0% means no charge remaining, 100% means the cell is fully charged.   If a single state of charge value c...";
CM_ SG_ 2364642814 HVESP1HighestCellStateofCharge "HVESP1 Highest Cell State of Charge: Indicates the state of charge of the highest-charged cell in this High Voltage Energy Storage Pack instance.  0% means no charge remaining, 100% means the cell is fully charged.  If a single state of charge value ...";
CM_ BO_ 2364643070 "High Voltage Energy Storage Pack 1 Data 6";
CM_ SG_ 2364643070 HVESP1BusVoltage "HVESP1 Bus Voltage: The voltage level of the high voltage bus, as measured by this High Voltage Energy Storage Pack instance on the bus side (not the battery side) of its contactors.This parameter is for one of multiple packs in an HVESS.  If there i...";
CM_ SG_ 2364643070 HVESP1IgnitionVoltage "HVESP1 Ignition Voltage: The voltage level at the ignition input of this High Voltage Energy Storage Pack controller.This parameter is for one of multiple packs in an HVESS.  If there is only one pack in the system, the HVESS parameters should be use...";
CM_ SG_ 2364643070 HVESP1IntakeCoolantTemperature "HVESP1 Intake Coolant Temperature: The temperature of liquid coolant as it enters this High Voltage Energy Storage Pack instance.This parameter is for one of multiple packs in an HVESS.  If there is only one pack in the system, the HVESS parameters s...";
CM_ SG_ 2364643070 HVESP1OutletCoolantTemperature "HVESP1 Outlet Coolant Temperature: The temperature of liquid coolant as it exits this High Voltage Energy Storage Pack instance.This parameter is for one of multiple packs in an HVESS.  If there is only one pack in the system, the HVESS parameters sh...";
CM_ SG_ 2364643070 HVESP1ElectronicsTemperature "HVESP1 Electronics Temperature: The temperature of the electronics or control modules in this High Voltage Energy Storage Pack instance.  If there are multiple temperature sensors then this parameter would be set to the maximum sensor reading.This pa...";
CM_ SG_ 2364643070 HVESP1Temperature "HVESP1 Temperature: The temperature of this High Voltage Energy Storage Pack instance. The value may be determined from a unique sensor specifically for this purpose, or by aggregating various temperature sensor readings within the pack.This paramete...";
CM_ BO_ 2364643326 "High Voltage Energy Storage Pack 1 Status 1";
CM_ SG_ 2364643326 HVESP1HghVltgBsPstvCnttrStt "HVESP1 High-Voltage Bus (Positive) Contactor State: Position of this High Voltage Energy Storage Pack instance positive side bus contactor.  When this contactor is closed, the positive side of this HVES instance is connected to the positive side of t...";
CM_ SG_ 2364643326 HVESP1HghVltgBsNgtvCnttrStt "HVESP1 High-Voltage Bus (Negative) Contactor State: Position of this High Voltage Energy Storage Pack instance negative side bus contactor.  When this contactor is closed, the negative side of this HVES instance is connected to the negative side of t...";
CM_ SG_ 2364643326 HVESP1HghVltgBsDsnntFrwrnng "HVESP1 High-Voltage Bus Disconnect Forewarning: Indicates that this High Voltage Energy Storage Pack instance is about to disconnect from the high voltage bus due to unacceptable conditions.This parameter is for one of multiple packs in an HVESS. If ...";
CM_ SG_ 2364643326 HVESP1HghVltgBsPrChrgRlStt "HVESP1 High-Voltage Bus Pre-Charge Relay State: Position of the high-voltage bus contactor pre-charge relay.  When this relay is closed, this High Voltage Energy Storage Pack instance is bringing the high-voltage bus up to its operating level.This pa...";
CM_ SG_ 2364643326 HVESP1CntrfPkCnttrStt "HVESP1 Center of Pack Contactor State: Position of the center high-voltage contactor.  When this contactor is closed, the positive half of this High Voltage Energy Storage Pack instance is connected to the negative half.  If a system controls the pos...";
CM_ SG_ 2364643326 HVESP1HghVltgBsAtvIsltnTstStts "HVESP1 High-Voltage Bus Active Isolation Test Status: Status of the high-voltage bus electrical active isolation test as performed by this High Voltage Energy Storage Pack instance.This parameter is for one of multiple packs in an HVESS. If there is ...";
CM_ SG_ 2364643326 HVESP1HghVltgBsPssvIsltnTstStts "HVESP1 High-Voltage Bus Passive Isolation Test Status: Status of the high-voltage bus electrical passive isolation test as performed by this High Voltage Energy Storage Pack instance.This parameter is for one of multiple packs in an HVESS. If there i...";
CM_ SG_ 2364643326 HVESP1HVILStatus "HVESP1 HVIL Status: Status of the High Voltage Interlock Loop from the viewpoint of this High Voltage Energy Storage Pack instance.This parameter is for one of multiple packs in an HVESS. If there is only one pack in the system, the HVESS parameters ...";
CM_ SG_ 2364643326 HVESP1InertiaSwitchStatus "HVESP1 Inertia Switch Status: Switch indicating that an impact has been sensed by this High Voltage Energy Storage Pack instance. The impact indication may require action by another controller, or by this HVES instance itself.  For example, a control...";
CM_ SG_ 2364643326 HVESP1StateofChargeStatus "HVESP1 State of Charge Status: Status of this High Voltage Energy Storage Pack instance State of Charge (SOC).  Note:  A given HVES controller may not support all of the states.This parameter is for one of multiple packs in an HVESS.  If there is onl...";
CM_ SG_ 2364643326 HVESP1CellBalanceStatus "HVESP1 Cell Balance Status: Indicates whether or not the cells in this High Voltage Energy Storage Pack instance are balanced.This parameter is for one of multiple packs in an HVESS.  If there is only one pack in the system, the HVESS parameters shou...";
CM_ SG_ 2364643326 HVESP1CellBalancingActive "HVESP1 Cell Balancing Active: Indicates whether or not the cells in this High Voltage Energy Storage Pack instance are currently being balanced.This parameter is for one of multiple packs in an HVESS.  If there is only one pack in the system, the HVE...";
CM_ SG_ 2364643326 HVESP1InternalChargerStatus "HVESP1 Internal Charger Status: Indicates that the charger in this HVES instance is on.  External chargers may use the External Energy Source Connection Status (SPN 7898) and related SPs.This parameter is for one of multiple packs in an HVESS. If the...";
CM_ SG_ 2364643326 HVESP1HghVltgBsCnntnStts "HVESP1 High-Voltage Bus Connection Status: This parameter provides high level feedback on this High Voltage Energy Storage Pack instance high voltage bus connection.  For specific contactor information, see SPN 11075 (HVESP1 High-Voltage Bus (Positiv...";
CM_ SG_ 2364643326 HVESP1OperationalStatus "HVESP1 Operational Status: Provides feedback on where this High Voltage Energy Storage Pack instance is in its operating spectrum, and includes feedback in response to the Operation Consent [i.e. SPN 11035 (HVESP1 Operation Consent)] and Power Down C...";
CM_ BO_ 2364643582 "High Voltage Energy Storage Pack 1 Data 7";
CM_ SG_ 2364643582 HVESP1DischargeEnergyCapacity "HVESP1 Discharge Energy Capacity: The amount of stored electrical energy in this High Voltage Energy Storage Pack instance that is available for use by the hybrid system, i.e. “how full is the tank”.  See SPN 11062 (HVESP1 Discharge Capacity) for Amp...";
CM_ SG_ 2364643582 HVESP1ChargeEnergyCapacity "HVESP1 Charge Energy Capacity: The amount of unused electrical energy storage available to be filled by charging this High Voltage Energy Storage Pack instance, i.e. “how much empty space is remaining in the tank”.  See SPN 11063 (HVESP1 Charge Capac...";
CM_ SG_ 2364643582 HVESP1MaximumChargeVoltageLimit "HVESP1 Maximum Charge Voltage Limit: The maximum voltage level not to be exceeded while charging this High Voltage Energy Storage Pack instance.  If this parameter is not supported, the maximum charge voltage should be limited to SPN 11134 (HVESP1 Re...";
BA_DEF_ SG_  "SPN" INT 0 524287;
BA_DEF_ BO_  "VFrameFormat" ENUM  "StandardCAN","ExtendedCAN","reserved","J1939PG";
BA_DEF_DEF_  "SPN" 0;
BA_DEF_DEF_  "VFrameFormat" "J1939PG";
BA_ "SPN" SG_ 2364632574 ECd1IsttsPCstPssT 10017;
BA_ "SPN" SG_ 2364632574 ECd1IsttsIdtdMEtvPss 10018;
BA_ "SPN" SG_ 2364632574 ECd1IdtdMEtvPssCtV 10019;
BA_ "SPN" SG_ 2364632574 EngineCylinder1MisfireRate 1323;
BA_ "SPN" SG_ 2364632574 EngineCylinder1Temperature 10739;
BA_ "SPN" SG_ 2364632830 ECd2IsttsPCstPssT 10020;
BA_ "SPN" SG_ 2364632830 ECd2IsttsIdtdMEtvPss 10021;
BA_ "SPN" SG_ 2364632830 ECd2IdtdMEtvPssCtV 10022;
BA_ "SPN" SG_ 2364632830 EngineCylinder2MisfireRate 1324;
BA_ "SPN" SG_ 2364632830 EngineCylinder2Temperature 10740;
BA_ "SPN" SG_ 2364633086 ECd3IsttsPCstPssT 10023;
BA_ "SPN" SG_ 2364633086 ECd3IsttsIdtdMEtvPss 10024;
BA_ "SPN" SG_ 2364633086 ECd3IdtdMEtvPssCtV 10025;
BA_ "SPN" SG_ 2364633086 EngineCylinder3MisfireRate 1325;
BA_ "SPN" SG_ 2364633086 EngineCylinder3Temperature 10741;
BA_ "SPN" SG_ 2364633342 ECd4IsttsPCstPssT 10026;
BA_ "SPN" SG_ 2364633342 ECd4IsttsIdtdMEtvPss 10027;
BA_ "SPN" SG_ 2364633342 ECd4IdtdMEtvPssCtV 10028;
BA_ "SPN" SG_ 2364633342 EngineCylinder4MisfireRate 1326;
BA_ "SPN" SG_ 2364633342 EngineCylinder4Temperature 10742;
BA_ "SPN" SG_ 2364633598 ECd5IsttsPCstPssT 10029;
BA_ "SPN" SG_ 2364633598 ECd5IsttsIdtdMEtvPss 10030;
BA_ "SPN" SG_ 2364633598 ECd5IdtdMEtvPssCtV 10031;
BA_ "SPN" SG_ 2364633598 EngineCylinder5MisfireRate 1327;
BA_ "SPN" SG_ 2364633598 EngineCylinder5Temperature 10743;
BA_ "SPN" SG_ 2364633854 ECd6IsttsPCstPssT 10032;
BA_ "SPN" SG_ 2364633854 ECd6IsttsIdtdMEtvPss 10033;
BA_ "SPN" SG_ 2364633854 ECd6IdtdMEtvPssCtV 10034;
BA_ "SPN" SG_ 2364633854 EngineCylinder6MisfireRate 1328;
BA_ "SPN" SG_ 2364633854 EngineCylinder6Temperature 10744;
BA_ "SPN" SG_ 2364634110 ECd7IsttsPCstPssT 10035;
BA_ "SPN" SG_ 2364634110 ECd7IsttsIdtdMEtvPss 10036;
BA_ "SPN" SG_ 2364634110 ECd7IdtdMEtvPssCtV 10037;
BA_ "SPN" SG_ 2364634110 EngineCylinder7MisfireRate 1329;
BA_ "SPN" SG_ 2364634110 EngineCylinder7Temperature 10745;
BA_ "SPN" SG_ 2364634366 ECd8IsttsPCstPssT 10038;
BA_ "SPN" SG_ 2364634366 ECd8IsttsIdtdMEtvPss 10039;
BA_ "SPN" SG_ 2364634366 ECd8IdtdMEtvPssCtV 10040;
BA_ "SPN" SG_ 2364634366 EngineCylinder8MisfireRate 1330;
BA_ "SPN" SG_ 2364634366 EngineCylinder8Temperature 10746;
BA_ "SPN" SG_ 2364634622 ECd9IsttsPCstPssT 10041;
BA_ "SPN" SG_ 2364634622 ECd9IsttsIdtdMEtvPss 10042;
BA_ "SPN" SG_ 2364634622 ECd9IdtdMEtvPssCtV 10043;
BA_ "SPN" SG_ 2364634622 EngineCylinder9MisfireRate 1331;
BA_ "SPN" SG_ 2364634622 EngineCylinder9Temperature 10747;
BA_ "SPN" SG_ 2364634878 ECd10IsttsPCstPssT 10044;
BA_ "SPN" SG_ 2364634878 ECd10IsttsIdtdMEtvPss 10045;
BA_ "SPN" SG_ 2364634878 ECd10IdtdMEtvPssCtV 10046;
BA_ "SPN" SG_ 2364634878 EngineCylinder10MisfireRate 1332;
BA_ "SPN" SG_ 2364634878 EngineCylinder10Temperature 10748;
BA_ "SPN" SG_ 2364635134 ECd11IsttsPCstPssT 10047;
BA_ "SPN" SG_ 2364635134 ECd11IsttsIdtdMEtvPss 10048;
BA_ "SPN" SG_ 2364635134 ECd11IdtdMEtvPssCtV 10049;
BA_ "SPN" SG_ 2364635134 EngineCylinder11MisfireRate 1333;
BA_ "SPN" SG_ 2364635134 EngineCylinder11Temperature 10749;
BA_ "SPN" SG_ 2364635390 ECd12IsttsPCstPssT 10050;
BA_ "SPN" SG_ 2364635390 ECd12IsttsIdtdMEtvPss 10051;
BA_ "SPN" SG_ 2364635390 ECd12IdtdMEtvPssCtV 10052;
BA_ "SPN" SG_ 2364635390 EngineCylinder12MisfireRate 1334;
BA_ "SPN" SG_ 2364635390 EngineCylinder12Temperature 10750;
BA_ "SPN" SG_ 2364635646 ECd13IsttsPCstPssT 10053;
BA_ "SPN" SG_ 2364635646 ECd13IsttsIdtdMEtvPss 10054;
BA_ "SPN" SG_ 2364635646 ECd13IdtdMEtvPssCtV 10055;
BA_ "SPN" SG_ 2364635646 EngineCylinder13MisfireRate 1335;
BA_ "SPN" SG_ 2364635646 EngineCylinder13Temperature 10751;
BA_ "SPN" SG_ 2364635902 ECd14IsttsPCstPssT 10056;
BA_ "SPN" SG_ 2364635902 ECd14IsttsIdtdMEtvPss 10057;
BA_ "SPN" SG_ 2364635902 ECd14IdtdMEtvPssCtV 10058;
BA_ "SPN" SG_ 2364635902 EngineCylinder14MisfireRate 1336;
BA_ "SPN" SG_ 2364635902 EngineCylinder14Temperature 10752;
BA_ "SPN" SG_ 2364636158 ECd15IsttsPCstPssT 10059;
BA_ "SPN" SG_ 2364636158 ECd15IsttsIdtdMEtvPss 10060;
BA_ "SPN" SG_ 2364636158 ECd15IdtdMEtvPssCtV 10061;
BA_ "SPN" SG_ 2364636158 EngineCylinder15MisfireRate 1337;
BA_ "SPN" SG_ 2364636158 EngineCylinder15Temperature 10753;
BA_ "SPN" SG_ 2364636414 ECd16IsttsPCstPssT 10062;
BA_ "SPN" SG_ 2364636414 ECd16IsttsIdtdMEtvPss 10063;
BA_ "SPN" SG_ 2364636414 ECd16IdtdMEtvPssCtV 10064;
BA_ "SPN" SG_ 2364636414 EngineCylinder16MisfireRate 1338;
BA_ "SPN" SG_ 2364636414 EngineCylinder16Temperature 10754;
BA_ "SPN" SG_ 2364636670 ECd17IsttsPCstPssT 10065;
BA_ "SPN" SG_ 2364636670 ECd17IsttsIdtdMEtvPss 10066;
BA_ "SPN" SG_ 2364636670 ECd17IdtdMEtvPssCtV 10067;
BA_ "SPN" SG_ 2364636670 EngineCylinder17MisfireRate 1339;
BA_ "SPN" SG_ 2364636670 EngineCylinder17Temperature 10755;
BA_ "SPN" SG_ 2364636926 ECd18IsttsPCstPssT 10068;
BA_ "SPN" SG_ 2364636926 ECd18IsttsIdtdMEtvPss 10069;
BA_ "SPN" SG_ 2364636926 ECd18IdtdMEtvPssCtV 10070;
BA_ "SPN" SG_ 2364636926 EngineCylinder18MisfireRate 1340;
BA_ "SPN" SG_ 2364636926 EngineCylinder18Temperature 10756;
BA_ "SPN" SG_ 2364637182 ECd19IsttsPCstPssT 10071;
BA_ "SPN" SG_ 2364637182 ECd19IsttsIdtdMEtvPss 10072;
BA_ "SPN" SG_ 2364637182 ECd19IdtdMEtvPssCtV 10073;
BA_ "SPN" SG_ 2364637182 EngineCylinder19MisfireRate 1341;
BA_ "SPN" SG_ 2364637182 EngineCylinder19Temperature 10757;
BA_ "SPN" SG_ 2364637438 ECd20IsttsPCstPssT 10074;
BA_ "SPN" SG_ 2364637438 ECd20IsttsIdtdMEtvPss 10075;
BA_ "SPN" SG_ 2364637438 ECd20IdtdMEtvPssCtV 10076;
BA_ "SPN" SG_ 2364637438 EngineCylinder20MisfireRate 1342;
BA_ "SPN" SG_ 2364637438 EngineCylinder20Temperature 10758;
BA_ "SPN" SG_ 2364637694 MtrGnrtr1InvrtrMdFdk1CRC 10164;
BA_ "SPN" SG_ 2364637694 MtrGnrtr1InvrtrMdFdk1Cntr 10165;
BA_ "SPN" SG_ 2364637694 MtrGnrtr1InvrtrCntrlLmtsOvrrdMd 10166;
BA_ "SPN" SG_ 2364637694 MtrGnrtr1InvrtrCntrlStpntMd 10167;
BA_ "SPN" SG_ 2364637694 MtrGnrtr1InvrtrHVILStts 9103;
BA_ "SPN" SG_ 2565964542 MtrGnrtr1InvrtrLmtsAtvPwrCRC 10182;
BA_ "SPN" SG_ 2565964542 MtrGnrtr1InvrtrLmtsAtvPwrCntr 10183;
BA_ "SPN" SG_ 2565964798 MtrGnrtr1InvrtrLmtsAtvMhnlCRC 10194;
BA_ "SPN" SG_ 2565964798 MtrGnrtr1InvrtrLmtsAtvMhnlCntr 10195;
BA_ "SPN" SG_ 2565965054 MtrGnrtr1InvrtrLmtsAtvDCSdCRC 10210;
BA_ "SPN" SG_ 2565965054 MtrGnrtr1InvrtrLmtsAtvDCSdCntr 10211;
BA_ "SPN" SG_ 2565965310 MtrGnrtr1InvrtrSwthdIgntnVltg 9105;
BA_ "SPN" SG_ 2565965310 MtrGnrtr1InvrtrUnswthdSLIVltg 9117;
BA_ "SPN" SG_ 2364638974 MtrGnrtr2InvrtrMdFdk1CRC 10230;
BA_ "SPN" SG_ 2364638974 MtrGnrtr2InvrtrMdFdk1Cntr 10231;
BA_ "SPN" SG_ 2364638974 MtrGnrtr2InvrtrCntrlLmtsOvrrdMd 10232;
BA_ "SPN" SG_ 2364638974 MtrGnrtr2InvrtrCntrlStpntMd 10233;
BA_ "SPN" SG_ 2364638974 MtrGnrtr2InvrtrHVILStts 9104;
BA_ "SPN" SG_ 2565965822 MtrGnrtr2InvrtrLmtsAtvPwrCRC 10248;
BA_ "SPN" SG_ 2565965822 MtrGnrtr2InvrtrLmtsAtvPwrCntr 10249;
BA_ "SPN" SG_ 2565966078 MtrGnrtr2InvrtrLmtsAtvMhnlCRC 10260;
BA_ "SPN" SG_ 2565966078 MtrGnrtr2InvrtrLmtsAtvMhnlCntr 10261;
BA_ "SPN" SG_ 2565966334 MtrGnrtr2InvrtrLmtsAtvDCSdCRC 10276;
BA_ "SPN" SG_ 2565966334 MtrGnrtr2InvrtrLmtsAtvDCSdCntr 10277;
BA_ "SPN" SG_ 2565966590 MtrGnrtr2InvrtrSwthdIgntnVltg 9106;
BA_ "SPN" SG_ 2565966590 MtrGnrtr2InvrtrUnswthdSLIVltg 9118;
BA_ "SPN" SG_ 2365287678 MtrGnrtr2InvrtrRfrn1CRC 10234;
BA_ "SPN" SG_ 2365287678 MtrGnrtr2InvrtrRfrn1Cntr 10235;
BA_ "SPN" SG_ 2365287678 MtrGnrtr2InvrtrRfrnTrq 10236;
BA_ "SPN" SG_ 2365287678 MtrGnrtr2InvrtrRfrnSpd 10237;
BA_ "SPN" SG_ 2365287678 MtrGnrtr2InvrtrRfrnPwr 10238;
BA_ "SPN" SG_ 2365287934 MtrGnrtr2InvrtrStts1CRC 10239;
BA_ "SPN" SG_ 2365287934 MtrGnrtr2InvrtrStts1Cntr 10240;
BA_ "SPN" SG_ 2365287934 MotorGenerator2Speed 9058;
BA_ "SPN" SG_ 2365288190 MtrGnrtr2InvrtrRfrn2CRC 10266;
BA_ "SPN" SG_ 2365288190 MtrGnrtr2InvrtrRfrn2Cntr 10267;
BA_ "SPN" SG_ 2365288190 MtrGnrtr2InvrtrRfrnCrrnt 10268;
BA_ "SPN" SG_ 2365288190 MtrGnrtr2InvrtrRfrnVltg 10269;
BA_ "SPN" SG_ 2566615038 MtrGnrtr2InvrtrTmprtr1 10282;
BA_ "SPN" SG_ 2566615038 MtrGnrtr2InvrtrTmprtr2 10283;
BA_ "SPN" SG_ 2566615038 MtrGnrtr2InvrtrTmprtr3 10284;
BA_ "SPN" SG_ 2566615038 MtrGnrtr2InvrtrTmprtr4 10285;
BA_ "SPN" SG_ 2566615294 MotorGenerator2Temperature1 9060;
BA_ "SPN" SG_ 2566615294 MotorGenerator2Temperature2 10286;
BA_ "SPN" SG_ 2566615294 MotorGenerator2Temperature3 10287;
BA_ "SPN" SG_ 2566615294 MotorGenerator2Temperature4 10288;
BA_ "SPN" SG_ 2566615550 MotorGenerator1Temperature1 9059;
BA_ "SPN" SG_ 2566615550 MotorGenerator1Temperature2 10220;
BA_ "SPN" SG_ 2566615550 MotorGenerator1Temperature3 10221;
BA_ "SPN" SG_ 2566615550 MotorGenerator1Temperature4 10222;
BA_ "SPN" SG_ 2566615806 MtrGnrtr1InvrtrTmprtr1 10216;
BA_ "SPN" SG_ 2566615806 MtrGnrtr1InvrtrTmprtr2 10217;
BA_ "SPN" SG_ 2566615806 MtrGnrtr1InvrtrTmprtr3 10218;
BA_ "SPN" SG_ 2566615806 MtrGnrtr1InvrtrTmprtr4 10219;
BA_ "SPN" SG_ 2365289470 MtrGnrtr1InvrtrRfrn2CRC 10200;
BA_ "SPN" SG_ 2365289470 MtrGnrtr1InvrtrRfrn2Cntr 10201;
BA_ "SPN" SG_ 2365289470 MtrGnrtr1InvrtrRfrnCrrnt 10202;
BA_ "SPN" SG_ 2365289470 MtrGnrtr1InvrtrRfrnVltg 10203;
BA_ "SPN" SG_ 2365289726 MtrGnrtr1InvrtrStts1CRC 10173;
BA_ "SPN" SG_ 2365289726 MtrGnrtr1InvrtrStts1Cntr 10174;
BA_ "SPN" SG_ 2365289726 MotorGenerator1Torque 9061;
BA_ "SPN" SG_ 2365289726 MotorGenerator1Speed 9057;
BA_ "SPN" SG_ 2365289726 MtrGnrtr1InvrtrDCSdVltg 9101;
BA_ "SPN" SG_ 2365289726 MtrGnrtr1InvrtrDCSdCrrnt 10175;
BA_ "SPN" SG_ 2365289982 MtrGnrtr1InvrtrRfrn1CRC 10168;
BA_ "SPN" SG_ 2365289982 MtrGnrtr1InvrtrRfrn1Cntr 10169;
BA_ "SPN" SG_ 2365289982 MtrGnrtr1InvrtrRfrnTrq 10170;
BA_ "SPN" SG_ 2365289982 MtrGnrtr1InvrtrRfrnSpd 10171;
BA_ "SPN" SG_ 2365289982 MtrGnrtr1InvrtrRfrnPwr 10172;
BA_ "SPN" SG_ 2566616830 DetectionLocation1 10133;
BA_ "SPN" SG_ 2566616830 DetectionZone1 10132;
BA_ "SPN" SG_ 2566616830 ZoneAlarmStatus1 10134;
BA_ "SPN" SG_ 2566616830 DetectionLocation2 10136;
BA_ "SPN" SG_ 2566616830 DetectionZone2 10135;
BA_ "SPN" SG_ 2566616830 ZoneAlarmStatus2 10137;
BA_ "SPN" SG_ 2566616830 DetectionLocation3 10139;
BA_ "SPN" SG_ 2566616830 DetectionZone3 10138;
BA_ "SPN" SG_ 2566616830 ZoneAlarmStatus3 10140;
BA_ "SPN" SG_ 2566616830 PersonnelDetectSequenceCounter 10141;
BA_ "SPN" SG_ 2566617086 EngnClndr1CmprssnGmmRt 10077;
BA_ "SPN" SG_ 2566617086 EngnClndr1ExpnsnGmmRt 10078;
BA_ "SPN" SG_ 2566617086 EngnClndr2CmprssnGmmRt 10079;
BA_ "SPN" SG_ 2566617086 EngnClndr2ExpnsnGmmRt 10080;
BA_ "SPN" SG_ 2566617086 EngnClndr3CmprssnGmmRt 10081;
BA_ "SPN" SG_ 2566617086 EngnClndr3ExpnsnGmmRt 10082;
BA_ "SPN" SG_ 2566617086 EngnClndr4CmprssnGmmRt 10083;
BA_ "SPN" SG_ 2566617086 EngnClndr4ExpnsnGmmRt 10084;
BA_ "SPN" SG_ 2566617342 EngnClndr5CmprssnGmmRt 10085;
BA_ "SPN" SG_ 2566617342 EngnClndr5ExpnsnGmmRt 10086;
BA_ "SPN" SG_ 2566617342 EngnClndr6CmprssnGmmRt 10087;
BA_ "SPN" SG_ 2566617342 EngnClndr6ExpnsnGmmRt 10088;
BA_ "SPN" SG_ 2566617342 EngnClndr7CmprssnGmmRt 10089;
BA_ "SPN" SG_ 2566617342 EngnClndr7ExpnsnGmmRt 10090;
BA_ "SPN" SG_ 2566617342 EngnClndr8CmprssnGmmRt 10091;
BA_ "SPN" SG_ 2566617342 EngnClndr8ExpnsnGmmRt 10092;
BA_ "SPN" SG_ 2566617598 EngnClndr9CmprssnGmmRt 10093;
BA_ "SPN" SG_ 2566617598 EngnClndr9ExpnsnGmmRt 10094;
BA_ "SPN" SG_ 2566617598 EngnClndr10CmprssnGmmRt 10095;
BA_ "SPN" SG_ 2566617598 EngnClndr10ExpnsnGmmRt 10096;
BA_ "SPN" SG_ 2566617598 EngnClndr11CmprssnGmmRt 10097;
BA_ "SPN" SG_ 2566617598 EngnClndr11ExpnsnGmmRt 10098;
BA_ "SPN" SG_ 2566617598 EngnClndr12CmprssnGmmRt 10099;
BA_ "SPN" SG_ 2566617598 EngnClndr12ExpnsnGmmRt 10100;
BA_ "SPN" SG_ 2566617854 EngnClndr13CmprssnGmmRt 10101;
BA_ "SPN" SG_ 2566617854 EngnClndr13ExpnsnGmmRt 10102;
BA_ "SPN" SG_ 2566617854 EngnClndr14CmprssnGmmRt 10103;
BA_ "SPN" SG_ 2566617854 EngnClndr14ExpnsnGmmRt 10104;
BA_ "SPN" SG_ 2566617854 EngnClndr15CmprssnGmmRt 10105;
BA_ "SPN" SG_ 2566617854 EngnClndr15ExpnsnGmmRt 10106;
BA_ "SPN" SG_ 2566617854 EngnClndr16CmprssnGmmRt 10107;
BA_ "SPN" SG_ 2566617854 EngnClndr16ExpnsnGmmRt 10108;
BA_ "SPN" SG_ 2566618110 EngnClndr17CmprssnGmmRt 10109;
BA_ "SPN" SG_ 2566618110 EngnClndr17ExpnsnGmmRt 10110;
BA_ "SPN" SG_ 2566618110 EngnClndr18CmprssnGmmRt 10111;
BA_ "SPN" SG_ 2566618110 EngnClndr18ExpnsnGmmRt 10112;
BA_ "SPN" SG_ 2566618110 EngnClndr19CmprssnGmmRt 10113;
BA_ "SPN" SG_ 2566618110 EngnClndr19ExpnsnGmmRt 10114;
BA_ "SPN" SG_ 2566618110 EngnClndr20CmprssnGmmRt 10115;
BA_ "SPN" SG_ 2566618110 EngnClndr20ExpnsnGmmRt 10116;
BA_ "SPN" SG_ 2566618622 GnrtrClntPmpEnlStts 9833;
BA_ "SPN" SG_ 2566618622 GnrtrClntPmpCntrllrSttsRsnCd 9834;
BA_ "SPN" SG_ 2566618622 GnrtrClntPmpCntrllrCmmndStts 9835;
BA_ "SPN" SG_ 2566618622 GeneratorCoolantPumpMotorSpeed 9836;
BA_ "SPN" SG_ 2566618622 GnrtrClntPmpCntrlTmprtr 9837;
BA_ "SPN" SG_ 2566618622 GeneratorCoolantPumpPower 9838;
BA_ "SPN" SG_ 2566618622 GnrtrClntPmpSrvIndtr 9839;
BA_ "SPN" SG_ 2566618622 GnrtrClntPmpOprtngStts 9840;
BA_ "SPN" SG_ 2566618878 GeneratorCoolantFanEnableStatus 9820;
BA_ "SPN" SG_ 2566618878 GnrtrClntFnCntrllrSttsRsnCd 9821;
BA_ "SPN" SG_ 2566618878 GnrtrClntFnCntrllrCmmndStts 9822;
BA_ "SPN" SG_ 2566618878 GeneratorCoolantFanMotorSpeed 9823;
BA_ "SPN" SG_ 2566618878 GnrtrClntFnCntrlTmprtr 9824;
BA_ "SPN" SG_ 2566618878 GeneratorCoolantFanPower 9825;
BA_ "SPN" SG_ 2566618878 GnrtrClntFnSrvIndtr 9826;
BA_ "SPN" SG_ 2566618878 GnrtrClntFnOprtngStts 9827;
BA_ "SPN" SG_ 2566619134 WllStmltnPmpOlFltrDffrntlPrssr 9813;
BA_ "SPN" SG_ 2566619134 WllStmltnPmpOlFltrBpssSwthStts 9815;
BA_ "SPN" SG_ 2566619134 WllStmltnPmpGrBxOtltOlPrssr 9814;
BA_ "SPN" SG_ 2566619390 PrprgrmmdPTOGvrnrStSpd1 9778;
BA_ "SPN" SG_ 2566619390 PrprgrmmdPTOGvrnrStSpd2 9779;
BA_ "SPN" SG_ 2566619390 PrprgrmmdPTOGvrnrStSpd3 9780;
BA_ "SPN" SG_ 2566619390 PrprgrmmdPTOGvrnrStSpd4 9781;
BA_ "SPN" SG_ 2566619390 PrprgrmmdPTOGvrnrStSpd5 9782;
BA_ "SPN" SG_ 2566619390 PrprgrmmdPTOGvrnrStSpd6 9783;
BA_ "SPN" SG_ 2566619390 PrprgrmmdPTOGvrnrStSpd7 9784;
BA_ "SPN" SG_ 2566619390 PrprgrmmdPTOGvrnrStSpd8 9785;
BA_ "SPN" SG_ 2566619390 MinimumPTOGovernorSetSpeed 9786;
BA_ "SPN" SG_ 2566619390 MaximumPTOGovernorSetSpeed 9787;
BA_ "SPN" SG_ 2566619390 PTOGvrnrAlrtrOvrrdMxmmSpd 9788;
BA_ "SPN" SG_ 2566619646 OnBrdPrgrmmngInttECUAddrss 9776;
BA_ "SPN" SG_ 2566619646 OnBrdPrgrmmngInttRqst 9777;
BA_ "SPN" SG_ 2566619646 OnBrdPrgrmmngInttInht 9761;
BA_ "SPN" SG_ 2566620670 EngineIdleManagementStatus 9677;
BA_ "SPN" SG_ 2566620670 IdlMngmntPndngEvntTmRmnng 10149;
BA_ "SPN" SG_ 2566620670 EngnIdlMngmntEngnRstrtRsn 9678;
BA_ "SPN" SG_ 2566620670 EngnIdlMngmntEngnShtdwnRsn 9679;
BA_ "SPN" SG_ 2566621438 StationThrottlePositionMatch 9665;
BA_ "SPN" SG_ 2566621438 StationGearPositionMatch 9666;
BA_ "SPN" SG_ 2566621438 OprtrSttnAtvBttnStts 9667;
BA_ "SPN" SG_ 2566621438 TrollingModeButtonStatus 9668;
BA_ "SPN" SG_ 2566621438 EngnThrttlLvrSnhrnztnBttnStts 9669;
BA_ "SPN" SG_ 2566621438 GearLockoutButtonStatus 9670;
BA_ "SPN" SG_ 2566621438 SlowVesselModeButtonStatus 9671;
BA_ "SPN" SG_ 2566621438 OperatorStationActiveLampStatus 9672;
BA_ "SPN" SG_ 2566621438 TrollingModeLampStatus 9673;
BA_ "SPN" SG_ 2566621438 EngnThrttlLvrSnhrnztnLmpStts 9674;
BA_ "SPN" SG_ 2566621438 GearLockoutLampStatus 9675;
BA_ "SPN" SG_ 2566621438 SlowVesselModeLampStatus 9690;
BA_ "SPN" SG_ 2566621438 MarineHeavySeaModeEnable 12303;
BA_ "SPN" SG_ 2566621694 EngineOilPressure2 9653;
BA_ "SPN" SG_ 2365295358 HVESSBsVltgNgtvtChsssGrndVltg 9580;
BA_ "SPN" SG_ 2365295358 HVESSVltgLvlNgtvtChsssGrndVltg 9581;
BA_ "SPN" SG_ 2566622206 EconomyModeTotalHoursInactive 9578;
BA_ "SPN" SG_ 2566622206 EconomyModeTripHoursInactive 9579;
BA_ "SPN" SG_ 2566622462 EnmMdEstmtdInstntnsFlSvngsRt 9576;
BA_ "SPN" SG_ 2566622462 EMdEsttdIsttsFSvsRtPt 9577;
BA_ "SPN" SG_ 2566622718 EconomyModeTotalHoursActive 9574;
BA_ "SPN" SG_ 2566622718 EconomyModeTripHoursActive 9575;
BA_ "SPN" SG_ 2566622974 EconomyModeTotalFuelUsed 9572;
BA_ "SPN" SG_ 2566622974 EconomyModeTripFuelUsed 9573;
BA_ "SPN" SG_ 2566623230 EnmMdTtlEstmtdFlSvd 9570;
BA_ "SPN" SG_ 2566623230 EnmMdTrpEstmtdFlSvd 9571;
BA_ "SPN" SG_ 2552823550 MtrGnrtr1InvrtrRtLmtsRqst1CRC 10794;
BA_ "SPN" SG_ 2552823550 MtrGnrtr1InvrtrRtLmtsRqst1Cntr 10795;
BA_ "SPN" SG_ 2552823550 MtGt1IvtRtLtsRqstAstSpdRtLt 10796;
BA_ "SPN" SG_ 2552823550 MtGt1IvtRtLtsRqstAstTqRtLt 10797;
BA_ "SPN" SG_ 2552889086 MtrGnrtr2InvrtrRtLmtsRqst1CRC 10832;
BA_ "SPN" SG_ 2552889086 MtrGnrtr2InvrtrRtLmtsRqst1Cntr 10833;
BA_ "SPN" SG_ 2552889086 MtGt2IvtRtLtsRqstAstSpdRtLt 10834;
BA_ "SPN" SG_ 2552889086 MtGt2IvtRtLtsRqstAstTqRtLt 10835;
BA_ "SPN" SG_ 2351628030 HVESP1HghVltgBsCnntCmmnd 11029;
BA_ "SPN" SG_ 2351628030 HVESP1PowerDownCommand 11030;
BA_ "SPN" SG_ 2351628030 HVESP1HghVltgBsAtvIsltnTstCmmnd 11031;
BA_ "SPN" SG_ 2351628030 HVESP1HVtBsPssvIstTstCd 11032;
BA_ "SPN" SG_ 2351628030 HVESP1CellBalancingCommand 11033;
BA_ "SPN" SG_ 2351628030 HVESP1EnlIntrnlChrgrCmmnd 11034;
BA_ "SPN" SG_ 2351628030 HVESP1OperationConsent 11035;
BA_ "SPN" SG_ 2351628030 HVESP1HVtBsHSdRsstCtRqst 11036;
BA_ "SPN" SG_ 2351628030 HVESP1HVtBsLwSdRsstCtRqst 11037;
BA_ "SPN" SG_ 2351693566 HVESP2HghVltgBsCnntCmmnd 11145;
BA_ "SPN" SG_ 2351693566 HVESP2PowerDownCommand 11146;
BA_ "SPN" SG_ 2351693566 HVESP2HghVltgBsAtvIsltnTstCmmnd 11147;
BA_ "SPN" SG_ 2351693566 HVESP2HVtBsPssvIstTstCd 11148;
BA_ "SPN" SG_ 2351693566 HVESP2CellBalancingCommand 11149;
BA_ "SPN" SG_ 2351693566 HVESP2EnlIntrnlChrgrCmmnd 11150;
BA_ "SPN" SG_ 2351693566 HVESP2OperationConsent 11151;
BA_ "SPN" SG_ 2351693566 HVESP2HVtBsHSdRsstCtRqst 11152;
BA_ "SPN" SG_ 2351693566 HVESP2HVtBsLwSdRsstCtRqst 11153;
BA_ "SPN" SG_ 2351759102 HVESP3HghVltgBsCnntCmmnd 11261;
BA_ "SPN" SG_ 2351759102 HVESP3PowerDownCommand 11262;
BA_ "SPN" SG_ 2351759102 HVESP3HghVltgBsAtvIsltnTstCmmnd 11263;
BA_ "SPN" SG_ 2351759102 HVESP3HVtBsPssvIstTstCd 11264;
BA_ "SPN" SG_ 2351759102 HVESP3CellBalancingCommand 11265;
BA_ "SPN" SG_ 2351759102 HVESP3EnlIntrnlChrgrCmmnd 11266;
BA_ "SPN" SG_ 2351759102 HVESP3OperationConsent 11267;
BA_ "SPN" SG_ 2351759102 HVESP3HVtBsHSdRsstCtRqst 11268;
BA_ "SPN" SG_ 2351759102 HVESP3HVtBsLwSdRsstCtRqst 11269;
BA_ "SPN" SG_ 2351824638 HVESP4HghVltgBsCnntCmmnd 11377;
BA_ "SPN" SG_ 2351824638 HVESP4PowerDownCommand 11378;
BA_ "SPN" SG_ 2351824638 HVESP4HghVltgBsAtvIsltnTstCmmnd 11379;
BA_ "SPN" SG_ 2351824638 HVESP4HVtBsPssvIstTstCd 11380;
BA_ "SPN" SG_ 2351824638 HVESP4CellBalancingCommand 11381;
BA_ "SPN" SG_ 2351824638 HVESP4EnlIntrnlChrgrCmmnd 11382;
BA_ "SPN" SG_ 2351824638 HVESP4OperationConsent 11383;
BA_ "SPN" SG_ 2351824638 HVESP4HVtBsHSdRsstCtRqst 11384;
BA_ "SPN" SG_ 2351824638 HVESP4HVtBsLwSdRsstCtRqst 11385;
BA_ "SPN" SG_ 2351890174 HVESP5HghVltgBsCnntCmmnd 11493;
BA_ "SPN" SG_ 2351890174 HVESP5PowerDownCommand 11494;
BA_ "SPN" SG_ 2351890174 HVESP5HghVltgBsAtvIsltnTstCmmnd 11495;
BA_ "SPN" SG_ 2351890174 HVESP5HVtBsPssvIstTstCd 11496;
BA_ "SPN" SG_ 2351890174 HVESP5CellBalancingCommand 11497;
BA_ "SPN" SG_ 2351890174 HVESP5EnlIntrnlChrgrCmmnd 11498;
BA_ "SPN" SG_ 2351890174 HVESP5OperationConsent 11499;
BA_ "SPN" SG_ 2351890174 HVESP5HVtBsHSdRsstCtRqst 11500;
BA_ "SPN" SG_ 2351890174 HVESP5HVtBsLwSdRsstCtRqst 11501;
BA_ "SPN" SG_ 2351955710 HVESP6HghVltgBsCnntCmmnd 11609;
BA_ "SPN" SG_ 2351955710 HVESP6PowerDownCommand 11610;
BA_ "SPN" SG_ 2351955710 HVESP6HghVltgBsAtvIsltnTstCmmnd 11611;
BA_ "SPN" SG_ 2351955710 HVESP6HVtBsPssvIstTstCd 11612;
BA_ "SPN" SG_ 2351955710 HVESP6CellBalancingCommand 11613;
BA_ "SPN" SG_ 2351955710 HVESP6EnlIntrnlChrgrCmmnd 11614;
BA_ "SPN" SG_ 2351955710 HVESP6OperationConsent 11615;
BA_ "SPN" SG_ 2351955710 HVESP6HVtBsHSdRsstCtRqst 11616;
BA_ "SPN" SG_ 2351955710 HVESP6HVtBsLwSdRsstCtRqst 11617;
BA_ "SPN" SG_ 2555641598 EVSE1ConnectorLockCommand 12864;
BA_ "SPN" SG_ 2555707134 WinchPositionReset 12312;
BA_ "SPN" SG_ 2354446078 LiftAxle3PositionCommand 12300;
BA_ "SPN" SG_ 2354511614 MtrGnrtr2InvrtrCntrl2CRC 11764;
BA_ "SPN" SG_ 2354511614 MtrGnrtr2InvrtrCntrl2Cntr 11765;
BA_ "SPN" SG_ 2354511614 MtrGnrtr2InvrtrPIDCntrlAppllMd 11766;
BA_ "SPN" SG_ 2354511614 MtGt2IvtPIDCtNzdDtG 11767;
BA_ "SPN" SG_ 2354511614 MtGt2IvtPIDCtNzdItG 11768;
BA_ "SPN" SG_ 2354511614 MtGt2IvtPIDCtNzdPptG 11769;
BA_ "SPN" SG_ 2354511614 MtGt2IvtPIDCtFdFwdTq 12295;
BA_ "SPN" SG_ 2354577150 MtrGnrtr1InvrtrCntrl2CRC 11758;
BA_ "SPN" SG_ 2354577150 MtrGnrtr1InvrtrCntrl2Cntr 11759;
BA_ "SPN" SG_ 2354577150 MtrGnrtr1InvrtrPIDCntrlAppllMd 11760;
BA_ "SPN" SG_ 2354577150 MtGt1IvtPIDCtNzdDtG 11761;
BA_ "SPN" SG_ 2354577150 MtGt1IvtPIDCtNzdItG 11762;
BA_ "SPN" SG_ 2354577150 MtGt1IvtPIDCtNzdPptG 11763;
BA_ "SPN" SG_ 2354577150 MtGt1IvtPIDCtFdFwdTq 12294;
BA_ "SPN" SG_ 2488860414 HoistCommand 11729;
BA_ "SPN" SG_ 2488860414 HoistDetentStatus 11730;
BA_ "SPN" SG_ 2556034814 MtGt2IvtHVtBsAtvIstTstCd 10806;
BA_ "SPN" SG_ 2556034814 MtGt2IvtHVtBsPssvIstTstCd 10807;
BA_ "SPN" SG_ 2556034814 MtGt2IvtHVtBsHSdRsstCtRqst 10808;
BA_ "SPN" SG_ 2556034814 MtGt2IvtHVtBsLwSdRsstCtRqst 10809;
BA_ "SPN" SG_ 2556100350 MtGt1IvtHVtBsAtvIstTstCd 10768;
BA_ "SPN" SG_ 2556100350 MtGt1IvtHVtBsPssvIstTstCd 10769;
BA_ "SPN" SG_ 2556100350 MtGt1IvtHVtBsHSdRsstCtRqst 10770;
BA_ "SPN" SG_ 2556100350 MtGt1IvtHVtBsLwSdRsstCtRqst 10771;
BA_ "SPN" SG_ 2565966846 MtrGnrtr1InvrtrStts2CRC 10764;
BA_ "SPN" SG_ 2565966846 MtrGnrtr1InvrtrStts2Cntr 10765;
BA_ "SPN" SG_ 2565966846 MtrGnrtr1AvllMxmmTrq 10766;
BA_ "SPN" SG_ 2565966846 MtrGnrtr1AvllMnmmTrq 10767;
BA_ "SPN" SG_ 2565967102 MtrGnrtr1InvrtrRtLmtsAtv1CRC 10798;
BA_ "SPN" SG_ 2565967102 MtrGnrtr1InvrtrRtLmtsAtv1Cntr 10799;
BA_ "SPN" SG_ 2565967102 MtGt1IvtRtLtsAtvAstSpdRtLt 10800;
BA_ "SPN" SG_ 2565967102 MtGt1IvtRtLtsAtvAstTqRtLt 10801;
BA_ "SPN" SG_ 2565967358 MtrGnrtr2InvrtrStts2CRC 10802;
BA_ "SPN" SG_ 2565967358 MtrGnrtr2InvrtrStts2Cntr 10803;
BA_ "SPN" SG_ 2565967358 MtrGnrtr2AvllMxmmTrq 10804;
BA_ "SPN" SG_ 2565967358 MtrGnrtr2AvllMnmmTrq 10805;
BA_ "SPN" SG_ 2565967614 MtrGnrtr2InvrtrRtLmtsAtv1CRC 10836;
BA_ "SPN" SG_ 2565967614 MtrGnrtr2InvrtrRtLmtsAtv1Cntr 10837;
BA_ "SPN" SG_ 2565967614 MtGt2IvtRtLtsAtvAstSpdRtLt 10838;
BA_ "SPN" SG_ 2565967614 MtGt2IvtRtLtsAtvAstTqRtLt 10839;
BA_ "SPN" SG_ 2297532414 ImpostorPGEventDetectionCounter 10840;
BA_ "SPN" SG_ 2297532414 ImpostorPGSourceAddress 10841;
BA_ "SPN" SG_ 2297532414 ImpostorPGDestinationAddress 10842;
BA_ "SPN" SG_ 2297532414 ImpostorPGN 10843;
BA_ "SPN" SG_ 2297532414 TimeSinceLastImposterPGDetected 10844;
BA_ "SPN" SG_ 2364641534 HVESP1DshrgPwrLmtDtSttfChrg 11038;
BA_ "SPN" SG_ 2364641534 HVESP1DshrgPwrLmtDtBttrTmprtr 11039;
BA_ "SPN" SG_ 2364641534 HVESP1DsPwLtDtBttDstCdt 11040;
BA_ "SPN" SG_ 2364641534 HVESP1DshrgPwrLmtDtBttrrCllVltg 11041;
BA_ "SPN" SG_ 2364641534 HVESP1DshrgPwrLmtDtBttrCrrnt 11042;
BA_ "SPN" SG_ 2364641534 HVESP1DshrgPwrLmtDtnUndfndCs 11043;
BA_ "SPN" SG_ 2364641534 HVESP1ChrgPwrLmtDtSttfChrg 11044;
BA_ "SPN" SG_ 2364641534 HVESP1ChrgPwrLmtDtBttrTmprtr 11045;
BA_ "SPN" SG_ 2364641534 HVESP1CPwLtDtBttDstCdt 11046;
BA_ "SPN" SG_ 2364641534 HVESP1ChrgPwrLmtDtBttrrCllVltg 11047;
BA_ "SPN" SG_ 2364641534 HVESP1ChrgPwrLmtDtBttrCrrnt 11048;
BA_ "SPN" SG_ 2364641534 HVESP1ChrgPwrLmtDtnUndfndCs 11049;
BA_ "SPN" SG_ 2364641790 HVESP1AvailableDischargePower 11050;
BA_ "SPN" SG_ 2364641790 HVESP1AvailableChargePower 11051;
BA_ "SPN" SG_ 2364641790 HVESP1VoltageLevel 11052;
BA_ "SPN" SG_ 2364641790 HVESP1Current 11053;
BA_ "SPN" SG_ 2364642046 HVESP1FastUpdateStateofCharge 11054;
BA_ "SPN" SG_ 2364642046 HVESP1HighestCellVoltage 11055;
BA_ "SPN" SG_ 2364642046 HVESP1LowestCellVoltage 11056;
BA_ "SPN" SG_ 2364642046 HVESP1CllVltgDffrntlStts 11057;
BA_ "SPN" SG_ 2364642302 HVESP1HighestCellTemperature 11058;
BA_ "SPN" SG_ 2364642302 HVESP1LowestCellTemperature 11059;
BA_ "SPN" SG_ 2364642302 HVESP1AverageCellTemperature 11060;
BA_ "SPN" SG_ 2364642302 HVESP1CllTmprtrDffrntlStts 11061;
BA_ "SPN" SG_ 2364642558 HVESP1DischargeCapacity 11062;
BA_ "SPN" SG_ 2364642558 HVESP1ChargeCapacity 11063;
BA_ "SPN" SG_ 2364642558 HVESP1CellBalancingCount 11064;
BA_ "SPN" SG_ 2364642814 HVESP1DischargeCurrentLimit 11065;
BA_ "SPN" SG_ 2364642814 HVESP1ChargeCurrentLimit 11066;
BA_ "SPN" SG_ 2364642814 HVESP1LowestCellStateofCharge 11067;
BA_ "SPN" SG_ 2364642814 HVESP1HighestCellStateofCharge 11068;
BA_ "SPN" SG_ 2364643070 HVESP1BusVoltage 11069;
BA_ "SPN" SG_ 2364643070 HVESP1IgnitionVoltage 11070;
BA_ "SPN" SG_ 2364643070 HVESP1IntakeCoolantTemperature 11071;
BA_ "SPN" SG_ 2364643070 HVESP1OutletCoolantTemperature 11072;
BA_ "SPN" SG_ 2364643070 HVESP1ElectronicsTemperature 11073;
BA_ "SPN" SG_ 2364643070 HVESP1Temperature 11074;
BA_ "SPN" SG_ 2364643326 HVESP1HghVltgBsPstvCnttrStt 11075;
BA_ "SPN" SG_ 2364643326 HVESP1HghVltgBsNgtvCnttrStt 11076;
BA_ "SPN" SG_ 2364643326 HVESP1HghVltgBsDsnntFrwrnng 11077;
BA_ "SPN" SG_ 2364643326 HVESP1HghVltgBsPrChrgRlStt 11078;
BA_ "SPN" SG_ 2364643326 HVESP1CntrfPkCnttrStt 11079;
BA_ "SPN" SG_ 2364643326 HVESP1HghVltgBsAtvIsltnTstStts 11080;
BA_ "SPN" SG_ 2364643326 HVESP1HghVltgBsPssvIsltnTstStts 11081;
BA_ "SPN" SG_ 2364643326 HVESP1HVILStatus 11082;
BA_ "SPN" SG_ 2364643326 HVESP1InertiaSwitchStatus 11083;
BA_ "SPN" SG_ 2364643326 HVESP1StateofChargeStatus 11084;
BA_ "SPN" SG_ 2364643326 HVESP1CellBalanceStatus 11085;
BA_ "SPN" SG_ 2364643326 HVESP1CellBalancingActive 11086;
BA_ "SPN" SG_ 2364643326 HVESP1InternalChargerStatus 11087;
BA_ "SPN" SG_ 2364643326 HVESP1HghVltgBsCnntnStts 11088;
BA_ "SPN" SG_ 2364643326 HVESP1OperationalStatus 11089;
BA_ "SPN" SG_ 2364643582 HVESP1DischargeEnergyCapacity 11090;
BA_ "SPN" SG_ 2364643582 HVESP1ChargeEnergyCapacity 11091;
BA_ "SPN" SG_ 2364643582 HVESP1MaximumChargeVoltageLimit 11092;
